VERSION ""

NS_ :

BS_:

BU_: ETH

BO_ 989 CP_loggingSlow: 8 Vector__XXX
 SG_ CP_loggingSlowSelect M : 0|4@1+ (1,0) [0|0] "" Vector__XXX
 SG_ CP_UHF_chipState m3 : 4|3@1+ (1,0) [0|0] "" Vector__XXX
 SG_ CP_backCoverCounts m1 : 4|12@1+ (0.025,0) [0|0] "" Vector__XXX
 SG_ CP_nvm_dataValid m5 : 4|1@1+ (1,0) [0|0] "" Vector__XXX
 SG_ CP_pilotLowValue_intervalMax10s m2 : 4|12@1- (0.01,0) [0|0] "" Vector__XXX
 SG_ CP_proximityV_intervalMax10s m0 : 4|16@1+ (0.0001,0) [0|0] "" Vector__XXX
 SG_ CP_5vSwV m4 : 8|8@1+ (0.01968504,0) [0|0] "" Vector__XXX
 SG_ CP_UHF_rssi m3 : 8|8@1+ (1,0) [0|0] "" Vector__XXX
 SG_ CP_cpuUtilization_intervalMax10s m7 : 8|7@1+ (0.7874015748031497,0) [0|0] "" Vector__XXX
 SG_ CP_nvm_doorOpenCycles m5 : 8|16@1+ (1,0) [0|0] "" Vector__XXX
 SG_ CP_tlsMemoryUsage_intervalMax10s m6 : 8|7@1+ (0.7874015748031497,0) [0|0] "" Vector__XXX
 SG_ CP_UHF_rxOverflow m3 : 16|1@1+ (1,0) [0|0] "" Vector__XXX
 SG_ CP_backCover2Counts m1 : 16|12@1+ (0.025,0) [0|0] "" Vector__XXX
 SG_ CP_boardTemperature m4 : 16|8@1+ (1.29411764706,-50) [0|0] "" Vector__XXX
 SG_ CP_cpuUtilization_intervalMin10s m7 : 16|7@1+ (0.7874015748031497,0) [0|0] "" Vector__XXX
 SG_ CP_pilotLowValue_intervalMin10s m2 : 16|12@1- (0.01,0) [0|0] "" Vector__XXX
 SG_ CP_tlsMemoryUsage_intervalMin10s m6 : 16|7@1+ (0.7874015748031497,0) [0|0] "" Vector__XXX
 SG_ CP_UHF_rxNumBytes m3 : 17|8@1+ (1,0) [0|0] "" Vector__XXX
 SG_ CP_proximityV_intervalMin10s m0 : 20|16@1+ (0.0001,0) [0|0] "" Vector__XXX
 SG_ CP_acRetryTimeoutS m6 : 24|15@1+ (1,0) [0|0] "" Vector__XXX
 SG_ CP_doorButtonPressDurationMs m7 : 24|10@1+ (1,0) [0|0] "" Vector__XXX
 SG_ CP_nvm_doorCloseCycles m5 : 24|16@1+ (1,0) [0|0] "" Vector__XXX
 SG_ CP_refVoltage m4 : 24|8@1+ (0.0070588235,0) [0|0] "" Vector__XXX
 SG_ CP_UHF_selfTestRssi m3 : 25|8@1+ (1,0) [0|0] "" Vector__XXX
 SG_ CP_ivledState m1 : 28|2@1+ (1,0) [0|0] "" Vector__XXX
 SG_ CP_pilotHighValue_intervalMax10s m2 : 28|12@1- (0.01,0) [0|0] "" Vector__XXX
 SG_ CP_doorId_intervalMin10s m4 : 32|8@1+ (0.0196078431372549,0) [0|0] "" Vector__XXX
 SG_ CP_ivledV m1 : 32|8@1+ (0.01968504,0) [0|0] "" Vector__XXX
 SG_ CP_latchI m3 : 33|12@1+ (0.0025,0) [0|0] "" Vector__XXX
 SG_ CP_inductiveSensorBaseline m7 : 34|28@1+ (0.08083879947662354,0) [0|0] "" Vector__XXX
 SG_ CP_inlet1HarnessV m0 : 36|14@1+ (0.001,0) [0|0] "" Vector__XXX
 SG_ CP_acNextRetryTimeoutS m6 : 40|15@1+ (1,0) [0|0] "" Vector__XXX
 SG_ CP_doorId_intervalMax10s m4 : 40|8@1+ (0.0196078431372549,0) [0|0] "" Vector__XXX
 SG_ CP_nvm_doorOpen m5 : 40|1@1+ (1,0) [0|0] "" Vector__XXX
 SG_ CP_pilotHighValue_intervalMin10s m2 : 40|12@1- (0.01,0) [0|0] "" Vector__XXX
 SG_ CP_plcV m1 : 40|8@1+ (0.01294118,0) [0|0] "" Vector__XXX
 SG_ CP_nvm_doorPresent m5 : 41|1@1+ (1,0) [0|0] "" Vector__XXX
 SG_ CP_nvm_doorPresentValid m5 : 42|1@1+ (1,0) [0|0] "" Vector__XXX
 SG_ CP_nvm_badPilotDiodeDetected m5 : 43|1@1+ (1,0) [0|0] "" Vector__XXX
 SG_ CP_nvm_pilotDiodeFaultCount m5 : 44|3@1+ (1,0) [0|0] "" Vector__XXX
 SG_ CP_inlet1HarnessIdState m3 : 45|2@1+ (1,0) [0|0] "" Vector__XXX
 SG_ CP_doorOpenLimiterMaxCount m5 : 47|4@1+ (1,0) [0|0] "" Vector__XXX
 SG_ CP_inlet1HarnessIdValue m3 : 47|3@1+ (1,0) [0|0] "" Vector__XXX
 SG_ CP_sensorExtV m1 : 48|8@1+ (0.01968504,0) [0|0] "" Vector__XXX
 SG_ CP_inlet2HarnessIdState m3 : 50|2@1+ (1,0) [0|0] "" Vector__XXX
 SG_ CP_inlet2HarnessV m0 : 50|14@1+ (0.001,0) [0|0] "" Vector__XXX
 SG_ CP_doorOpenLimiterMaxRequestType m5 : 51|4@1+ (1,0) [0|0] "" Vector__XXX
 SG_ CP_faultLineV m2 : 52|10@1+ (0.004550576735092864,0) [0|0] "" Vector__XXX
 SG_ CP_inlet2HarnessIdValue m3 : 52|3@1+ (1,0) [0|0] "" Vector__XXX
 SG_ CP_doorCloseLimiterMaxCount m5 : 55|4@1+ (1,0) [0|0] "" Vector__XXX
 SG_ CP_inletHeaterState m3 : 55|2@1+ (1,0) [0|0] "" Vector__XXX
 SG_ CP_acNumRetries m6 : 56|8@1+ (1,0) [0|0] "" Vector__XXX
 SG_ CP_backCoverState m1 : 56|3@1+ (1,0) [0|0] "" Vector__XXX
 SG_ CP_inletHeaterDuty m3 : 57|7@1+ (1,0) [0|0] "" Vector__XXX
 SG_ CP_backCover2State m1 : 59|3@1+ (1,0) [0|0] "" Vector__XXX
 SG_ CP_doorCloseLimiterMaxRequestType m5 : 59|5@1+ (1,0) [0|0] "" Vector__XXX
 SG_ CP_faultLineSetByCP m2 : 62|1@1+ (1,0) [0|0] "" Vector__XXX

BO_ 990 FC_alertMatrix6: 8 Vector__XXX
 SG_ FC_a321_FCAlertPlaceholder : 0|1@1+ (1,0) [0|0] "" Vector__XXX

BO_ 991 UI_status2: 8 Vector__XXX
 SG_ UI_mobileAppStepCount : 0|16@1+ (1,0) [0|0] "" Vector__XXX
 SG_ UI_userRequestSnapshot : 16|1@1+ (1,0) [0|0] "" Vector__XXX
 SG_ UI_touchDetected : 17|1@1+ (1,0) [0|0] "" Vector__XXX
 SG_ UI_validDeviceForEUSummon : 18|1@1+ (1,0) [0|0] "" Vector__XXX
 SG_ UI_locatedAtHome : 19|1@1+ (1,0) [0|0] "" Vector__XXX
 SG_ UI_locatedAtWork : 20|1@1+ (1,0) [0|0] "" Vector__XXX
 SG_ UI_locatedAtFavorite : 21|1@1+ (1,0) [0|0] "" Vector__XXX
 SG_ UI_displayInDarkMode : 22|1@1+ (1,0) [0|0] "" Vector__XXX
 SG_ UI_userActivity : 23|1@1+ (1,0) [0|0] "" Vector__XXX
 SG_ UI_activeTouchPoints : 24|8@1+ (1,0) [0|0] "" Vector__XXX
 SG_ UI_linkState : 32|2@1+ (1,0) [0|0] "" Vector__XXX
 SG_ UI_sentryModeState : 34|3@1+ (1,0) [0|0] "" Vector__XXX
 SG_ UI_autopilotSentryRequest : 37|1@1+ (1,0) [0|0] "" Vector__XXX
 SG_ UI_mobileAppConnected : 38|1@1+ (1,0) [0|0] "" Vector__XXX
 SG_ UI_autoshiftDRState : 40|3@1+ (1,0) [0|0] "" Vector__XXX
 SG_ UI_wifiBtModuleType : 43|3@1+ (1,0) [0|0] "" Vector__XXX
 SG_ UI_sohHealthStatus : 46|2@1+ (1,0) [0|0] "" Vector__XXX
 SG_ UI_selfParkState : 48|8@1+ (1,0) [0|0] "" Vector__XXX
 SG_ UI_summonDeviceIndex : 56|2@1+ (1,0) [0|0] "" Vector__XXX
 SG_ UI_sentryModeCameraDetection : 58|1@1+ (1,0) [0|0] "" Vector__XXX
 SG_ UI_wakeOnIPActive : 59|1@1+ (1,0) [0|0] "" Vector__XXX
 SG_ UI_sapActive : 60|1@1+ (1,0) [0|0] "" Vector__XXX
 SG_ UI_sapClients : 61|1@1+ (1,0) [0|0] "" Vector__XXX
 SG_ UI_connectivityStandbyActive : 62|1@1+ (1,0) [0|0] "" Vector__XXX

BO_ 994 VCLEFT_lightStatus: 8 Vector__XXX
 SG_ VCLEFT_brakeLightStatus : 0|2@1+ (1,0) [0|0] "" Vector__XXX
 SG_ VCLEFT_tailLightStatus : 2|2@1+ (1,0) [0|0] "" Vector__XXX
 SG_ VCLEFT_turnSignalStatus : 4|2@1+ (1,0) [0|0] "" Vector__XXX
 SG_ VCLEFT_FLMapLightStatus : 6|2@1+ (1,0) [0|0] "" Vector__XXX
 SG_ VCLEFT_FRMapLightStatus : 8|2@1+ (1,0) [0|0] "" Vector__XXX
 SG_ VCLEFT_RLMapLightStatus : 10|2@1+ (1,0) [0|0] "" Vector__XXX
 SG_ VCLEFT_RRMapLightStatus : 12|2@1+ (1,0) [0|0] "" Vector__XXX
 SG_ VCLEFT_FLMapLightSwitchPressed : 14|1@1+ (1,0) [0|0] "" Vector__XXX
 SG_ VCLEFT_FRMapLightSwitchPressed : 15|1@1+ (1,0) [0|0] "" Vector__XXX
 SG_ VCLEFT_RLMapLightSwitchPressed : 16|1@1+ (1,0) [0|0] "" Vector__XXX
 SG_ VCLEFT_RRMapLightSwitchPressed : 17|1@1+ (1,0) [0|0] "" Vector__XXX
 SG_ VCLEFT_leftTurnTrailerLightStatus : 18|2@1+ (1,0) [0|0] "" Vector__XXX
 SG_ VCLEFT_rightTrnTrailerLightStatus : 20|2@1+ (1,0) [0|0] "" Vector__XXX
 SG_ VCLEFT_brakeTrailerLightStatus : 22|2@1+ (1,0) [0|0] "" Vector__XXX
 SG_ VCLEFT_tailTrailerLightStatus : 24|2@1+ (1,0) [0|0] "" Vector__XXX
 SG_ VCLEFT_fogTrailerLightStatus : 26|2@1+ (1,0) [0|0] "" Vector__XXX
 SG_ VCLEFT_frontRideHeight : 28|8@1- (1,0) [0|0] "" Vector__XXX
 SG_ VCLEFT_rearRideHeight : 36|8@1- (1,0) [0|0] "" Vector__XXX
 SG_ VCLEFT_leftDashRGBPowerRequest : 44|1@1+ (1,0) [0|0] "" Vector__XXX
 SG_ VCLEFT_rightDashRGBPowerRequest : 45|1@1+ (1,0) [0|0] "" Vector__XXX
 SG_ VCLEFT_trailerDetected : 46|2@1+ (1,0) [0|0] "" Vector__XXX
 SG_ VCLEFT_rideHeightSensorFault : 48|1@1+ (1,0) [0|0] "" Vector__XXX
 SG_ VCLEFT_reverseTrailerLightStatus : 49|2@1+ (1,0) [0|0] "" Vector__XXX
 SG_ VCLEFT_tailLightOutageStatus : 51|1@1+ (1,0) [0|0] "" Vector__XXX

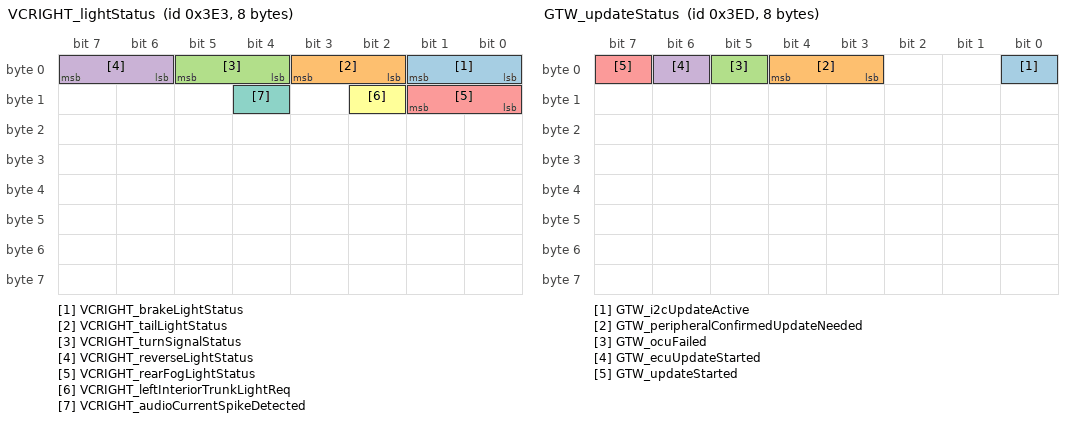
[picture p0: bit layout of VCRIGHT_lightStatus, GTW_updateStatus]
BO_ 995 VCRIGHT_lightStatus: 8 Vector__XXX
 SG_ VCRIGHT_brakeLightStatus : 0|2@1+ (1,0) [0|0] "" Vector__XXX
 SG_ VCRIGHT_tailLightStatus : 2|2@1+ (1,0) [0|0] "" Vector__XXX
 SG_ VCRIGHT_turnSignalStatus : 4|2@1+ (1,0) [0|0] "" Vector__XXX
 SG_ VCRIGHT_reverseLightStatus : 6|2@1+ (1,0) [0|0] "" Vector__XXX
 SG_ VCRIGHT_rearFogLightStatus : 8|2@1+ (1,0) [0|0] "" Vector__XXX
 SG_ VCRIGHT_leftInteriorTrunkLightReq : 10|1@1+ (1,0) [0|0] "" Vector__XXX
 SG_ VCRIGHT_audioCurrentSpikeDetected : 12|1@1+ (1,0) [0|0] "" Vector__XXX

BO_ 996 PCS2_alertMatrix: 8 Vector__XXX
 SG_ PCS2_matrixIndex M : 0|4@1+ (1,0) [0|0] "" Vector__XXX
 SG_ PCS2_a001_watchdogAlarmed m0 : 4|1@1+ (1,0) [0|0] "" Vector__XXX
 SG_ PCS2_a061_cycloBFaulted m1 : 4|1@1+ (1,0) [0|0] "" Vector__XXX
 SG_ PCS2_a121_insufficientCoolingDetected m2 : 4|1@1+ (1,0) [0|0] "" Vector__XXX
 SG_ PCS2_a002_canRationality m0 : 5|1@1+ (1,0) [0|0] "" Vector__XXX
 SG_ PCS2_a062_acVoltageNotPresent m1 : 5|1@1+ (1,0) [0|0] "" Vector__XXX
 SG_ PCS2_a122_dcacLifetimekVAhRecordError m2 : 5|1@1+ (1,0) [0|0] "" Vector__XXX
 SG_ PCS2_a003_softwareAssertion m0 : 6|1@1+ (1,0) [0|0] "" Vector__XXX
 SG_ PCS2_a063_chgUnknownGridConfig m1 : 6|1@1+ (1,0) [0|0] "" Vector__XXX
 SG_ PCS2_a123_DcdcBHvOverTemp m2 : 6|1@1+ (1,0) [0|0] "" Vector__XXX
 SG_ PCS2_a004_acL1NOverVoltage m0 : 7|1@1+ (1,0) [0|0] "" Vector__XXX
 SG_ PCS2_a064_dcdcATankParametersOutOfSpec m1 : 7|1@1+ (1,0) [0|0] "" Vector__XXX
 SG_ PCS2_a124_dcacItankSoftwareOC m2 : 7|1@1+ (1,0) [0|0] "" Vector__XXX
 SG_ PCS2_a005_acL1OverCurrent m0 : 8|1@1+ (1,0) [0|0] "" Vector__XXX
 SG_ PCS2_a065_dcdcBTankParametersOutOfSpec m1 : 8|1@1+ (1,0) [0|0] "" Vector__XXX
 SG_ PCS2_a125_cycloIdleShortingNeutral m2 : 8|1@1+ (1,0) [0|0] "" Vector__XXX
 SG_ PCS2_a006_acL2NOverVoltage m0 : 9|1@1+ (1,0) [0|0] "" Vector__XXX
 SG_ PCS2_a066_cycloATankParametersOutOfSpec m1 : 9|1@1+ (1,0) [0|0] "" Vector__XXX
 SG_ PCS2_a126_ipcSuccessiveLockGrabFailure m2 : 9|1@1+ (1,0) [0|0] "" Vector__XXX
 SG_ PCS2_a007_acL2OverCurrent m0 : 10|1@1+ (1,0) [0|0] "" Vector__XXX
 SG_ PCS2_a067_cycloBTankParametersOutOfSpec m1 : 10|1@1+ (1,0) [0|0] "" Vector__XXX
 SG_ PCS2_a127_cycloAgdpsHealthCheckFailed m2 : 10|1@1+ (1,0) [0|0] "" Vector__XXX
 SG_ PCS2_a008_acL3NOverVoltage m0 : 11|1@1+ (1,0) [0|0] "" Vector__XXX
 SG_ PCS2_a068_nvmSubsystemStalled m1 : 11|1@1+ (1,0) [0|0] "" Vector__XXX
 SG_ PCS2_a128_cycloBgdpsHealthCheckFailed m2 : 11|1@1+ (1,0) [0|0] "" Vector__XXX
 SG_ PCS2_a009_acL3OverCurrent m0 : 12|1@1+ (1,0) [0|0] "" Vector__XXX
 SG_ PCS2_a069_dcdcAlifetimeEnergyRecordFaulty m1 : 12|1@1+ (1,0) [0|0] "" Vector__XXX
 SG_ PCS2_a129_lossOfZcdEventControl m2 : 12|1@1+ (1,0) [0|0] "" Vector__XXX
 SG_ PCS2_a010_acLNOverCurrent m0 : 13|1@1+ (1,0) [0|0] "" Vector__XXX
 SG_ PCS2_a070_dcdcBlifetimeEnergyRecordFaulty m1 : 13|1@1+ (1,0) [0|0] "" Vector__XXX
 SG_ PCS2_a130_IONVMMServerRetryEvent m2 : 13|1@1+ (1,0) [0|0] "" Vector__XXX
 SG_ PCS2_a011_hvdcOverCurrent m0 : 14|1@1+ (1,0) [0|0] "" Vector__XXX
 SG_ PCS2_a071_hvBattBotSensorIrrational m1 : 14|1@1+ (1,0) [0|0] "" Vector__XXX
 SG_ PCS2_a131_microgridHeartbeatDetected m2 : 14|1@1+ (1,0) [0|0] "" Vector__XXX
 SG_ PCS2_a012_cycloATankOverCurrent m0 : 15|1@1+ (1,0) [0|0] "" Vector__XXX
 SG_ PCS2_a072_hvBattTopSensorIrrational m1 : 15|1@1+ (1,0) [0|0] "" Vector__XXX
 SG_ PCS2_a132_microgridDroopDetected m2 : 15|1@1+ (1,0) [0|0] "" Vector__XXX
 SG_ PCS2_a013_DcdcALv2OverTemp m0 : 16|1@1+ (1,0) [0|0] "" Vector__XXX
 SG_ PCS2_a073_hvBusBotSensorIrrational m1 : 16|1@1+ (1,0) [0|0] "" Vector__XXX
 SG_ PCS2_a133_unused m2 : 16|1@1+ (1,0) [0|0] "" Vector__XXX
 SG_ PCS2_a014_cycloBTankOverCurrent m0 : 17|1@1+ (1,0) [0|0] "" Vector__XXX
 SG_ PCS2_a074_hvBusTopSensorIrrational m1 : 17|1@1+ (1,0) [0|0] "" Vector__XXX
 SG_ PCS2_a134_unused m2 : 17|1@1+ (1,0) [0|0] "" Vector__XXX
 SG_ PCS2_a015_DcdcAHvOverTemp m0 : 18|1@1+ (1,0) [0|0] "" Vector__XXX
 SG_ PCS2_a075_hvBattFullSensorIrrational m1 : 18|1@1+ (1,0) [0|0] "" Vector__XXX
 SG_ PCS2_a135_backgroundTaskOverRun m2 : 18|1@1+ (1,0) [0|0] "" Vector__XXX
 SG_ PCS2_a016_dcdcATankOverCurrent m0 : 19|1@1+ (1,0) [0|0] "" Vector__XXX
 SG_ PCS2_a076_hvBusFullSensorIrrational m1 : 19|1@1+ (1,0) [0|0] "" Vector__XXX
 SG_ PCS2_a136_cycloAMosfetHealthCheckFailed m2 : 19|1@1+ (1,0) [0|0] "" Vector__XXX
 SG_ PCS2_a017_DcdcBLv2OverTemp m0 : 20|1@1+ (1,0) [0|0] "" Vector__XXX
 SG_ PCS2_a077_lvBusVoltSensorIrrational m1 : 20|1@1+ (1,0) [0|0] "" Vector__XXX
 SG_ PCS2_a137_cycloBMosfetHealthCheckFailed m2 : 20|1@1+ (1,0) [0|0] "" Vector__XXX
 SG_ PCS2_a018_dcdcBTankOverCurrent m0 : 21|1@1+ (1,0) [0|0] "" Vector__XXX
 SG_ PCS2_a078_acL1NVoltageOffsetIrrational m1 : 21|1@1+ (1,0) [0|0] "" Vector__XXX
 SG_ PCS2_a138_unused m2 : 21|1@1+ (1,0) [0|0] "" Vector__XXX
 SG_ PCS2_a019_DcacADcTempTooHigh m0 : 22|1@1+ (1,0) [0|0] "" Vector__XXX
 SG_ PCS2_a079_acL2NVoltageOffsetIrrational m1 : 22|1@1+ (1,0) [0|0] "" Vector__XXX
 SG_ PCS2_a139_unused m2 : 22|1@1+ (1,0) [0|0] "" Vector__XXX
 SG_ PCS2_a020_DcacBDcTempTooHigh m0 : 23|1@1+ (1,0) [0|0] "" Vector__XXX
 SG_ PCS2_a080_acL3NVoltageOffsetIrrational m1 : 23|1@1+ (1,0) [0|0] "" Vector__XXX
 SG_ PCS2_a140_dcdcHalfBusBalancerSaturated m2 : 23|1@1+ (1,0) [0|0] "" Vector__XXX
 SG_ PCS2_a021_powerRailUnderVoltage m0 : 24|1@1+ (1,0) [0|0] "" Vector__XXX
 SG_ PCS2_a081_acL1CurrentOffsetIrrational m1 : 24|1@1+ (1,0) [0|0] "" Vector__XXX
 SG_ PCS2_a141_boostOverCurrent m2 : 24|1@1+ (1,0) [0|0] "" Vector__XXX
 SG_ PCS2_a022_dcacEnableFunctionalityDisabled m0 : 25|1@1+ (1,0) [0|0] "" Vector__XXX
 SG_ PCS2_a082_acL2CurrentOffsetIrrational m1 : 25|1@1+ (1,0) [0|0] "" Vector__XXX
 SG_ PCS2_a142_AcLineGdpsUncalibrated m2 : 25|1@1+ (1,0) [0|0] "" Vector__XXX
 SG_ PCS2_a023_dcdcEnableFunctionalityDisabled m0 : 26|1@1+ (1,0) [0|0] "" Vector__XXX
 SG_ PCS2_a083_acL3CurrentOffsetIrrational m1 : 26|1@1+ (1,0) [0|0] "" Vector__XXX
 SG_ PCS2_a143_AcTankGdpsUncalibrated m2 : 26|1@1+ (1,0) [0|0] "" Vector__XXX
 SG_ PCS2_a024_DcacATxTempTooHigh m0 : 27|1@1+ (1,0) [0|0] "" Vector__XXX
 SG_ PCS2_a084_acNCurrentOffsetIrrational m1 : 27|1@1+ (1,0) [0|0] "" Vector__XXX
 SG_ PCS2_a144_DcTankGdpsUncalibrated m2 : 27|1@1+ (1,0) [0|0] "" Vector__XXX
 SG_ PCS2_a025_DcacBTxTempTooHigh m0 : 28|1@1+ (1,0) [0|0] "" Vector__XXX
 SG_ PCS2_a085_dcacEnableLineDeasserted m1 : 28|1@1+ (1,0) [0|0] "" Vector__XXX
 SG_ PCS2_a145_DcdcHvdcGdpsUncalibrated m2 : 28|1@1+ (1,0) [0|0] "" Vector__XXX
 SG_ PCS2_a026_AcConnectorTempTooHigh m0 : 29|1@1+ (1,0) [0|0] "" Vector__XXX
 SG_ PCS2_a086_dcacLVUnderVoltage m1 : 29|1@1+ (1,0) [0|0] "" Vector__XXX
 SG_ PCS2_a146_acLineSharedCurrentConnectionIssue m2 : 29|1@1+ (1,0) [0|0] "" Vector__XXX
 SG_ PCS2_a027_AmbientTempTooHigh m0 : 30|1@1+ (1,0) [0|0] "" Vector__XXX
 SG_ PCS2_a087_dcacLVOverVoltage m1 : 30|1@1+ (1,0) [0|0] "" Vector__XXX
 SG_ PCS2_a147_powerRailOverVoltage m2 : 30|1@1+ (1,0) [0|0] "" Vector__XXX
 SG_ PCS2_a028_CoolantTempTooHigh m0 : 31|1@1+ (1,0) [0|0] "" Vector__XXX
 SG_ PCS2_a088_chgInputVDropHigh m1 : 31|1@1+ (1,0) [0|0] "" Vector__XXX
 SG_ PCS2_a148_acRelayVoltageIrrational m2 : 31|1@1+ (1,0) [0|0] "" Vector__XXX
 SG_ PCS2_a029_DcacAAc1TempTooHigh m0 : 32|1@1+ (1,0) [0|0] "" Vector__XXX
 SG_ PCS2_a089_EndOfLineModeActivated m1 : 32|1@1+ (1,0) [0|0] "" Vector__XXX
 SG_ PCS2_a149_buckBoostFault m2 : 32|1@1+ (1,0) [0|0] "" Vector__XXX
 SG_ PCS2_a030_DcacAAc2TempTooHigh m0 : 33|1@1+ (1,0) [0|0] "" Vector__XXX
 SG_ PCS2_a090_DcdcLvMosfetTempTooHigh m1 : 33|1@1+ (1,0) [0|0] "" Vector__XXX
 SG_ PCS2_a150_dcdcBurstTimingNotMet m2 : 33|1@1+ (1,0) [0|0] "" Vector__XXX
 SG_ PCS2_a031_DcacBAc1TempTooHigh m0 : 34|1@1+ (1,0) [0|0] "" Vector__XXX
 SG_ PCS2_a091_DcdcTxWindingTempTooHigh m1 : 34|1@1+ (1,0) [0|0] "" Vector__XXX
 SG_ PCS2_a151_DcdcBLv1OverTemp m2 : 34|1@1+ (1,0) [0|0] "" Vector__XXX
 SG_ PCS2_a032_DcacBAc2TempTooHigh m0 : 35|1@1+ (1,0) [0|0] "" Vector__XXX
 SG_ PCS2_a092_dcdc_itankZcdIrrational m1 : 35|1@1+ (1,0) [0|0] "" Vector__XXX
 SG_ PCS2_a152_DcdcBLv3OverTemp m2 : 35|1@1+ (1,0) [0|0] "" Vector__XXX
 SG_ PCS2_a033_swCoreExcessiveUsage m0 : 36|1@1+ (1,0) [0|0] "" Vector__XXX
 SG_ PCS2_a093_cycloPwmsNotInterleaved m1 : 36|1@1+ (1,0) [0|0] "" Vector__XXX
 SG_ PCS2_a153_cyclo_itankZcdIrrational m2 : 36|1@1+ (1,0) [0|0] "" Vector__XXX
 SG_ PCS2_a034_lvBusOverVoltage m0 : 37|1@1+ (1,0) [0|0] "" Vector__XXX
 SG_ PCS2_a094_acChargingUnavailable m1 : 37|1@1+ (1,0) [0|0] "" Vector__XXX
 SG_ PCS2_a154_adcReferenceUncalibrated m2 : 37|1@1+ (1,0) [0|0] "" Vector__XXX
 SG_ PCS2_a035_lvBusUnderVoltage m0 : 38|1@1+ (1,0) [0|0] "" Vector__XXX
 SG_ PCS2_a095_powershareUnavailable m1 : 38|1@1+ (1,0) [0|0] "" Vector__XXX
 SG_ PCS2_a155_vcbatteryMia m2 : 38|1@1+ (1,0) [0|0] "" Vector__XXX
 SG_ PCS2_a036_hvBusOverVoltage m0 : 39|1@1+ (1,0) [0|0] "" Vector__XXX
 SG_ PCS2_a096_vcsuperMia m1 : 39|1@1+ (1,0) [0|0] "" Vector__XXX
 SG_ PCS2_a156_vcfrontMia m2 : 39|1@1+ (1,0) [0|0] "" Vector__XXX
 SG_ PCS2_a037_hvBusUnderVoltage m0 : 40|1@1+ (1,0) [0|0] "" Vector__XXX
 SG_ PCS2_a097_gtwMia m1 : 40|1@1+ (1,0) [0|0] "" Vector__XXX
 SG_ PCS2_a157_VC_pcsManagementMia m2 : 40|1@1+ (1,0) [0|0] "" Vector__XXX
 SG_ PCS2_a038_hvBusTopOverVoltage m0 : 41|1@1+ (1,0) [0|0] "" Vector__XXX
 SG_ PCS2_a098_eggright3Mia m1 : 41|1@1+ (1,0) [0|0] "" Vector__XXX
 SG_ PCS2_a158_DcdcHvMosfetTempTooHigh m2 : 41|1@1+ (1,0) [0|0] "" Vector__XXX
 SG_ PCS2_a039_hvBusTopUnderVoltage m0 : 42|1@1+ (1,0) [0|0] "" Vector__XXX
 SG_ PCS2_a099_LineChassisRmsOV m1 : 42|1@1+ (1,0) [0|0] "" Vector__XXX
 SG_ PCS2_a159_dcdcGdpsHealthCheckFailed m2 : 42|1@1+ (1,0) [0|0] "" Vector__XXX
 SG_ PCS2_a040_hvBusBotOverVoltage m0 : 43|1@1+ (1,0) [0|0] "" Vector__XXX
 SG_ PCS2_a100_LineToLineRmsOV m1 : 43|1@1+ (1,0) [0|0] "" Vector__XXX
 SG_ PCS2_a160_vcleftMia m2 : 43|1@1+ (1,0) [0|0] "" Vector__XXX
 SG_ PCS2_a041_hvBusBotUnderVoltage m0 : 44|1@1+ (1,0) [0|0] "" Vector__XXX
 SG_ PCS2_a101_LineChassisInstantaneousOV m1 : 44|1@1+ (1,0) [0|0] "" Vector__XXX
 SG_ PCS2_a161_vcrearMia m2 : 44|1@1+ (1,0) [0|0] "" Vector__XXX
 SG_ PCS2_a042_hvBattOverVoltage m0 : 45|1@1+ (1,0) [0|0] "" Vector__XXX
 SG_ PCS2_a102_LineToLineInstantaneousOV m1 : 45|1@1+ (1,0) [0|0] "" Vector__XXX
 SG_ PCS2_a162_cycloARoutineTankInductanceMeasurement m2 : 45|1@1+ (1,0) [0|0] "" Vector__XXX
 SG_ PCS2_a043_hvBattUnderVoltage m0 : 46|1@1+ (1,0) [0|0] "" Vector__XXX
 SG_ PCS2_a103_IsoTempSensorIrrational m1 : 46|1@1+ (1,0) [0|0] "" Vector__XXX
 SG_ PCS2_a163_cycloBRoutineTankInductanceMeasurement m2 : 46|1@1+ (1,0) [0|0] "" Vector__XXX
 SG_ PCS2_a044_hvBattTopOverVoltage m0 : 47|1@1+ (1,0) [0|0] "" Vector__XXX
 SG_ PCS2_a104_LineChassisRmsUV m1 : 47|1@1+ (1,0) [0|0] "" Vector__XXX
 SG_ PCS2_a164_dcdc_hwZcdFault1 m2 : 47|1@1+ (1,0) [0|0] "" Vector__XXX
 SG_ PCS2_a045_hvBattTopUnderVoltage m0 : 48|1@1+ (1,0) [0|0] "" Vector__XXX
 SG_ PCS2_a105_LineToLineRmsUV m1 : 48|1@1+ (1,0) [0|0] "" Vector__XXX
 SG_ PCS2_a165_dcdc_hwZcdFault2 m2 : 48|1@1+ (1,0) [0|0] "" Vector__XXX
 SG_ PCS2_a046_hvBattBotOverVoltage m0 : 49|1@1+ (1,0) [0|0] "" Vector__XXX
 SG_ PCS2_a106_systemNeutralChassisRmsOV m1 : 49|1@1+ (1,0) [0|0] "" Vector__XXX
 SG_ PCS2_a166_dcdcEnableLinePWMTripMisconfigured m2 : 49|1@1+ (1,0) [0|0] "" Vector__XXX
 SG_ PCS2_a047_hvBattBotUnderVoltage m0 : 50|1@1+ (1,0) [0|0] "" Vector__XXX
 SG_ PCS2_a107_cycloLostCurrentControl m1 : 50|1@1+ (1,0) [0|0] "" Vector__XXX
 SG_ PCS2_a167_unused m2 : 50|1@1+ (1,0) [0|0] "" Vector__XXX
 SG_ PCS2_a048_dcacOverVoltage m0 : 51|1@1+ (1,0) [0|0] "" Vector__XXX
 SG_ PCS2_a108_FunctionalTestModeActivated m1 : 51|1@1+ (1,0) [0|0] "" Vector__XXX
 SG_ PCS2_a168_gridFormVoltageDropped m2 : 51|1@1+ (1,0) [0|0] "" Vector__XXX
 SG_ PCS2_a049_dcacUnderVoltage m0 : 52|1@1+ (1,0) [0|0] "" Vector__XXX
 SG_ PCS2_a109_ACSurgeProtectionTriggered m1 : 52|1@1+ (1,0) [0|0] "" Vector__XXX
 SG_ PCS2_a169_cycloMosfetHealthCheckMeasuredHalfPrdAsymmetric m2 : 52|1@1+ (1,0) [0|0] "" Vector__XXX
 SG_ PCS2_a050_vcPcsDCDCInterfaceMia m0 : 53|1@1+ (1,0) [0|0] "" Vector__XXX
 SG_ PCS2_a110_acCurrentIsLimited m1 : 53|1@1+ (1,0) [0|0] "" Vector__XXX
 SG_ PCS2_a170_unused m2 : 53|1@1+ (1,0) [0|0] "" Vector__XXX
 SG_ PCS2_a051_bmsMia m0 : 54|1@1+ (1,0) [0|0] "" Vector__XXX
 SG_ PCS2_a111_unused m1 : 54|1@1+ (1,0) [0|0] "" Vector__XXX
 SG_ PCS2_a171_unused m2 : 54|1@1+ (1,0) [0|0] "" Vector__XXX
 SG_ PCS2_a052_cpMia m0 : 55|1@1+ (1,0) [0|0] "" Vector__XXX
 SG_ PCS2_a112_chgInputVDropTooHigh m1 : 55|1@1+ (1,0) [0|0] "" Vector__XXX
 SG_ PCS2_a172_llcDcdcLvBusContention m2 : 55|1@1+ (1,0) [0|0] "" Vector__XXX
 SG_ PCS2_a053_hvDcdcControlMIA m0 : 56|1@1+ (1,0) [0|0] "" Vector__XXX
 SG_ PCS2_a113_dcdcTransientCapabilityImpacted m1 : 56|1@1+ (1,0) [0|0] "" Vector__XXX
 SG_ PCS2_a173_unused m2 : 56|1@1+ (1,0) [0|0] "" Vector__XXX
 SG_ PCS2_a054_uiMia m0 : 57|1@1+ (1,0) [0|0] "" Vector__XXX
 SG_ PCS2_a114_hvBusEstimatedImpedanceLow m1 : 57|1@1+ (1,0) [0|0] "" Vector__XXX
 SG_ PCS2_a174_unused m2 : 57|1@1+ (1,0) [0|0] "" Vector__XXX
 SG_ PCS2_a055_dcdcATankUncalibrated m0 : 58|1@1+ (1,0) [0|0] "" Vector__XXX
 SG_ PCS2_a115_chgWallPowerRemoval m1 : 58|1@1+ (1,0) [0|0] "" Vector__XXX
 SG_ PCS2_a175_LVUVSurgePowerEvent m2 : 58|1@1+ (1,0) [0|0] "" Vector__XXX
 SG_ PCS2_a056_dcdcBTankUncalibrated m0 : 59|1@1+ (1,0) [0|0] "" Vector__XXX
 SG_ PCS2_a116_chgPersistentFault m1 : 59|1@1+ (1,0) [0|0] "" Vector__XXX
 SG_ PCS2_a057_cycloATankUncalibrated m0 : 60|1@1+ (1,0) [0|0] "" Vector__XXX
 SG_ PCS2_a117_vcrightMia m1 : 60|1@1+ (1,0) [0|0] "" Vector__XXX
 SG_ PCS2_a058_cycloBTankUncalibrated m0 : 61|1@1+ (1,0) [0|0] "" Vector__XXX
 SG_ PCS2_a118_dcdcFailedToPrechargeToTarget m1 : 61|1@1+ (1,0) [0|0] "" Vector__XXX
 SG_ PCS2_a059_dcdcEnableLineDeasserted m0 : 62|1@1+ (1,0) [0|0] "" Vector__XXX
 SG_ PCS2_a119_useMaxCapForHvImpedanceEstimation m1 : 62|1@1+ (1,0) [0|0] "" Vector__XXX
 SG_ PCS2_a060_cycloAFaulted m0 : 63|1@1+ (1,0) [0|0] "" Vector__XXX
 SG_ PCS2_a120_triggerOdin m1 : 63|1@1+ (1,0) [0|0] "" Vector__XXX

BO_ 997 DIR_alertMatrix4: 8 Vector__XXX
 SG_ DIR_a202_excessHeatUnavailable : 9|1@1+ (1,0) [0|0] "" Vector__XXX
 SG_ DIR_a225_tmpEstPlausibility : 32|1@1+ (1,0) [0|0] "" Vector__XXX
 SG_ DIR_a229_busVsensorOverCAN : 36|1@1+ (1,0) [0|0] "" Vector__XXX
 SG_ DIR_a233_diMsgMissed : 40|1@1+ (1,0) [0|0] "" Vector__XXX
 SG_ DIR_a234_pcsMIA : 41|1@1+ (1,0) [0|0] "" Vector__XXX
 SG_ DIR_a236_tasMIA : 43|1@1+ (1,0) [0|0] "" Vector__XXX
 SG_ DIR_a240_clearFusesRoutine : 47|1@1+ (1,0) [0|0] "" Vector__XXX
 SG_ DIR_a241_systemThermallyLimited : 48|1@1+ (1,0) [0|0] "" Vector__XXX
 SG_ DIR_a242_spinDownLearning : 49|1@1+ (1,0) [0|0] "" Vector__XXX
 SG_ DIR_a243_ecuLogAvailable : 50|1@1+ (1,0) [0|0] "" Vector__XXX
 SG_ DIR_a244_mechSafeStateApplied : 51|1@1+ (1,0) [0|0] "" Vector__XXX
 SG_ DIR_a245_mechSafeStatePreWarn : 52|1@1+ (1,0) [0|0] "" Vector__XXX
 SG_ DIR_a246_recoveryAtSpeedError : 53|1@1+ (1,0) [0|0] "" Vector__XXX
 SG_ DIR_a247_rotorOffsetError : 54|1@1+ (1,0) [0|0] "" Vector__XXX
 SG_ DIR_a248_vehicleSpeedLimited : 55|1@1+ (1,0) [0|0] "" Vector__XXX
 SG_ DIR_a249_highStatorTempFromResist : 56|1@1+ (1,0) [0|0] "" Vector__XXX
 SG_ DIR_a250_preregulatorRail : 57|1@1+ (1,0) [0|0] "" Vector__XXX
 SG_ DIR_a251_oilPumpService : 58|1@1+ (1,0) [0|0] "" Vector__XXX
 SG_ DIR_a252_currentCoreFallback : 59|1@1+ (1,0) [0|0] "" Vector__XXX
 SG_ DIR_a253_lvBoostedRail : 60|1@1+ (1,0) [0|0] "" Vector__XXX
 SG_ DIR_a254_activeDischargeRail : 61|1@1+ (1,0) [0|0] "" Vector__XXX
 SG_ DIR_a255_currentGainFallback : 62|1@1+ (1,0) [0|0] "" Vector__XXX

BO_ 1000 EPBR_alertMatrix: 8 Vector__XXX
 SG_ EPBR_matrixIndex M : 0|4@1+ (1,0) [0|0] "" Vector__XXX
 SG_ EPBR_a001_WatchdogReset m0 : 4|1@1+ (1,0) [0|0] "" Vector__XXX
 SG_ EPBR_a061_XCPConnected m1 : 4|1@1+ (1,0) [0|0] "" Vector__XXX
 SG_ EPBR_a121_nDriveFault m2 : 4|1@1+ (1,0) [0|0] "" Vector__XXX
 SG_ EPBR_a181_TooSteepGradeToPark m3 : 4|1@1+ (1,0) [0|0] "" Vector__XXX
 SG_ EPBR_a241_diOutputLocked m4 : 4|1@1+ (1,0) [0|0] "" Vector__XXX
 SG_ EPBR_a301_oocSpeedViolation m5 : 4|1@1+ (1,0) [0|0] "" Vector__XXX
 SG_ EPBR_a361_espBrakeSwitchInvalid m6 : 4|1@1+ (1,0) [0|0] "" Vector__XXX
 SG_ EPBR_a002_PowerLossReset m0 : 5|1@1+ (1,0) [0|0] "" Vector__XXX
 SG_ EPBR_a062_XCPWasConnected m1 : 5|1@1+ (1,0) [0|0] "" Vector__XXX
 SG_ EPBR_a122_Oc m2 : 5|1@1+ (1,0) [0|0] "" Vector__XXX
 SG_ EPBR_a182_OneEPBAppliedUnsecEnv m3 : 5|1@1+ (1,0) [0|0] "" Vector__XXX
 SG_ EPBR_a242_hvOutputLocked m4 : 5|1@1+ (1,0) [0|0] "" Vector__XXX
 SG_ EPBR_a302_csmLongRelease m5 : 5|1@1+ (1,0) [0|0] "" Vector__XXX
 SG_ EPBR_a362_ibstPressedEspNotPressedMismatch m6 : 5|1@1+ (1,0) [0|0] "" Vector__XXX
 SG_ EPBR_a003_SWAssertion m0 : 6|1@1+ (1,0) [0|0] "" Vector__XXX
 SG_ EPBR_a063_SwitchFault m1 : 6|1@1+ (1,0) [0|0] "" Vector__XXX
 SG_ EPBR_a123_Uc m2 : 6|1@1+ (1,0) [0|0] "" Vector__XXX
 SG_ EPBR_a183_cdpNotAvailable m3 : 6|1@1+ (1,0) [0|0] "" Vector__XXX
 SG_ EPBR_a243_bdwUnavailable m4 : 6|1@1+ (1,0) [0|0] "" Vector__XXX
 SG_ EPBR_a303_clampingOccuredEarly m5 : 6|1@1+ (1,0) [0|0] "" Vector__XXX
 SG_ EPBR_a363_ibstNotPressedEspPressedMismatch m6 : 6|1@1+ (1,0) [0|0] "" Vector__XXX
 SG_ EPBR_a064_busSleepReqTimeout m1 : 7|1@1+ (1,0) [0|0] "" Vector__XXX
 SG_ EPBR_a124_calOutOfBounds m2 : 7|1@1+ (1,0) [0|0] "" Vector__XXX
 SG_ EPBR_a184_dynamicParkAbort m3 : 7|1@1+ (1,0) [0|0] "" Vector__XXX
 SG_ EPBR_a244_WinchModeActive m4 : 7|1@1+ (1,0) [0|0] "" Vector__XXX
 SG_ EPBR_a304_rearSeatControllerEFuseTrip m5 : 7|1@1+ (1,0) [0|0] "" Vector__XXX
 SG_ EPBR_a364_espMasterCylCompOverThreshold m6 : 7|1@1+ (1,0) [0|0] "" Vector__XXX
 SG_ EPBR_a005_CANTXError m0 : 8|1@1+ (1,0) [0|0] "" Vector__XXX
 SG_ EPBR_a125_IdleVMismatch m2 : 8|1@1+ (1,0) [0|0] "" Vector__XXX
 SG_ EPBR_a185_summonAborted m3 : 8|1@1+ (1,0) [0|0] "" Vector__XXX
 SG_ EPBR_a245_serviceModeActive m4 : 8|1@1+ (1,0) [0|0] "" Vector__XXX
 SG_ EPBR_a305_premiumAmpEFuseTrip m5 : 8|1@1+ (1,0) [0|0] "" Vector__XXX
 SG_ EPBR_a365_TooSteepToParkWithTrailerWarning m6 : 8|1@1+ (1,0) [0|0] "" Vector__XXX
 SG_ EPBR_a006_CANTX_cyclicError m0 : 9|1@1+ (1,0) [0|0] "" Vector__XXX
 SG_ EPBR_a126_MotorNVoltLow m2 : 9|1@1+ (1,0) [0|0] "" Vector__XXX
 SG_ EPBR_a186_externalParkAbort m3 : 9|1@1+ (1,0) [0|0] "" Vector__XXX
 SG_ EPBR_a246_idleFaultApply m4 : 9|1@1+ (1,0) [0|0] "" Vector__XXX
 SG_ EPBR_a366_TooSteepToParkWithTrailerUnSecEnv m6 : 9|1@1+ (1,0) [0|0] "" Vector__XXX
 SG_ EPBR_a127_MotorNVoltHigh m2 : 10|1@1+ (1,0) [0|0] "" Vector__XXX
 SG_ EPBR_a187_cdpDynamic m3 : 10|1@1+ (1,0) [0|0] "" Vector__XXX
 SG_ EPBR_a247_csmDynamicApplyRetry m4 : 10|1@1+ (1,0) [0|0] "" Vector__XXX
 SG_ EPBR_a128_MotorPVoltHigh m2 : 11|1@1+ (1,0) [0|0] "" Vector__XXX
 SG_ EPBR_a188_epbDynamic m3 : 11|1@1+ (1,0) [0|0] "" Vector__XXX
 SG_ EPBR_a248_csmDynamicApplyFailed m4 : 11|1@1+ (1,0) [0|0] "" Vector__XXX
 SG_ EPBR_a129_ICR_MIA m2 : 12|1@1+ (1,0) [0|0] "" Vector__XXX
 SG_ EPBR_a189_epbDynamicParkCanceled m3 : 12|1@1+ (1,0) [0|0] "" Vector__XXX
 SG_ EPBR_a249_idleFaultRelease m4 : 12|1@1+ (1,0) [0|0] "" Vector__XXX
 SG_ EPBR_a190_csmApplyDegraded m3 : 13|1@1+ (1,0) [0|0] "" Vector__XXX
 SG_ EPBR_a250_WinchModeCanceled m4 : 13|1@1+ (1,0) [0|0] "" Vector__XXX
 SG_ EPBR_a191_csmReleaseDegraded m3 : 14|1@1+ (1,0) [0|0] "" Vector__XXX
 SG_ EPBR_a251_currentVarianceHigh m4 : 14|1@1+ (1,0) [0|0] "" Vector__XXX
 SG_ EPBR_a012_CPUReset m0 : 15|1@1+ (1,0) [0|0] "" Vector__XXX
 SG_ EPBR_a252_winchModePending m4 : 15|1@1+ (1,0) [0|0] "" Vector__XXX
 SG_ EPBR_a013_AlertManagerFault m0 : 16|1@1+ (1,0) [0|0] "" Vector__XXX
 SG_ EPBR_a253_esmReleaseBlocked m4 : 16|1@1+ (1,0) [0|0] "" Vector__XXX
 SG_ EPBR_a134_NvOv m2 : 17|1@1+ (1,0) [0|0] "" Vector__XXX
 SG_ EPBR_a254_showStalkParkButtonFaultOnUi m4 : 17|1@1+ (1,0) [0|0] "" Vector__XXX
 SG_ EPBR_a015_NVMMError m0 : 18|1@1+ (1,0) [0|0] "" Vector__XXX
 SG_ EPBR_a135_NvUv m2 : 18|1@1+ (1,0) [0|0] "" Vector__XXX
 SG_ EPBR_a195_parkForDriverIsLeaving m3 : 18|1@1+ (1,0) [0|0] "" Vector__XXX
 SG_ EPBR_a016_NVMMRecordError m0 : 19|1@1+ (1,0) [0|0] "" Vector__XXX
 SG_ EPBR_a136_PvOv m2 : 19|1@1+ (1,0) [0|0] "" Vector__XXX
 SG_ EPBR_a196_freeRollModeActive m3 : 19|1@1+ (1,0) [0|0] "" Vector__XXX
 SG_ EPBR_a256_epbSystemApply m4 : 19|1@1+ (1,0) [0|0] "" Vector__XXX
 SG_ EPBR_a137_PvUv m2 : 20|1@1+ (1,0) [0|0] "" Vector__XXX
 SG_ EPBR_a197_freeRollModeAtSpeed m3 : 20|1@1+ (1,0) [0|0] "" Vector__XXX
 SG_ EPBR_a138_NvmDualFailure m2 : 21|1@1+ (1,0) [0|0] "" Vector__XXX
 SG_ EPBR_a198_holdClampComplete m3 : 21|1@1+ (1,0) [0|0] "" Vector__XXX
 SG_ EPBR_a139_NvmRedundancyLoss m2 : 22|1@1+ (1,0) [0|0] "" Vector__XXX
 SG_ EPBR_a140_NvmSlowWrite m2 : 23|1@1+ (1,0) [0|0] "" Vector__XXX
 SG_ EPBR_a200_PmUnparkNotAllowed m3 : 23|1@1+ (1,0) [0|0] "" Vector__XXX
 SG_ EPBR_a021_TaskSchedulerError m0 : 24|1@1+ (1,0) [0|0] "" Vector__XXX
 SG_ EPBR_a081_APP_MIA m1 : 24|1@1+ (1,0) [0|0] "" Vector__XXX
 SG_ EPBR_a141_invalidState m2 : 24|1@1+ (1,0) [0|0] "" Vector__XXX
 SG_ EPBR_a261_winchModeWithoutSteering m4 : 24|1@1+ (1,0) [0|0] "" Vector__XXX
 SG_ EPBR_a022_TaskInitError m0 : 25|1@1+ (1,0) [0|0] "" Vector__XXX
 SG_ EPBR_a082_VCRIGHT_IPC_MIA m1 : 25|1@1+ (1,0) [0|0] "" Vector__XXX
 SG_ EPBR_a202_remoteEpbConfigIncompatible m3 : 25|1@1+ (1,0) [0|0] "" Vector__XXX
 SG_ EPBR_a262_cannotPrepareWinchMode m4 : 25|1@1+ (1,0) [0|0] "" Vector__XXX
 SG_ EPBR_a083_VCLEFT_IPC_MIA m1 : 26|1@1+ (1,0) [0|0] "" Vector__XXX
 SG_ EPBR_a203_hwBrakeTypeMismatch m3 : 26|1@1+ (1,0) [0|0] "" Vector__XXX
 SG_ EPBR_a263_epbRecoveryPark m4 : 26|1@1+ (1,0) [0|0] "" Vector__XXX
 SG_ EPBR_a084_TPMS_MIA m1 : 27|1@1+ (1,0) [0|0] "" Vector__XXX
 SG_ EPBR_a264_winchModeDeactivated m4 : 27|1@1+ (1,0) [0|0] "" Vector__XXX
 SG_ EPBR_a085_CCCM_MIA m1 : 28|1@1+ (1,0) [0|0] "" Vector__XXX
 SG_ EPBR_a086_VCBATT_MIA m1 : 29|1@1+ (1,0) [0|0] "" Vector__XXX
 SG_ EPBR_a087_DIREL_MIA m1 : 30|1@1+ (1,0) [0|0] "" Vector__XXX
 SG_ EPBR_a088_DIRER_MIA m1 : 31|1@1+ (1,0) [0|0] "" Vector__XXX
 SG_ EPBR_a029_CoreDump m0 : 32|1@1+ (1,0) [0|0] "" Vector__XXX
 SG_ EPBR_a089_IBST_MIA m1 : 32|1@1+ (1,0) [0|0] "" Vector__XXX
 SG_ EPBR_a030_ECULogUploadRequest m0 : 33|1@1+ (1,0) [0|0] "" Vector__XXX
 SG_ EPBR_a090_APS_MIA m1 : 33|1@1+ (1,0) [0|0] "" Vector__XXX
 SG_ EPBR_a210_parkForDriverIsLeavingDebug m3 : 33|1@1+ (1,0) [0|0] "" Vector__XXX
 SG_ EPBR_a031_UDSActive m0 : 34|1@1+ (1,0) [0|0] "" Vector__XXX
 SG_ EPBR_a091_CMPD_MIA m1 : 34|1@1+ (1,0) [0|0] "" Vector__XXX
 SG_ EPBR_a092_VCSEATD_MIA m1 : 35|1@1+ (1,0) [0|0] "" Vector__XXX
 SG_ EPBR_a272_vhclPwrStateMsmtch m4 : 35|1@1+ (1,0) [0|0] "" Vector__XXX
 SG_ EPBR_a093_VCSEATP_MIA m1 : 36|1@1+ (1,0) [0|0] "" Vector__XXX
 SG_ EPBR_a094_EPAS3P_MIA m1 : 37|1@1+ (1,0) [0|0] "" Vector__XXX
 SG_ EPBR_a095_CHG_MIA m1 : 38|1@1+ (1,0) [0|0] "" Vector__XXX
 SG_ EPBR_a096_OCS1P_MIA m1 : 39|1@1+ (1,0) [0|0] "" Vector__XXX
 SG_ EPBR_a216_SPI_MIA_debugData1 m3 : 39|1@1+ (1,0) [0|0] "" Vector__XXX
 SG_ EPBR_a097_CMP_MIA m1 : 40|1@1+ (1,0) [0|0] "" Vector__XXX
 SG_ EPBR_a217_SPI_MIA_debugData2 m3 : 40|1@1+ (1,0) [0|0] "" Vector__XXX
 SG_ EPBR_a098_DIR_MIA m1 : 41|1@1+ (1,0) [0|0] "" Vector__XXX
 SG_ EPBR_a099_PARK_MIA m1 : 42|1@1+ (1,0) [0|0] "" Vector__XXX
 SG_ EPBR_a100_CANbus_MIA m1 : 43|1@1+ (1,0) [0|0] "" Vector__XXX
 SG_ EPBR_a041_HighCPULoad m0 : 44|1@1+ (1,0) [0|0] "" Vector__XXX
 SG_ EPBR_a101_PM_MIA m1 : 44|1@1+ (1,0) [0|0] "" Vector__XXX
 SG_ EPBR_a042_HighStackUsage m0 : 45|1@1+ (1,0) [0|0] "" Vector__XXX
 SG_ EPBR_a102_PTC_MIA m1 : 45|1@1+ (1,0) [0|0] "" Vector__XXX
 SG_ EPBR_a043_Task1msError m0 : 46|1@1+ (1,0) [0|0] "" Vector__XXX
 SG_ EPBR_a103_CP_MIA m1 : 46|1@1+ (1,0) [0|0] "" Vector__XXX
 SG_ EPBR_a044_Task10msError m0 : 47|1@1+ (1,0) [0|0] "" Vector__XXX
 SG_ EPBR_a104_DAS_MIA m1 : 47|1@1+ (1,0) [0|0] "" Vector__XXX
 SG_ EPBR_a045_Task100msError m0 : 48|1@1+ (1,0) [0|0] "" Vector__XXX
 SG_ EPBR_a105_TAS_MIA m1 : 48|1@1+ (1,0) [0|0] "" Vector__XXX
 SG_ EPBR_a225_epbActiveDecel m3 : 48|1@1+ (1,0) [0|0] "" Vector__XXX
 SG_ EPBR_a046_Task1000msError m0 : 49|1@1+ (1,0) [0|0] "" Vector__XXX
 SG_ EPBR_a106_PCS_MIA m1 : 49|1@1+ (1,0) [0|0] "" Vector__XXX
 SG_ EPBR_a107_BMS_MIA m1 : 50|1@1+ (1,0) [0|0] "" Vector__XXX
 SG_ EPBR_a108_DIF_MIA m1 : 51|1@1+ (1,0) [0|0] "" Vector__XXX
 SG_ EPBR_a109_RCM_MIA m1 : 52|1@1+ (1,0) [0|0] "" Vector__XXX
 SG_ EPBR_a110_GTW_MIA m1 : 53|1@1+ (1,0) [0|0] "" Vector__XXX
 SG_ EPBR_a170_12vOv m2 : 53|1@1+ (1,0) [0|0] "" Vector__XXX
 SG_ EPBR_a350_ensOutOfRange m5 : 53|1@1+ (1,0) [0|0] "" Vector__XXX
 SG_ EPBR_a111_EPBR_MIA m1 : 54|1@1+ (1,0) [0|0] "" Vector__XXX
 SG_ EPBR_a171_12vUv m2 : 54|1@1+ (1,0) [0|0] "" Vector__XXX
 SG_ EPBR_a112_EPBL_MIA m1 : 55|1@1+ (1,0) [0|0] "" Vector__XXX
 SG_ EPBR_a172_SPI_MIA m2 : 55|1@1+ (1,0) [0|0] "" Vector__XXX
 SG_ EPBR_a352_audioCurrentSpikeData m5 : 55|1@1+ (1,0) [0|0] "" Vector__XXX
 SG_ EPBR_a113_UI_MIA m1 : 56|1@1+ (1,0) [0|0] "" Vector__XXX
 SG_ EPBR_a173_hiCurrentMissing m2 : 56|1@1+ (1,0) [0|0] "" Vector__XXX
 SG_ EPBR_a353_missingSpeedUnableToPark m5 : 56|1@1+ (1,0) [0|0] "" Vector__XXX
 SG_ EPBR_a114_ESP_MIA m1 : 57|1@1+ (1,0) [0|0] "" Vector__XXX
 SG_ EPBR_a174_csmReleaseFailed m2 : 57|1@1+ (1,0) [0|0] "" Vector__XXX
 SG_ EPBR_a354_parkedForLowBrakeFluidMode m5 : 57|1@1+ (1,0) [0|0] "" Vector__XXX
 SG_ EPBR_a115_VCSEC_MIA m1 : 58|1@1+ (1,0) [0|0] "" Vector__XXX
 SG_ EPBR_a175_csmReleaseRetry m2 : 58|1@1+ (1,0) [0|0] "" Vector__XXX
 SG_ EPBR_a355_brakeHwAndEpbHwMismatch m5 : 58|1@1+ (1,0) [0|0] "" Vector__XXX
 SG_ EPBR_a116_VCRIGHT_MIA m1 : 59|1@1+ (1,0) [0|0] "" Vector__XXX
 SG_ EPBR_a176_csmApplyFailed m2 : 59|1@1+ (1,0) [0|0] "" Vector__XXX
 SG_ EPBR_a356_parkingForStationaryDetect m5 : 59|1@1+ (1,0) [0|0] "" Vector__XXX
 SG_ EPBR_a057_HVP_MIA m0 : 60|1@1+ (1,0) [0|0] "" Vector__XXX
 SG_ EPBR_a117_VCLEFT_MIA m1 : 60|1@1+ (1,0) [0|0] "" Vector__XXX
 SG_ EPBR_a177_csmApplyRetry m2 : 60|1@1+ (1,0) [0|0] "" Vector__XXX
 SG_ EPBR_a357_brakesTooHotForSlope m5 : 60|1@1+ (1,0) [0|0] "" Vector__XXX
 SG_ EPBR_a058_inputRHighSyncDebug m0 : 61|1@1+ (1,0) [0|0] "" Vector__XXX
 SG_ EPBR_a118_VCFRONT_MIA m1 : 61|1@1+ (1,0) [0|0] "" Vector__XXX
 SG_ EPBR_a178_caliperStateUnknown m2 : 61|1@1+ (1,0) [0|0] "" Vector__XXX
 SG_ EPBR_a358_brakesTooHotForSlopeWithOnlyOneEpb m5 : 61|1@1+ (1,0) [0|0] "" Vector__XXX
 SG_ EPBR_a059_inputResistanceHigh m0 : 62|1@1+ (1,0) [0|0] "" Vector__XXX
 SG_ EPBR_a119_SCCM_MIA m1 : 62|1@1+ (1,0) [0|0] "" Vector__XXX
 SG_ EPBR_a179_epbProblem m2 : 62|1@1+ (1,0) [0|0] "" Vector__XXX
 SG_ EPBR_a060_engineeringBuild m0 : 63|1@1+ (1,0) [0|0] "" Vector__XXX
 SG_ EPBR_a120_DI_DRIVE_MIA m1 : 63|1@1+ (1,0) [0|0] "" Vector__XXX
 SG_ EPBR_a180_dynamicActive m2 : 63|1@1+ (1,0) [0|0] "" Vector__XXX
 SG_ EPBR_a300_leftRightConfusion m4 : 63|1@1+ (1,0) [0|0] "" Vector__XXX
 SG_ EPBR_a360_ibstBrakeSwitchInvalid m5 : 63|1@1+ (1,0) [0|0] "" Vector__XXX

BO_ 1001 DAS_bodyControls: 8 Vector__XXX
 SG_ DAS_headlightRequest : 0|2@1+ (1,0) [0|0] "" Vector__XXX
 SG_ DAS_hazardLightRequest : 2|2@1+ (1,0) [0|0] "" Vector__XXX
 SG_ DAS_wiperSpeed : 4|4@1+ (1,0) [0|0] "" Vector__XXX
 SG_ DAS_turnIndicatorRequest : 8|3@1+ (1,0) [0|0] "" Vector__XXX
 SG_ DAS_highLowBeamDecision : 11|2@1+ (1,0) [0|0] "" Vector__XXX
 SG_ DAS_heaterRequest : 13|2@1+ (1,0) [0|0] "" Vector__XXX
 SG_ DAS_highLowBeamOffReason : 15|3@1+ (1,0) [0|0] "" Vector__XXX
 SG_ DAS_forwardCamHeaterDutyCycle : 18|4@1+ (0.06666666666666667,0) [0|0] "" Vector__XXX
 SG_ DAS_dynamicBrakeLightRequest : 22|1@1+ (1,0) [0|0] "" Vector__XXX
 SG_ DAS_radarHeaterRequest : 23|1@1+ (1,0) [0|0] "" Vector__XXX
 SG_ DAS_ahlbOverride : 24|1@1+ (1,0) [0|0] "" Vector__XXX
 SG_ DAS_mirrorFoldRequest : 25|2@1+ (1,0) [0|0] "" Vector__XXX
 SG_ DAS_wiperWashRequest : 27|1@1+ (1,0) [0|0] "" Vector__XXX
 SG_ DAS_ulcConfirmationRequestActive : 28|1@1+ (1,0) [0|0] "" Vector__XXX
 SG_ DAS_overrideWiperSetting : 29|1@1+ (1,0) [0|0] "" Vector__XXX
 SG_ DAS_autoWiperState : 30|3@1+ (1,0) [0|0] "" Vector__XXX
 SG_ DAS_turnIndicatorRequestReason : 33|5@1+ (1,0) [0|0] "" Vector__XXX
 SG_ DAS_forwardRadarPowerRequest : 38|1@1+ (1,0) [0|0] "" Vector__XXX
 SG_ DAS_driverDomeLightRequest : 39|1@1+ (1,0) [0|0] "" Vector__XXX
 SG_ DAS_drivePowerStateRequest : 43|1@1+ (1,0) [0|0] "" Vector__XXX
 SG_ DAS_enableIcrDataCollection : 44|1@1+ (1,0) [0|0] "" Vector__XXX
 SG_ DAS_rPillarCamHeaterDutyCycle : 45|4@1+ (0.06666666666666667,0) [0|0] "" Vector__XXX
 SG_ DAS_adaptiveHighBeamIsFaulted : 49|1@1+ (1,0) [0|0] "" Vector__XXX
 SG_ DAS_restrictDoorReleaseLeft : 50|1@1+ (1,0) [0|0] "" Vector__XXX
 SG_ DAS_restrictDoorReleaseRight : 51|1@1+ (1,0) [0|0] "" Vector__XXX
 SG_ DAS_bodyControlsCounter : 52|4@1+ (1,0) [0|0] "" Vector__XXX
 SG_ DAS_bodyControlsChecksum : 56|8@1+ (1,0) [0|0] "" Vector__XXX

BO_ 1005 GTW_updateStatus: 8 Vector__XXX
 SG_ GTW_i2cUpdateActive : 0|1@0+ (1,0) [0|0] "" Vector__XXX
 SG_ GTW_peripheralConfirmedUpdateNeeded : 4|2@0+ (1,0) [0|0] "" Vector__XXX
 SG_ GTW_ocuFailed : 5|1@1+ (1,0) [0|0] "" Vector__XXX
 SG_ GTW_ecuUpdateStarted : 6|1@1+ (1,0) [0|0] "" Vector__XXX
 SG_ GTW_updateStarted : 7|1@0+ (1,0) [0|0] "" Vector__XXX

BO_ 1009 RCM2_alertMatrix: 8 Vector__XXX
 SG_ RCM2_matrixIndex M : 0|4@1+ (1,0) [0|0] "" Vector__XXX
 SG_ RCM2_a000_crashDetected m0 : 4|1@1+ (1,0) [0|0] "" Vector__XXX
 SG_ RCM2_a089_pretenShldRightShort m1 : 4|1@1+ (1,0) [0|0] "" Vector__XXX
 SG_ RCM2_a149_curABLeftShort m2 : 4|1@1+ (1,0) [0|0] "" Vector__XXX
 SG_ RCM2_a209_sideAB2ndRowLShort m3 : 4|1@1+ (1,0) [0|0] "" Vector__XXX
 SG_ RCM2_a303_imuAccYHgMonChlTemp m4 : 4|1@1+ (1,0) [0|0] "" Vector__XXX
 SG_ RCM2_a393_sideAccelBPilLCLosCoup m5 : 4|1@1+ (1,0) [0|0] "" Vector__XXX
 SG_ RCM2_a457_presPedProLDefect m6 : 4|1@1+ (1,0) [0|0] "" Vector__XXX
 SG_ RCM2_a521_sideAccelDPilRCrssCoup m7 : 4|1@1+ (1,0) [0|0] "" Vector__XXX
 SG_ RCM2_a609_comDItorque1ChkSm m8 : 4|1@1+ (1,0) [0|0] "" Vector__XXX
 SG_ RCM2_a669_comEPBLstatusMIA m9 : 4|1@1+ (1,0) [0|0] "" Vector__XXX
 SG_ RCM2_a825_upFrntPedProMRSht2Bat m10 : 4|1@1+ (1,0) [0|0] "" Vector__XXX
 SG_ RCM2_a001_nearDeploy m0 : 5|1@1+ (1,0) [0|0] "" Vector__XXX
 SG_ RCM2_a090_pretenShldRightCrssCou m1 : 5|1@1+ (1,0) [0|0] "" Vector__XXX
 SG_ RCM2_a150_curABLeftCrssCoup m2 : 5|1@1+ (1,0) [0|0] "" Vector__XXX
 SG_ RCM2_a210_sideAB2ndRowLCrssCoup m3 : 5|1@1+ (1,0) [0|0] "" Vector__XXX
 SG_ RCM2_a304_imuYawR8SnsrPermBG m4 : 5|1@1+ (1,0) [0|0] "" Vector__XXX
 SG_ RCM2_a394_sideAccelBPilLCommErr m5 : 5|1@1+ (1,0) [0|0] "" Vector__XXX
 SG_ RCM2_a458_presPedProLSigMon m6 : 5|1@1+ (1,0) [0|0] "" Vector__XXX
 SG_ RCM2_a522_sideAccelDPilRCommErr m7 : 5|1@1+ (1,0) [0|0] "" Vector__XXX
 SG_ RCM2_a610_comDItorque1Cntr m8 : 5|1@1+ (1,0) [0|0] "" Vector__XXX
 SG_ RCM2_a670_comEPBLstatusChkSm m9 : 5|1@1+ (1,0) [0|0] "" Vector__XXX
 SG_ RCM2_a826_upFrntPedProMROpen m10 : 5|1@1+ (1,0) [0|0] "" Vector__XXX
 SG_ RCM2_a002_airbagsUnArmed m0 : 6|1@1+ (1,0) [0|0] "" Vector__XXX
 SG_ RCM2_a091_pretenShldRightConfig m1 : 6|1@1+ (1,0) [0|0] "" Vector__XXX
 SG_ RCM2_a151_curABLeftConfig m2 : 6|1@1+ (1,0) [0|0] "" Vector__XXX
 SG_ RCM2_a211_sideAB2ndRowLConfig m3 : 6|1@1+ (1,0) [0|0] "" Vector__XXX
 SG_ RCM2_a305_imuYawR8SnsrPermInit m4 : 6|1@1+ (1,0) [0|0] "" Vector__XXX
 SG_ RCM2_a395_sideAccelBPilLInitTyp m5 : 6|1@1+ (1,0) [0|0] "" Vector__XXX
 SG_ RCM2_a460_presPedProRSht2Gnd m6 : 6|1@1+ (1,0) [0|0] "" Vector__XXX
 SG_ RCM2_a523_sideAccelDPilRInitTyp m7 : 6|1@1+ (1,0) [0|0] "" Vector__XXX
 SG_ RCM2_a611_comDItorque2MIA m8 : 6|1@1+ (1,0) [0|0] "" Vector__XXX
 SG_ RCM2_a671_comEPBLstatusCntr m9 : 6|1@1+ (1,0) [0|0] "" Vector__XXX
 SG_ RCM2_a827_upFrntPedProMRCrssCoup m10 : 6|1@1+ (1,0) [0|0] "" Vector__XXX
 SG_ RCM2_a003_warningIndicator m0 : 7|1@1+ (1,0) [0|0] "" Vector__XXX
 SG_ RCM2_a092_pretenLapLeftSht2Gnd m1 : 7|1@1+ (1,0) [0|0] "" Vector__XXX
 SG_ RCM2_a152_curABRightSht2Gnd m2 : 7|1@1+ (1,0) [0|0] "" Vector__XXX
 SG_ RCM2_a212_sideAB2ndRowRSht2Gnd m3 : 7|1@1+ (1,0) [0|0] "" Vector__XXX
 SG_ RCM2_a306_imuYawR8SnsrPermLF m4 : 7|1@1+ (1,0) [0|0] "" Vector__XXX
 SG_ RCM2_a396_sideAccelBPilLConfig m5 : 7|1@1+ (1,0) [0|0] "" Vector__XXX
 SG_ RCM2_a461_presPedProRSht2Bat m6 : 7|1@1+ (1,0) [0|0] "" Vector__XXX
 SG_ RCM2_a524_sideAccelDPilRConfig m7 : 7|1@1+ (1,0) [0|0] "" Vector__XXX
 SG_ RCM2_a612_comDItorque2ChkSm m8 : 7|1@1+ (1,0) [0|0] "" Vector__XXX
 SG_ RCM2_a672_comEPBRstatusMIA m9 : 7|1@1+ (1,0) [0|0] "" Vector__XXX
 SG_ RCM2_a828_upFrntPedProMRCommErr m10 : 7|1@1+ (1,0) [0|0] "" Vector__XXX
 SG_ RCM2_a004_crashAlgoWakeup m0 : 8|1@1+ (1,0) [0|0] "" Vector__XXX
 SG_ RCM2_a093_pretenLapLeftSht2Bat m1 : 8|1@1+ (1,0) [0|0] "" Vector__XXX
 SG_ RCM2_a153_curABRightSht2Bat m2 : 8|1@1+ (1,0) [0|0] "" Vector__XXX
 SG_ RCM2_a213_sideAB2ndRowRSht2Bat m3 : 8|1@1+ (1,0) [0|0] "" Vector__XXX
 SG_ RCM2_a307_imuYawR8ChnlMonTmpLF m4 : 8|1@1+ (1,0) [0|0] "" Vector__XXX
 SG_ RCM2_a397_sideAccelBPilLDefect m5 : 8|1@1+ (1,0) [0|0] "" Vector__XXX
 SG_ RCM2_a462_presPedProROpen m6 : 8|1@1+ (1,0) [0|0] "" Vector__XXX
 SG_ RCM2_a525_sideAccelDPilRDefect m7 : 8|1@1+ (1,0) [0|0] "" Vector__XXX
 SG_ RCM2_a613_comDItorque2Cntr m8 : 8|1@1+ (1,0) [0|0] "" Vector__XXX
 SG_ RCM2_a673_comEPBRstatusChkSm m9 : 8|1@1+ (1,0) [0|0] "" Vector__XXX
 SG_ RCM2_a829_upFrntPedProMRIntTyp m10 : 8|1@1+ (1,0) [0|0] "" Vector__XXX
 SG_ RCM2_a005_abuseImmunityThrshold m0 : 9|1@1+ (1,0) [0|0] "" Vector__XXX
 SG_ RCM2_a094_pretenLapLeftOpen m1 : 9|1@1+ (1,0) [0|0] "" Vector__XXX
 SG_ RCM2_a154_curABRightOpen m2 : 9|1@1+ (1,0) [0|0] "" Vector__XXX
 SG_ RCM2_a214_sideAB2ndRowROpen m3 : 9|1@1+ (1,0) [0|0] "" Vector__XXX
 SG_ RCM2_a308_imuPitchR8SnsrPermBG m4 : 9|1@1+ (1,0) [0|0] "" Vector__XXX
 SG_ RCM2_a398_sideAccelBPilLSigMon m5 : 9|1@1+ (1,0) [0|0] "" Vector__XXX
 SG_ RCM2_a463_presPedProRCrssCoup m6 : 9|1@1+ (1,0) [0|0] "" Vector__XXX
 SG_ RCM2_a526_sideAccelDPilRSigMon m7 : 9|1@1+ (1,0) [0|0] "" Vector__XXX
 SG_ RCM2_a614_comESP135MIA m8 : 9|1@1+ (1,0) [0|0] "" Vector__XXX
 SG_ RCM2_a674_comEPBRstatusCntr m9 : 9|1@1+ (1,0) [0|0] "" Vector__XXX
 SG_ RCM2_a830_upFrntPedProMRConfig m10 : 9|1@1+ (1,0) [0|0] "" Vector__XXX
 SG_ RCM2_a006_supplierDiagEnabled m0 : 10|1@1+ (1,0) [0|0] "" Vector__XXX
 SG_ RCM2_a095_pretenLapLeftShort m1 : 10|1@1+ (1,0) [0|0] "" Vector__XXX
 SG_ RCM2_a155_curABRightShort m2 : 10|1@1+ (1,0) [0|0] "" Vector__XXX
 SG_ RCM2_a215_sideAB2ndRowRShort m3 : 10|1@1+ (1,0) [0|0] "" Vector__XXX
 SG_ RCM2_a309_imuPitchR8SnsrPermInit m4 : 10|1@1+ (1,0) [0|0] "" Vector__XXX
 SG_ RCM2_a400_sideAccelBPilRSht2Gnd m5 : 10|1@1+ (1,0) [0|0] "" Vector__XXX
 SG_ RCM2_a464_presPedProRCommErr m6 : 10|1@1+ (1,0) [0|0] "" Vector__XXX
 SG_ RCM2_a527_upFrntSnsrCSht2Gnd m7 : 10|1@1+ (1,0) [0|0] "" Vector__XXX
 SG_ RCM2_a615_comESP135ChkSm m8 : 10|1@1+ (1,0) [0|0] "" Vector__XXX
 SG_ RCM2_a675_comUIodoMIA m9 : 10|1@1+ (1,0) [0|0] "" Vector__XXX
 SG_ RCM2_a831_upFrntPedProMRDefect m10 : 10|1@1+ (1,0) [0|0] "" Vector__XXX
 SG_ RCM2_a007_pedProCrashDetected m0 : 11|1@1+ (1,0) [0|0] "" Vector__XXX
 SG_ RCM2_a096_pretenLapLeftCrssCoup m1 : 11|1@1+ (1,0) [0|0] "" Vector__XXX
 SG_ RCM2_a156_curABRightCrssCoup m2 : 11|1@1+ (1,0) [0|0] "" Vector__XXX
 SG_ RCM2_a216_sideAB2ndRowRCrssCoup m3 : 11|1@1+ (1,0) [0|0] "" Vector__XXX
 SG_ RCM2_a310_imuPitchR8SnsrPermLF m4 : 11|1@1+ (1,0) [0|0] "" Vector__XXX
 SG_ RCM2_a401_sideAccelBPilRSht2Bat m5 : 11|1@1+ (1,0) [0|0] "" Vector__XXX
 SG_ RCM2_a465_presPedProRInitTyp m6 : 11|1@1+ (1,0) [0|0] "" Vector__XXX
 SG_ RCM2_a528_upFrntSnsrCSht2Bat m7 : 11|1@1+ (1,0) [0|0] "" Vector__XXX
 SG_ RCM2_a616_comESP135Cntr m8 : 11|1@1+ (1,0) [0|0] "" Vector__XXX
 SG_ RCM2_a676_comEPAS3PsysMIA m9 : 11|1@1+ (1,0) [0|0] "" Vector__XXX
 SG_ RCM2_a832_upFrntPedProMRSigMon m10 : 11|1@1+ (1,0) [0|0] "" Vector__XXX
 SG_ RCM2_a008_factoryMode m0 : 12|1@1+ (1,0) [0|0] "" Vector__XXX
 SG_ RCM2_a097_pretenLapLeftConfig m1 : 12|1@1+ (1,0) [0|0] "" Vector__XXX
 SG_ RCM2_a157_curABRightConfig m2 : 12|1@1+ (1,0) [0|0] "" Vector__XXX
 SG_ RCM2_a217_sideAB2ndRowRConfig m3 : 12|1@1+ (1,0) [0|0] "" Vector__XXX
 SG_ RCM2_a311_imuPitchR8ChnlMonTmpLF m4 : 12|1@1+ (1,0) [0|0] "" Vector__XXX
 SG_ RCM2_a402_sideAccelBPilROpen m5 : 12|1@1+ (1,0) [0|0] "" Vector__XXX
 SG_ RCM2_a466_presPedProRConfig m6 : 12|1@1+ (1,0) [0|0] "" Vector__XXX
 SG_ RCM2_a529_upFrntSnsrCOpen m7 : 12|1@1+ (1,0) [0|0] "" Vector__XXX
 SG_ RCM2_a617_comESP145MIA m8 : 12|1@1+ (1,0) [0|0] "" Vector__XXX
 SG_ RCM2_a677_comEPAS3PsysChkSm m9 : 12|1@1+ (1,0) [0|0] "" Vector__XXX
 SG_ RCM2_a833_pretenShldCSht2Gnd m10 : 12|1@1+ (1,0) [0|0] "" Vector__XXX
 SG_ RCM2_a009_edrDataAreaLocked m0 : 13|1@1+ (1,0) [0|0] "" Vector__XXX
 SG_ RCM2_a098_pretenLapRightSht2Gnd m1 : 13|1@1+ (1,0) [0|0] "" Vector__XXX
 SG_ RCM2_a158_preten2ndRowLSht2Gnd m2 : 13|1@1+ (1,0) [0|0] "" Vector__XXX
 SG_ RCM2_a250_ens1Sht2Bat m3 : 13|1@1+ (1,0) [0|0] "" Vector__XXX
 SG_ RCM2_a312_imuRollR8SnsrPermBG m4 : 13|1@1+ (1,0) [0|0] "" Vector__XXX
 SG_ RCM2_a403_sideAccelBPilRCrssCoup m5 : 13|1@1+ (1,0) [0|0] "" Vector__XXX
 SG_ RCM2_a467_presPedProRDefect m6 : 13|1@1+ (1,0) [0|0] "" Vector__XXX
 SG_ RCM2_a530_upFrntSnsrCCrssCoup m7 : 13|1@1+ (1,0) [0|0] "" Vector__XXX
 SG_ RCM2_a618_comESP145ChkSm m8 : 13|1@1+ (1,0) [0|0] "" Vector__XXX
 SG_ RCM2_a678_comEPAS3PsysCntr m9 : 13|1@1+ (1,0) [0|0] "" Vector__XXX
 SG_ RCM2_a834_pretenShldCSht2Bat m10 : 13|1@1+ (1,0) [0|0] "" Vector__XXX
 SG_ RCM2_a010_pedProEDRDataLocked m0 : 14|1@1+ (1,0) [0|0] "" Vector__XXX
 SG_ RCM2_a099_pretenLapRightSht2Bat m1 : 14|1@1+ (1,0) [0|0] "" Vector__XXX
 SG_ RCM2_a159_preten2ndRowLSht2Bat m2 : 14|1@1+ (1,0) [0|0] "" Vector__XXX
 SG_ RCM2_a251_ens1Sht2Gnd m3 : 14|1@1+ (1,0) [0|0] "" Vector__XXX
 SG_ RCM2_a313_imuRollR8SnsrPermInit m4 : 14|1@1+ (1,0) [0|0] "" Vector__XXX
 SG_ RCM2_a404_sideAccelBPilRCommErr m5 : 14|1@1+ (1,0) [0|0] "" Vector__XXX
 SG_ RCM2_a468_presPedProRSigMon m6 : 14|1@1+ (1,0) [0|0] "" Vector__XXX
 SG_ RCM2_a531_upFrntSnsrCCommErr m7 : 14|1@1+ (1,0) [0|0] "" Vector__XXX
 SG_ RCM2_a619_comESP145Cntr m8 : 14|1@1+ (1,0) [0|0] "" Vector__XXX
 SG_ RCM2_a679_comESPwheelSpeedsMIA m9 : 14|1@1+ (1,0) [0|0] "" Vector__XXX
 SG_ RCM2_a835_pretenShldCOpen m10 : 14|1@1+ (1,0) [0|0] "" Vector__XXX
 SG_ RCM2_a011_placeholder0 m0 : 15|1@1+ (1,0) [0|0] "" Vector__XXX
 SG_ RCM2_a100_pretenLapRightOpen m1 : 15|1@1+ (1,0) [0|0] "" Vector__XXX
 SG_ RCM2_a160_preten2ndRowLOpen m2 : 15|1@1+ (1,0) [0|0] "" Vector__XXX
 SG_ RCM2_a252_ens1Config m3 : 15|1@1+ (1,0) [0|0] "" Vector__XXX
 SG_ RCM2_a314_imuRollR8SnsrPermLF m4 : 15|1@1+ (1,0) [0|0] "" Vector__XXX
 SG_ RCM2_a405_sideAccelBPilRInitTyp m5 : 15|1@1+ (1,0) [0|0] "" Vector__XXX
 SG_ RCM2_a469_presPedProAbsolute m6 : 15|1@1+ (1,0) [0|0] "" Vector__XXX
 SG_ RCM2_a532_upFrntSnsrCInitTyp m7 : 15|1@1+ (1,0) [0|0] "" Vector__XXX
 SG_ RCM2_a620_comInvalidVehicleSpeed m8 : 15|1@1+ (1,0) [0|0] "" Vector__XXX
 SG_ RCM2_a680_comESPwheelSpeedsChkSm m9 : 15|1@1+ (1,0) [0|0] "" Vector__XXX
 SG_ RCM2_a836_pretenShldCShort m10 : 15|1@1+ (1,0) [0|0] "" Vector__XXX
 SG_ RCM2_a012_placeholder1 m0 : 16|1@1+ (1,0) [0|0] "" Vector__XXX
 SG_ RCM2_a101_pretenLapRightShort m1 : 16|1@1+ (1,0) [0|0] "" Vector__XXX
 SG_ RCM2_a161_preten2ndRowLShort m2 : 16|1@1+ (1,0) [0|0] "" Vector__XXX
 SG_ RCM2_a253_ens2Sht2Bat m3 : 16|1@1+ (1,0) [0|0] "" Vector__XXX
 SG_ RCM2_a315_imuRollR8ChnlMonTmpLF m4 : 16|1@1+ (1,0) [0|0] "" Vector__XXX
 SG_ RCM2_a406_sideAccelBPilRConfig m5 : 16|1@1+ (1,0) [0|0] "" Vector__XXX
 SG_ RCM2_a470_upFrntPedProLSht2Gnd m6 : 16|1@1+ (1,0) [0|0] "" Vector__XXX
 SG_ RCM2_a533_upFrntSnsrCConfig m7 : 16|1@1+ (1,0) [0|0] "" Vector__XXX
 SG_ RCM2_a621_comESPBMIA m8 : 16|1@1+ (1,0) [0|0] "" Vector__XXX
 SG_ RCM2_a681_comESPwheelSpeedsCntr m9 : 16|1@1+ (1,0) [0|0] "" Vector__XXX
 SG_ RCM2_a837_pretenShldCCrossC m10 : 16|1@1+ (1,0) [0|0] "" Vector__XXX
 SG_ RCM2_a013_placeholder2 m0 : 17|1@1+ (1,0) [0|0] "" Vector__XXX
 SG_ RCM2_a102_pretenLapRightCrssCoup m1 : 17|1@1+ (1,0) [0|0] "" Vector__XXX
 SG_ RCM2_a162_preten2ndRowLCrssCoup m2 : 17|1@1+ (1,0) [0|0] "" Vector__XXX
 SG_ RCM2_a254_ens2Sht2Gnd m3 : 17|1@1+ (1,0) [0|0] "" Vector__XXX
 SG_ RCM2_a316_imuAccXLgMonChlPerm m4 : 17|1@1+ (1,0) [0|0] "" Vector__XXX
 SG_ RCM2_a407_sideAccelBPilRDefect m5 : 17|1@1+ (1,0) [0|0] "" Vector__XXX
 SG_ RCM2_a471_upFrntPedProLSht2Bat m6 : 17|1@1+ (1,0) [0|0] "" Vector__XXX
 SG_ RCM2_a534_upFrntSnsrCDefect m7 : 17|1@1+ (1,0) [0|0] "" Vector__XXX
 SG_ RCM2_a622_comESPBChkSm m8 : 17|1@1+ (1,0) [0|0] "" Vector__XXX
 SG_ RCM2_a682_comDIspeedMIA m9 : 17|1@1+ (1,0) [0|0] "" Vector__XXX
 SG_ RCM2_a838_pretenShldCConfig m10 : 17|1@1+ (1,0) [0|0] "" Vector__XXX
 SG_ RCM2_a014_pedProNearDeploy m0 : 18|1@1+ (1,0) [0|0] "" Vector__XXX
 SG_ RCM2_a103_pretenLapRightConfig m1 : 18|1@1+ (1,0) [0|0] "" Vector__XXX
 SG_ RCM2_a163_preten2ndRowLCgf m2 : 18|1@1+ (1,0) [0|0] "" Vector__XXX
 SG_ RCM2_a255_ens2Config m3 : 18|1@1+ (1,0) [0|0] "" Vector__XXX
 SG_ RCM2_a317_imuAccXLgMonChlTemp m4 : 18|1@1+ (1,0) [0|0] "" Vector__XXX
 SG_ RCM2_a408_sideAccelBPilRSigMon m5 : 18|1@1+ (1,0) [0|0] "" Vector__XXX
 SG_ RCM2_a472_upFrntPedProLOpen m6 : 18|1@1+ (1,0) [0|0] "" Vector__XXX
 SG_ RCM2_a535_upFrntSnsrCSigMon m7 : 18|1@1+ (1,0) [0|0] "" Vector__XXX
 SG_ RCM2_a623_comESPBCntr m8 : 18|1@1+ (1,0) [0|0] "" Vector__XXX
 SG_ RCM2_a683_comDIspeedChkSm m9 : 18|1@1+ (1,0) [0|0] "" Vector__XXX
 SG_ RCM2_a839_preten2ndRowCSht2Gnd m10 : 18|1@1+ (1,0) [0|0] "" Vector__XXX
 SG_ RCM2_a015_noDeployCrashCal m0 : 19|1@1+ (1,0) [0|0] "" Vector__XXX
 SG_ RCM2_a104_loadLimLeftSht2Gnd m1 : 19|1@1+ (1,0) [0|0] "" Vector__XXX
 SG_ RCM2_a164_preten2ndRowRSht2Gnd m2 : 19|1@1+ (1,0) [0|0] "" Vector__XXX
 SG_ RCM2_a256_ens3Sht2Bat m3 : 19|1@1+ (1,0) [0|0] "" Vector__XXX
 SG_ RCM2_a318_imuAccYLgMonChlPerm m4 : 19|1@1+ (1,0) [0|0] "" Vector__XXX
 SG_ RCM2_a410_sideAccelCPilLSht2Gnd m5 : 19|1@1+ (1,0) [0|0] "" Vector__XXX
 SG_ RCM2_a473_upFrntPedProLCrssCoup m6 : 19|1@1+ (1,0) [0|0] "" Vector__XXX
 SG_ RCM2_a550_bucklHallLeftSht2Gnd m7 : 19|1@1+ (1,0) [0|0] "" Vector__XXX
 SG_ RCM2_a624_comESPCMIA m8 : 19|1@1+ (1,0) [0|0] "" Vector__XXX
 SG_ RCM2_a684_comDIspeedCntr m9 : 19|1@1+ (1,0) [0|0] "" Vector__XXX
 SG_ RCM2_a840_preten2ndRowCSht2Bat m10 : 19|1@1+ (1,0) [0|0] "" Vector__XXX
 SG_ RCM2_a016_noDeployPedProCal m0 : 20|1@1+ (1,0) [0|0] "" Vector__XXX
 SG_ RCM2_a105_loadLimLeftSht2Bat m1 : 20|1@1+ (1,0) [0|0] "" Vector__XXX
 SG_ RCM2_a165_preten2ndRowRSht2Bat m2 : 20|1@1+ (1,0) [0|0] "" Vector__XXX
 SG_ RCM2_a257_ens3Sht2Gnd m3 : 20|1@1+ (1,0) [0|0] "" Vector__XXX
 SG_ RCM2_a319_imuAccYLgMonChlTemp m4 : 20|1@1+ (1,0) [0|0] "" Vector__XXX
 SG_ RCM2_a411_sideAccelCPilLSht2Bat m5 : 20|1@1+ (1,0) [0|0] "" Vector__XXX
 SG_ RCM2_a474_upFrntPedProLCommErr m6 : 20|1@1+ (1,0) [0|0] "" Vector__XXX
 SG_ RCM2_a551_bucklHallLeftSht2Bat m7 : 20|1@1+ (1,0) [0|0] "" Vector__XXX
 SG_ RCM2_a625_comESPCChkSm m8 : 20|1@1+ (1,0) [0|0] "" Vector__XXX
 SG_ RCM2_a685_comDIchassControlMIA m9 : 20|1@1+ (1,0) [0|0] "" Vector__XXX
 SG_ RCM2_a841_preten2ndRowCOpen m10 : 20|1@1+ (1,0) [0|0] "" Vector__XXX
 SG_ RCM2_a017_ecuLogAvailable m0 : 21|1@1+ (1,0) [0|0] "" Vector__XXX
 SG_ RCM2_a106_loadLimLeftOpen m1 : 21|1@1+ (1,0) [0|0] "" Vector__XXX
 SG_ RCM2_a166_preten2ndRowROpen m2 : 21|1@1+ (1,0) [0|0] "" Vector__XXX
 SG_ RCM2_a258_ens3Config m3 : 21|1@1+ (1,0) [0|0] "" Vector__XXX
 SG_ RCM2_a320_imuAccZLgMonChlPerm m4 : 21|1@1+ (1,0) [0|0] "" Vector__XXX
 SG_ RCM2_a412_sideAccelCPilLOpen m5 : 21|1@1+ (1,0) [0|0] "" Vector__XXX
 SG_ RCM2_a475_upFrntPedProLIntTyp m6 : 21|1@1+ (1,0) [0|0] "" Vector__XXX
 SG_ RCM2_a552_bucklHallLeftOpen m7 : 21|1@1+ (1,0) [0|0] "" Vector__XXX
 SG_ RCM2_a626_comESPCCntr m8 : 21|1@1+ (1,0) [0|0] "" Vector__XXX
 SG_ RCM2_a686_comDIchassControlChkSm m9 : 21|1@1+ (1,0) [0|0] "" Vector__XXX
 SG_ RCM2_a842_preten2ndRowCShort m10 : 21|1@1+ (1,0) [0|0] "" Vector__XXX
 SG_ RCM2_a047_batteryESRhigh m0 : 22|1@1+ (1,0) [0|0] "" Vector__XXX
 SG_ RCM2_a107_loadLimLeftShort m1 : 22|1@1+ (1,0) [0|0] "" Vector__XXX
 SG_ RCM2_a167_preten2ndRowRShort m2 : 22|1@1+ (1,0) [0|0] "" Vector__XXX
 SG_ RCM2_a259_ens4Sht2Bat m3 : 22|1@1+ (1,0) [0|0] "" Vector__XXX
 SG_ RCM2_a321_imuAccZLgMonChlTemp m4 : 22|1@1+ (1,0) [0|0] "" Vector__XXX
 SG_ RCM2_a413_sideAccelCPilLCrssCoup m5 : 22|1@1+ (1,0) [0|0] "" Vector__XXX
 SG_ RCM2_a476_upFrntPedProLConfig m6 : 22|1@1+ (1,0) [0|0] "" Vector__XXX
 SG_ RCM2_a553_bucklHallLeftUndef m7 : 22|1@1+ (1,0) [0|0] "" Vector__XXX
 SG_ RCM2_a627_comEPBStatusMIA m8 : 22|1@1+ (1,0) [0|0] "" Vector__XXX
 SG_ RCM2_a687_comDIchassControlCntr m9 : 22|1@1+ (1,0) [0|0] "" Vector__XXX
 SG_ RCM2_a843_preten2ndRowCCrssCoup m10 : 22|1@1+ (1,0) [0|0] "" Vector__XXX
 SG_ RCM2_a048_batteryVoltageTooHigh m0 : 23|1@1+ (1,0) [0|0] "" Vector__XXX
 SG_ RCM2_a108_loadLimLeftCrssCoup m1 : 23|1@1+ (1,0) [0|0] "" Vector__XXX
 SG_ RCM2_a168_preten2ndRowRCrssCoup m2 : 23|1@1+ (1,0) [0|0] "" Vector__XXX
 SG_ RCM2_a260_ens4Sht2Gnd m3 : 23|1@1+ (1,0) [0|0] "" Vector__XXX
 SG_ RCM2_a322_imuCalibrationFailed m4 : 23|1@1+ (1,0) [0|0] "" Vector__XXX
 SG_ RCM2_a414_sideAccelCPilLCommErr m5 : 23|1@1+ (1,0) [0|0] "" Vector__XXX
 SG_ RCM2_a477_upFrntPedProLDefect m6 : 23|1@1+ (1,0) [0|0] "" Vector__XXX
 SG_ RCM2_a554_bucklHallLeftCrssCoup m7 : 23|1@1+ (1,0) [0|0] "" Vector__XXX
 SG_ RCM2_a628_comEPBStatusChkSm m8 : 23|1@1+ (1,0) [0|0] "" Vector__XXX
 SG_ RCM2_a688_comVCLEFTrestMIA m9 : 23|1@1+ (1,0) [0|0] "" Vector__XXX
 SG_ RCM2_a844_preten2ndRowCConfig m10 : 23|1@1+ (1,0) [0|0] "" Vector__XXX
 SG_ RCM2_a049_batteryVoltageTooLow m0 : 24|1@1+ (1,0) [0|0] "" Vector__XXX
 SG_ RCM2_a109_loadLimLeftConfig m1 : 24|1@1+ (1,0) [0|0] "" Vector__XXX
 SG_ RCM2_a169_preten2ndRowRCgf m2 : 24|1@1+ (1,0) [0|0] "" Vector__XXX
 SG_ RCM2_a261_ens4Config m3 : 24|1@1+ (1,0) [0|0] "" Vector__XXX
 SG_ RCM2_a323_imuCalibrationNotDone m4 : 24|1@1+ (1,0) [0|0] "" Vector__XXX
 SG_ RCM2_a415_sideAccelCPilLInitTyp m5 : 24|1@1+ (1,0) [0|0] "" Vector__XXX
 SG_ RCM2_a478_upFrntPedProLSigMon m6 : 24|1@1+ (1,0) [0|0] "" Vector__XXX
 SG_ RCM2_a555_bucklHallLeftConfig m7 : 24|1@1+ (1,0) [0|0] "" Vector__XXX
 SG_ RCM2_a629_comEPBStatusCntr m8 : 24|1@1+ (1,0) [0|0] "" Vector__XXX
 SG_ RCM2_a689_comVCLEFTrestChkSm m9 : 24|1@1+ (1,0) [0|0] "" Vector__XXX
 SG_ RCM2_a845_comUIchassisControlMIA m10 : 24|1@1+ (1,0) [0|0] "" Vector__XXX
 SG_ RCM2_a050_driverABStg1Sht2Gnd m0 : 25|1@1+ (1,0) [0|0] "" Vector__XXX
 SG_ RCM2_a110_loadLimRightSht2Gnd m1 : 25|1@1+ (1,0) [0|0] "" Vector__XXX
 SG_ RCM2_a170_curAB2ndRowLSht2Gnd m2 : 25|1@1+ (1,0) [0|0] "" Vector__XXX
 SG_ RCM2_a264_imuYawR8OffCompPosLife m3 : 25|1@1+ (1,0) [0|0] "" Vector__XXX
 SG_ RCM2_a350_upFrntSnsrLSht2Gnd m4 : 25|1@1+ (1,0) [0|0] "" Vector__XXX
 SG_ RCM2_a416_sideAccelCPilLConfig m5 : 25|1@1+ (1,0) [0|0] "" Vector__XXX
 SG_ RCM2_a480_upFrntPedProRSht2Gnd m6 : 25|1@1+ (1,0) [0|0] "" Vector__XXX
 SG_ RCM2_a556_bucklHallRightSht2Gnd m7 : 25|1@1+ (1,0) [0|0] "" Vector__XXX
 SG_ RCM2_a630_comGTWACSMIA m8 : 25|1@1+ (1,0) [0|0] "" Vector__XXX
 SG_ RCM2_a690_comVCLEFTrestCntr m9 : 25|1@1+ (1,0) [0|0] "" Vector__XXX
 SG_ RCM2_a846_comSCCMstrAnglSnsMIA m10 : 25|1@1+ (1,0) [0|0] "" Vector__XXX
 SG_ RCM2_a051_driverABStg1Sht2Bat m0 : 26|1@1+ (1,0) [0|0] "" Vector__XXX
 SG_ RCM2_a111_loadLimRightSht2Bat m1 : 26|1@1+ (1,0) [0|0] "" Vector__XXX
 SG_ RCM2_a171_curAB2ndRowLSht2Bat m2 : 26|1@1+ (1,0) [0|0] "" Vector__XXX
 SG_ RCM2_a265_imuYawR8OffCompNegLife m3 : 26|1@1+ (1,0) [0|0] "" Vector__XXX
 SG_ RCM2_a351_upFrntSnsrLSht2Bat m4 : 26|1@1+ (1,0) [0|0] "" Vector__XXX
 SG_ RCM2_a417_sideAccelCPilLDefect m5 : 26|1@1+ (1,0) [0|0] "" Vector__XXX
 SG_ RCM2_a481_upFrntPedProRSht2Bat m6 : 26|1@1+ (1,0) [0|0] "" Vector__XXX
 SG_ RCM2_a557_bucklHallRightSht2Bat m7 : 26|1@1+ (1,0) [0|0] "" Vector__XXX
 SG_ RCM2_a631_comGTWACSChkSm m8 : 26|1@1+ (1,0) [0|0] "" Vector__XXX
 SG_ RCM2_a691_comVCLEFT1rLBuckle m9 : 26|1@1+ (1,0) [0|0] "" Vector__XXX
 SG_ RCM2_a847_comDASctrlMIA m10 : 26|1@1+ (1,0) [0|0] "" Vector__XXX
 SG_ RCM2_a052_driverABStg1Open m0 : 27|1@1+ (1,0) [0|0] "" Vector__XXX
 SG_ RCM2_a112_loadLimRightOpen m1 : 27|1@1+ (1,0) [0|0] "" Vector__XXX
 SG_ RCM2_a172_curAB2ndRowLOpen m2 : 27|1@1+ (1,0) [0|0] "" Vector__XXX
 SG_ RCM2_a266_imuYawR8OffCompPosFLDC m3 : 27|1@1+ (1,0) [0|0] "" Vector__XXX
 SG_ RCM2_a352_upFrntSnsrLOpen m4 : 27|1@1+ (1,0) [0|0] "" Vector__XXX
 SG_ RCM2_a418_sideAccelCPilLSigMon m5 : 27|1@1+ (1,0) [0|0] "" Vector__XXX
 SG_ RCM2_a482_upFrntPedProROpen m6 : 27|1@1+ (1,0) [0|0] "" Vector__XXX
 SG_ RCM2_a558_bucklHallRightOpen m7 : 27|1@1+ (1,0) [0|0] "" Vector__XXX
 SG_ RCM2_a632_comGTWACSCntr m8 : 27|1@1+ (1,0) [0|0] "" Vector__XXX
 SG_ RCM2_a692_comVCLEFT2rLBuckle m9 : 27|1@1+ (1,0) [0|0] "" Vector__XXX
 SG_ RCM2_a848_comDIlocStatMIA m10 : 27|1@1+ (1,0) [0|0] "" Vector__XXX
 SG_ RCM2_a053_driverABStg1Short m0 : 28|1@1+ (1,0) [0|0] "" Vector__XXX
 SG_ RCM2_a113_loadLimRightShort m1 : 28|1@1+ (1,0) [0|0] "" Vector__XXX
 SG_ RCM2_a173_curAB2ndRowLShort m2 : 28|1@1+ (1,0) [0|0] "" Vector__XXX
 SG_ RCM2_a267_imuYawR8OffCompNegFLDC m3 : 28|1@1+ (1,0) [0|0] "" Vector__XXX
 SG_ RCM2_a353_upFrntSnsrLCrssCoup m4 : 28|1@1+ (1,0) [0|0] "" Vector__XXX
 SG_ RCM2_a420_sideAccelCPilRSht2Gnd m5 : 28|1@1+ (1,0) [0|0] "" Vector__XXX
 SG_ RCM2_a483_upFrntPedProRCrssCoup m6 : 28|1@1+ (1,0) [0|0] "" Vector__XXX
 SG_ RCM2_a559_bucklHallRightUndef m7 : 28|1@1+ (1,0) [0|0] "" Vector__XXX
 SG_ RCM2_a633_comOCS1PMIA m8 : 28|1@1+ (1,0) [0|0] "" Vector__XXX
 SG_ RCM2_a693_comVCLEFT1rLSTPS m9 : 28|1@1+ (1,0) [0|0] "" Vector__XXX
 SG_ RCM2_a849_comIBSTparty1MIA m10 : 28|1@1+ (1,0) [0|0] "" Vector__XXX
 SG_ RCM2_a054_driverABStg1CrssCoup m0 : 29|1@1+ (1,0) [0|0] "" Vector__XXX
 SG_ RCM2_a114_loadLimRightCrssCoup m1 : 29|1@1+ (1,0) [0|0] "" Vector__XXX
 SG_ RCM2_a174_curAB2ndRowLCrssCoup m2 : 29|1@1+ (1,0) [0|0] "" Vector__XXX
 SG_ RCM2_a268_imuYawR8OffCompPosSLDC m3 : 29|1@1+ (1,0) [0|0] "" Vector__XXX
 SG_ RCM2_a354_upFrntSnsrLCommErr m4 : 29|1@1+ (1,0) [0|0] "" Vector__XXX
 SG_ RCM2_a421_sideAccelCPilRSht2Bat m5 : 29|1@1+ (1,0) [0|0] "" Vector__XXX
 SG_ RCM2_a484_upFrntPedProRCommErr m6 : 29|1@1+ (1,0) [0|0] "" Vector__XXX
 SG_ RCM2_a560_bucklHallRightCrssCoup m7 : 29|1@1+ (1,0) [0|0] "" Vector__XXX
 SG_ RCM2_a634_comOCS1PChkSm m8 : 29|1@1+ (1,0) [0|0] "" Vector__XXX
 SG_ RCM2_a694_comVCRIGHTrestMIA m9 : 29|1@1+ (1,0) [0|0] "" Vector__XXX
 SG_ RCM2_a850_comVCFRONTlightingMIA m10 : 29|1@1+ (1,0) [0|0] "" Vector__XXX
 SG_ RCM2_a055_driverABStg1Config m0 : 30|1@1+ (1,0) [0|0] "" Vector__XXX
 SG_ RCM2_a115_loadLimRightConfig m1 : 30|1@1+ (1,0) [0|0] "" Vector__XXX
 SG_ RCM2_a175_curAB2ndRowLConfig m2 : 30|1@1+ (1,0) [0|0] "" Vector__XXX
 SG_ RCM2_a269_imuYawR8OffCompNegSLDC m3 : 30|1@1+ (1,0) [0|0] "" Vector__XXX
 SG_ RCM2_a355_upFrntSnsrLInitTyp m4 : 30|1@1+ (1,0) [0|0] "" Vector__XXX
 SG_ RCM2_a422_sideAccelCPilROpen m5 : 30|1@1+ (1,0) [0|0] "" Vector__XXX
 SG_ RCM2_a485_upFrntPedProRIntTyp m6 : 30|1@1+ (1,0) [0|0] "" Vector__XXX
 SG_ RCM2_a561_bucklHallRightConfig m7 : 30|1@1+ (1,0) [0|0] "" Vector__XXX
 SG_ RCM2_a635_comOCS1PCntr m8 : 30|1@1+ (1,0) [0|0] "" Vector__XXX
 SG_ RCM2_a695_comVCRIGHTrestChkSm m9 : 30|1@1+ (1,0) [0|0] "" Vector__XXX
 SG_ RCM2_a851_internalFaultTemp m10 : 30|1@1+ (1,0) [0|0] "" Vector__XXX
 SG_ RCM2_a056_driverABStg2Sht2Gnd m0 : 31|1@1+ (1,0) [0|0] "" Vector__XXX
 SG_ RCM2_a116_kneeABDrvrSht2Gnd m1 : 31|1@1+ (1,0) [0|0] "" Vector__XXX
 SG_ RCM2_a176_curAB2ndRowRSht2Gnd m2 : 31|1@1+ (1,0) [0|0] "" Vector__XXX
 SG_ RCM2_a270_imuPtchR8OffCompPosLife m3 : 31|1@1+ (1,0) [0|0] "" Vector__XXX
 SG_ RCM2_a356_upFrntSnsrLConfig m4 : 31|1@1+ (1,0) [0|0] "" Vector__XXX
 SG_ RCM2_a423_sideAccelCPilRCrssCoup m5 : 31|1@1+ (1,0) [0|0] "" Vector__XXX
 SG_ RCM2_a486_upFrntPedProRConfig m6 : 31|1@1+ (1,0) [0|0] "" Vector__XXX
 SG_ RCM2_a562_seaTrkPosLeftSht2Gnd m7 : 31|1@1+ (1,0) [0|0] "" Vector__XXX
 SG_ RCM2_a636_ocsFaulted m8 : 31|1@1+ (1,0) [0|0] "" Vector__XXX
 SG_ RCM2_a696_comVCRIGHTrestCntr m9 : 31|1@1+ (1,0) [0|0] "" Vector__XXX
 SG_ RCM2_a852_autarkyEvent m10 : 31|1@1+ (1,0) [0|0] "" Vector__XXX
 SG_ RCM2_a057_driverABStg2Sht2Bat m0 : 32|1@1+ (1,0) [0|0] "" Vector__XXX
 SG_ RCM2_a117_kneeABDrvrSht2Bat m1 : 32|1@1+ (1,0) [0|0] "" Vector__XXX
 SG_ RCM2_a177_curAB2ndRowRSht2Bat m2 : 32|1@1+ (1,0) [0|0] "" Vector__XXX
 SG_ RCM2_a271_imuPtchR8OffCompNegLife m3 : 32|1@1+ (1,0) [0|0] "" Vector__XXX
 SG_ RCM2_a357_upFrntSnsrLDefect m4 : 32|1@1+ (1,0) [0|0] "" Vector__XXX
 SG_ RCM2_a424_sideAccelCPilRCommErr m5 : 32|1@1+ (1,0) [0|0] "" Vector__XXX
 SG_ RCM2_a487_upFrntPedProRDefect m6 : 32|1@1+ (1,0) [0|0] "" Vector__XXX
 SG_ RCM2_a563_seaTrkPosLeftShtBat m7 : 32|1@1+ (1,0) [0|0] "" Vector__XXX
 SG_ RCM2_a637_ocsUnknown m8 : 32|1@1+ (1,0) [0|0] "" Vector__XXX
 SG_ RCM2_a697_comVCRIGHT1rRBuckle m9 : 32|1@1+ (1,0) [0|0] "" Vector__XXX
 SG_ RCM2_a853_ConfigParametersInconsistent m10 : 32|1@1+ (1,0) [0|0] "" Vector__XXX
 SG_ RCM2_a058_driverABStg2Open m0 : 33|1@1+ (1,0) [0|0] "" Vector__XXX
 SG_ RCM2_a118_kneeABDrvrOpen m1 : 33|1@1+ (1,0) [0|0] "" Vector__XXX
 SG_ RCM2_a178_curAB2ndRowROpen m2 : 33|1@1+ (1,0) [0|0] "" Vector__XXX
 SG_ RCM2_a272_imuPtchR8OffCompPosFLDC m3 : 33|1@1+ (1,0) [0|0] "" Vector__XXX
 SG_ RCM2_a358_upFrntSnsrLSigMon m4 : 33|1@1+ (1,0) [0|0] "" Vector__XXX
 SG_ RCM2_a425_sideAccelCPilRInitTyp m5 : 33|1@1+ (1,0) [0|0] "" Vector__XXX
 SG_ RCM2_a488_upFrntPedProRSigMon m6 : 33|1@1+ (1,0) [0|0] "" Vector__XXX
 SG_ RCM2_a564_seaTrkPosLeftOpen m7 : 33|1@1+ (1,0) [0|0] "" Vector__XXX
 SG_ RCM2_a638_comGTWodoMIA m8 : 33|1@1+ (1,0) [0|0] "" Vector__XXX
 SG_ RCM2_a698_comVCRIGHT2rRBuckle m9 : 33|1@1+ (1,0) [0|0] "" Vector__XXX
 SG_ RCM2_a854_ConfigParametersNotLearned m10 : 33|1@1+ (1,0) [0|0] "" Vector__XXX
 SG_ RCM2_a059_driverABStg2Short m0 : 34|1@1+ (1,0) [0|0] "" Vector__XXX
 SG_ RCM2_a119_kneeABDrvrShort m1 : 34|1@1+ (1,0) [0|0] "" Vector__XXX
 SG_ RCM2_a179_curAB2ndRowRShort m2 : 34|1@1+ (1,0) [0|0] "" Vector__XXX
 SG_ RCM2_a273_imuPtchR8OffCompNegFLDC m3 : 34|1@1+ (1,0) [0|0] "" Vector__XXX
 SG_ RCM2_a360_upFrntSnsrRSht2Gnd m4 : 34|1@1+ (1,0) [0|0] "" Vector__XXX
 SG_ RCM2_a426_sideAccelCPilRConfig m5 : 34|1@1+ (1,0) [0|0] "" Vector__XXX
 SG_ RCM2_a490_presRearLDoorSht2Gnd m6 : 34|1@1+ (1,0) [0|0] "" Vector__XXX
 SG_ RCM2_a565_seaTrkPosLeftUndefined m7 : 34|1@1+ (1,0) [0|0] "" Vector__XXX
 SG_ RCM2_a639_comGTWCarStateMIA m8 : 34|1@1+ (1,0) [0|0] "" Vector__XXX
 SG_ RCM2_a699_comVCRIGHTocs m9 : 34|1@1+ (1,0) [0|0] "" Vector__XXX
 SG_ RCM2_a857_comVCLEFT2rCBuckle m10 : 34|1@1+ (1,0) [0|0] "" Vector__XXX
 SG_ RCM2_a060_driverABStg2CrssCoup m0 : 35|1@1+ (1,0) [0|0] "" Vector__XXX
 SG_ RCM2_a120_kneeABDrvrCrssCoup m1 : 35|1@1+ (1,0) [0|0] "" Vector__XXX
 SG_ RCM2_a180_curAB2ndRowRCrssCoup m2 : 35|1@1+ (1,0) [0|0] "" Vector__XXX
 SG_ RCM2_a274_imuPtchR8OffCompPosSLDC m3 : 35|1@1+ (1,0) [0|0] "" Vector__XXX
 SG_ RCM2_a361_upFrntSnsrRSht2Bat m4 : 35|1@1+ (1,0) [0|0] "" Vector__XXX
 SG_ RCM2_a427_sideAccelCPilRDefect m5 : 35|1@1+ (1,0) [0|0] "" Vector__XXX
 SG_ RCM2_a491_presRearLDoorSht2Bat m6 : 35|1@1+ (1,0) [0|0] "" Vector__XXX
 SG_ RCM2_a566_seaTrkPosLeftCrssCoup m7 : 35|1@1+ (1,0) [0|0] "" Vector__XXX
 SG_ RCM2_a640_comTPMSStatusCMIA m8 : 35|1@1+ (1,0) [0|0] "" Vector__XXX
 SG_ RCM2_a700_comVCRIGHT1rRSTPS m9 : 35|1@1+ (1,0) [0|0] "" Vector__XXX
 SG_ RCM2_a858_comVCxLVPowerStateMIA m10 : 35|1@1+ (1,0) [0|0] "" Vector__XXX
 SG_ RCM2_a061_driverABStg2Config m0 : 36|1@1+ (1,0) [0|0] "" Vector__XXX
 SG_ RCM2_a121_kneeABDrvrConfig m1 : 36|1@1+ (1,0) [0|0] "" Vector__XXX
 SG_ RCM2_a181_curAB2ndRowRConfig m2 : 36|1@1+ (1,0) [0|0] "" Vector__XXX
 SG_ RCM2_a275_imuPtchR8OffCompNegSLDC m3 : 36|1@1+ (1,0) [0|0] "" Vector__XXX
 SG_ RCM2_a362_upFrntSnsrROpen m4 : 36|1@1+ (1,0) [0|0] "" Vector__XXX
 SG_ RCM2_a428_sideAccelCPilRSigMon m5 : 36|1@1+ (1,0) [0|0] "" Vector__XXX
 SG_ RCM2_a492_presRearLDoorOpen m6 : 36|1@1+ (1,0) [0|0] "" Vector__XXX
 SG_ RCM2_a567_seaTrkPosLeftConfig m7 : 36|1@1+ (1,0) [0|0] "" Vector__XXX
 SG_ RCM2_a641_comGTWCarConfigMIA m8 : 36|1@1+ (1,0) [0|0] "" Vector__XXX
 SG_ RCM2_a701_comVCSECtpmsStatusMIA m9 : 36|1@1+ (1,0) [0|0] "" Vector__XXX
 SG_ RCM2_a859_comVCxLVPowerStateChkSm m10 : 36|1@1+ (1,0) [0|0] "" Vector__XXX
 SG_ RCM2_a062_passABStg1Sht2Gnd m0 : 37|1@1+ (1,0) [0|0] "" Vector__XXX
 SG_ RCM2_a122_kneeABPassSht2Gnd m1 : 37|1@1+ (1,0) [0|0] "" Vector__XXX
 SG_ RCM2_a182_hoodActuatorRSht2Gnd m2 : 37|1@1+ (1,0) [0|0] "" Vector__XXX
 SG_ RCM2_a276_imuRollR8OffCompPosLife m3 : 37|1@1+ (1,0) [0|0] "" Vector__XXX
 SG_ RCM2_a363_upFrntSnsrRCrssCoup m4 : 37|1@1+ (1,0) [0|0] "" Vector__XXX
 SG_ RCM2_a430_presFrntLDoorSht2Gnd m5 : 37|1@1+ (1,0) [0|0] "" Vector__XXX
 SG_ RCM2_a493_presRearLDoorCrssCoup m6 : 37|1@1+ (1,0) [0|0] "" Vector__XXX
 SG_ RCM2_a568_occPROSSht2Gnd m7 : 37|1@1+ (1,0) [0|0] "" Vector__XXX
 SG_ RCM2_a642_comVINmessageMIA m8 : 37|1@1+ (1,0) [0|0] "" Vector__XXX
 SG_ RCM2_a750_linInternalTimeout m9 : 37|1@1+ (1,0) [0|0] "" Vector__XXX
 SG_ RCM2_a860_comVCxLVPowerStateCntr m10 : 37|1@1+ (1,0) [0|0] "" Vector__XXX
 SG_ RCM2_a063_passABStg1Sht2Bat m0 : 38|1@1+ (1,0) [0|0] "" Vector__XXX
 SG_ RCM2_a123_kneeABPassSht2Bat m1 : 38|1@1+ (1,0) [0|0] "" Vector__XXX
 SG_ RCM2_a183_hoodActuatorRSht2Bat m2 : 38|1@1+ (1,0) [0|0] "" Vector__XXX
 SG_ RCM2_a277_imuRollR8OffCompNegLife m3 : 38|1@1+ (1,0) [0|0] "" Vector__XXX
 SG_ RCM2_a364_upFrntSnsrRCommErr m4 : 38|1@1+ (1,0) [0|0] "" Vector__XXX
 SG_ RCM2_a431_presFrntLDoorSht2Bat m5 : 38|1@1+ (1,0) [0|0] "" Vector__XXX
 SG_ RCM2_a494_presRearLDoorCommErr m6 : 38|1@1+ (1,0) [0|0] "" Vector__XXX
 SG_ RCM2_a569_occPROSSht2Bat m7 : 38|1@1+ (1,0) [0|0] "" Vector__XXX
 SG_ RCM2_a643_comDASSafetyFrntMIA m8 : 38|1@1+ (1,0) [0|0] "" Vector__XXX
 SG_ RCM2_a799_internalFault m9 : 38|1@1+ (1,0) [0|0] "" Vector__XXX
 SG_ RCM2_a861_typeApprovalStringNotLearned m10 : 38|1@1+ (1,0) [0|0] "" Vector__XXX
 SG_ RCM2_a064_passABStg1Open m0 : 39|1@1+ (1,0) [0|0] "" Vector__XXX
 SG_ RCM2_a124_kneeABPassOpen m1 : 39|1@1+ (1,0) [0|0] "" Vector__XXX
 SG_ RCM2_a184_hoodActuatorROpen m2 : 39|1@1+ (1,0) [0|0] "" Vector__XXX
 SG_ RCM2_a278_imuRollR8OffCompPosFLDC m3 : 39|1@1+ (1,0) [0|0] "" Vector__XXX
 SG_ RCM2_a365_upFrntSnsrRInitTyp m4 : 39|1@1+ (1,0) [0|0] "" Vector__XXX
 SG_ RCM2_a432_presFrntLDoorOpen m5 : 39|1@1+ (1,0) [0|0] "" Vector__XXX
 SG_ RCM2_a495_presRearLDoorInitTyp m6 : 39|1@1+ (1,0) [0|0] "" Vector__XXX
 SG_ RCM2_a570_occPROSOpen m7 : 39|1@1+ (1,0) [0|0] "" Vector__XXX
 SG_ RCM2_a644_comDASSafetyFrntChkSm m8 : 39|1@1+ (1,0) [0|0] "" Vector__XXX
 SG_ RCM2_a800_crcFault m9 : 39|1@1+ (1,0) [0|0] "" Vector__XXX
 SG_ RCM2_a862_comPCSalertMatrixMIA m10 : 39|1@1+ (1,0) [0|0] "" Vector__XXX
 SG_ RCM2_a065_passABStg1Short m0 : 40|1@1+ (1,0) [0|0] "" Vector__XXX
 SG_ RCM2_a125_kneeABPassShort m1 : 40|1@1+ (1,0) [0|0] "" Vector__XXX
 SG_ RCM2_a185_hoodActuatorRShort m2 : 40|1@1+ (1,0) [0|0] "" Vector__XXX
 SG_ RCM2_a279_imuRollR8OffCompNegFLDC m3 : 40|1@1+ (1,0) [0|0] "" Vector__XXX
 SG_ RCM2_a366_upFrntSnsrRConfig m4 : 40|1@1+ (1,0) [0|0] "" Vector__XXX
 SG_ RCM2_a433_presFrntLDoorCrssCoup m5 : 40|1@1+ (1,0) [0|0] "" Vector__XXX
 SG_ RCM2_a496_presRearLDoorConfig m6 : 40|1@1+ (1,0) [0|0] "" Vector__XXX
 SG_ RCM2_a571_occPROSUndef m7 : 40|1@1+ (1,0) [0|0] "" Vector__XXX
 SG_ RCM2_a645_comDASSafetyFrntCntr m8 : 40|1@1+ (1,0) [0|0] "" Vector__XXX
 SG_ RCM2_a801_parameterLayoutID m9 : 40|1@1+ (1,0) [0|0] "" Vector__XXX
 SG_ RCM2_a863_comVCFRONTalertMatrixMIA m10 : 40|1@1+ (1,0) [0|0] "" Vector__XXX
 SG_ RCM2_a066_passABStg1CrssCoup m0 : 41|1@1+ (1,0) [0|0] "" Vector__XXX
 SG_ RCM2_a126_kneeABPassCrssCoup m1 : 41|1@1+ (1,0) [0|0] "" Vector__XXX
 SG_ RCM2_a186_hoodActuatorRCrssCoup m2 : 41|1@1+ (1,0) [0|0] "" Vector__XXX
 SG_ RCM2_a280_imuRollR8OffCompPosSLDC m3 : 41|1@1+ (1,0) [0|0] "" Vector__XXX
 SG_ RCM2_a367_upFrntSnsrRDefect m4 : 41|1@1+ (1,0) [0|0] "" Vector__XXX
 SG_ RCM2_a434_presFrntLDoorCommErr m5 : 41|1@1+ (1,0) [0|0] "" Vector__XXX
 SG_ RCM2_a497_presRearLDoorDefect m6 : 41|1@1+ (1,0) [0|0] "" Vector__XXX
 SG_ RCM2_a572_occPROSCrssCoup m7 : 41|1@1+ (1,0) [0|0] "" Vector__XXX
 SG_ RCM2_a646_comDIstateMIA m8 : 41|1@1+ (1,0) [0|0] "" Vector__XXX
 SG_ RCM2_a802_parameterTransferID m9 : 41|1@1+ (1,0) [0|0] "" Vector__XXX
 SG_ RCM2_a864_comGTWepochTimeMIA m10 : 41|1@1+ (1,0) [0|0] "" Vector__XXX
 SG_ RCM2_a067_passABStg1Config m0 : 42|1@1+ (1,0) [0|0] "" Vector__XXX
 SG_ RCM2_a127_kneeABPassConfig m1 : 42|1@1+ (1,0) [0|0] "" Vector__XXX
 SG_ RCM2_a187_hoodActuatorRConfig m2 : 42|1@1+ (1,0) [0|0] "" Vector__XXX
 SG_ RCM2_a281_imuRollR8OffCompNegSLDC m3 : 42|1@1+ (1,0) [0|0] "" Vector__XXX
 SG_ RCM2_a368_upFrntSnsrRSigMon m4 : 42|1@1+ (1,0) [0|0] "" Vector__XXX
 SG_ RCM2_a435_presFrntLDoorInitTyp m5 : 42|1@1+ (1,0) [0|0] "" Vector__XXX
 SG_ RCM2_a498_presRearLDoorSigMon m6 : 42|1@1+ (1,0) [0|0] "" Vector__XXX
 SG_ RCM2_a573_occPROSConfig m7 : 42|1@1+ (1,0) [0|0] "" Vector__XXX
 SG_ RCM2_a647_comDIstateChkSm m8 : 42|1@1+ (1,0) [0|0] "" Vector__XXX
 SG_ RCM2_a803_algoVerifySensorID m9 : 42|1@1+ (1,0) [0|0] "" Vector__XXX
 SG_ RCM2_a865_comVCLVBMSstatusHighMIA m10 : 42|1@1+ (1,0) [0|0] "" Vector__XXX
 SG_ RCM2_a068_passABStg2Sht2Gnd m0 : 43|1@1+ (1,0) [0|0] "" Vector__XXX
 SG_ RCM2_a128_sideAB1stRowLSht2Gnd m1 : 43|1@1+ (1,0) [0|0] "" Vector__XXX
 SG_ RCM2_a188_hoodActuatorLSht2Gnd m2 : 43|1@1+ (1,0) [0|0] "" Vector__XXX
 SG_ RCM2_a282_imuLongAOffCompPosLife m3 : 43|1@1+ (1,0) [0|0] "" Vector__XXX
 SG_ RCM2_a370_upFrntSnsrMidLSht2Gnd m4 : 43|1@1+ (1,0) [0|0] "" Vector__XXX
 SG_ RCM2_a436_presFrntLDoorConfig m5 : 43|1@1+ (1,0) [0|0] "" Vector__XXX
 SG_ RCM2_a500_presRearRDoorSht2Gnd m6 : 43|1@1+ (1,0) [0|0] "" Vector__XXX
 SG_ RCM2_a587_sbrRearNetworkSht2Gnd m7 : 43|1@1+ (1,0) [0|0] "" Vector__XXX
 SG_ RCM2_a648_comDIstateCntr m8 : 43|1@1+ (1,0) [0|0] "" Vector__XXX
 SG_ RCM2_a804_configDataInconsistent m9 : 43|1@1+ (1,0) [0|0] "" Vector__XXX
 SG_ RCM2_a866_comDASstatusMIA m10 : 43|1@1+ (1,0) [0|0] "" Vector__XXX
 SG_ RCM2_a069_passABStg2Sht2Bat m0 : 44|1@1+ (1,0) [0|0] "" Vector__XXX
 SG_ RCM2_a129_sideAB1stRowLSht2Bat m1 : 44|1@1+ (1,0) [0|0] "" Vector__XXX
 SG_ RCM2_a189_hoodActuatorLSht2Bat m2 : 44|1@1+ (1,0) [0|0] "" Vector__XXX
 SG_ RCM2_a283_imuLongAOffCompNegLife m3 : 44|1@1+ (1,0) [0|0] "" Vector__XXX
 SG_ RCM2_a371_upFrntSnsrMidLSht2Bat m4 : 44|1@1+ (1,0) [0|0] "" Vector__XXX
 SG_ RCM2_a437_presFrntLDoorDefect m5 : 44|1@1+ (1,0) [0|0] "" Vector__XXX
 SG_ RCM2_a501_presRearRDoorSht2Bat m6 : 44|1@1+ (1,0) [0|0] "" Vector__XXX
 SG_ RCM2_a588_sbrRearNetworkSht2Bat m7 : 44|1@1+ (1,0) [0|0] "" Vector__XXX
 SG_ RCM2_a649_comDIstate2MIA m8 : 44|1@1+ (1,0) [0|0] "" Vector__XXX
 SG_ RCM2_a805_swVersionWrong m9 : 44|1@1+ (1,0) [0|0] "" Vector__XXX
 SG_ RCM2_a868_headAB3rdRowRSht2Gnd m10 : 44|1@1+ (1,0) [0|0] "" Vector__XXX
 SG_ RCM2_a070_passABStg2Open m0 : 45|1@1+ (1,0) [0|0] "" Vector__XXX
 SG_ RCM2_a130_sideAB1stRowLOpen m1 : 45|1@1+ (1,0) [0|0] "" Vector__XXX
 SG_ RCM2_a190_hoodActuatorLOpen m2 : 45|1@1+ (1,0) [0|0] "" Vector__XXX
 SG_ RCM2_a284_imuLongAOffCompPosFLDC m3 : 45|1@1+ (1,0) [0|0] "" Vector__XXX
 SG_ RCM2_a372_upFrntSnsrMidLOpen m4 : 45|1@1+ (1,0) [0|0] "" Vector__XXX
 SG_ RCM2_a438_presFrntLDoorSigMon m5 : 45|1@1+ (1,0) [0|0] "" Vector__XXX
 SG_ RCM2_a502_presRearRDoorOpen m6 : 45|1@1+ (1,0) [0|0] "" Vector__XXX
 SG_ RCM2_a589_sbrRearNetworkOpen m7 : 45|1@1+ (1,0) [0|0] "" Vector__XXX
 SG_ RCM2_a650_comDIstate2ChkSm m8 : 45|1@1+ (1,0) [0|0] "" Vector__XXX
 SG_ RCM2_a806_configVINnotLearned m9 : 45|1@1+ (1,0) [0|0] "" Vector__XXX
 SG_ RCM2_a869_headAB3rdRowRSht2Bat m10 : 45|1@1+ (1,0) [0|0] "" Vector__XXX
 SG_ RCM2_a071_passABStg2Short m0 : 46|1@1+ (1,0) [0|0] "" Vector__XXX
 SG_ RCM2_a131_sideAB1stRowLShort m1 : 46|1@1+ (1,0) [0|0] "" Vector__XXX
 SG_ RCM2_a191_hoodActuatorLShort m2 : 46|1@1+ (1,0) [0|0] "" Vector__XXX
 SG_ RCM2_a285_imuLongAOffCompNegFLDC m3 : 46|1@1+ (1,0) [0|0] "" Vector__XXX
 SG_ RCM2_a373_upFrntSnsrMidLCrssCoup m4 : 46|1@1+ (1,0) [0|0] "" Vector__XXX
 SG_ RCM2_a439_presDoorAbsolute1 m5 : 46|1@1+ (1,0) [0|0] "" Vector__XXX
 SG_ RCM2_a503_presRearRDoorCrssCoup m6 : 46|1@1+ (1,0) [0|0] "" Vector__XXX
 SG_ RCM2_a590_sbrRearNetworkUndefined m7 : 46|1@1+ (1,0) [0|0] "" Vector__XXX
 SG_ RCM2_a651_comDIstate2Cntr m8 : 46|1@1+ (1,0) [0|0] "" Vector__XXX
 SG_ RCM2_a807_configVINmismatch m9 : 46|1@1+ (1,0) [0|0] "" Vector__XXX
 SG_ RCM2_a870_headAB3rdRowROpen m10 : 46|1@1+ (1,0) [0|0] "" Vector__XXX
 SG_ RCM2_a072_passABStg2CrssCoup m0 : 47|1@1+ (1,0) [0|0] "" Vector__XXX
 SG_ RCM2_a132_sideAB1stRowLCrssCoup m1 : 47|1@1+ (1,0) [0|0] "" Vector__XXX
 SG_ RCM2_a192_hoodActuatorLCrssCoup m2 : 47|1@1+ (1,0) [0|0] "" Vector__XXX
 SG_ RCM2_a286_imuLongAOffCompPosSLDC m3 : 47|1@1+ (1,0) [0|0] "" Vector__XXX
 SG_ RCM2_a374_upFrntSnsrMidLCommErr m4 : 47|1@1+ (1,0) [0|0] "" Vector__XXX
 SG_ RCM2_a440_presFrntRDoorSht2Gnd m5 : 47|1@1+ (1,0) [0|0] "" Vector__XXX
 SG_ RCM2_a504_presRearRDoorCommErr m6 : 47|1@1+ (1,0) [0|0] "" Vector__XXX
 SG_ RCM2_a591_sbrRearNetworkCrssCoup m7 : 47|1@1+ (1,0) [0|0] "" Vector__XXX
 SG_ RCM2_a652_ambientTempFaulted m8 : 47|1@1+ (1,0) [0|0] "" Vector__XXX
 SG_ RCM2_a808_configDriveNotLearned m9 : 47|1@1+ (1,0) [0|0] "" Vector__XXX
 SG_ RCM2_a871_headAB3rdRowRShort m10 : 47|1@1+ (1,0) [0|0] "" Vector__XXX
 SG_ RCM2_a073_passABStg2Config m0 : 48|1@1+ (1,0) [0|0] "" Vector__XXX
 SG_ RCM2_a133_sideAB1stRowLConfig m1 : 48|1@1+ (1,0) [0|0] "" Vector__XXX
 SG_ RCM2_a193_hoodActuatorLConfig m2 : 48|1@1+ (1,0) [0|0] "" Vector__XXX
 SG_ RCM2_a287_imuLongAOffCompNegSLDC m3 : 48|1@1+ (1,0) [0|0] "" Vector__XXX
 SG_ RCM2_a375_upFrntSnsrMidLInitTyp m4 : 48|1@1+ (1,0) [0|0] "" Vector__XXX
 SG_ RCM2_a441_presFrntRDoorSht2Bat m5 : 48|1@1+ (1,0) [0|0] "" Vector__XXX
 SG_ RCM2_a505_presRearRDoorInitTyp m6 : 48|1@1+ (1,0) [0|0] "" Vector__XXX
 SG_ RCM2_a592_sbrRearNetworkConfig m7 : 48|1@1+ (1,0) [0|0] "" Vector__XXX
 SG_ RCM2_a653_comGTWESP1MIA m8 : 48|1@1+ (1,0) [0|0] "" Vector__XXX
 SG_ RCM2_a809_configDriveMismatch m9 : 48|1@1+ (1,0) [0|0] "" Vector__XXX
 SG_ RCM2_a872_headAB3rdRowRCrossC m10 : 48|1@1+ (1,0) [0|0] "" Vector__XXX
 SG_ RCM2_a074_passActiveVentSht2Gnd m0 : 49|1@1+ (1,0) [0|0] "" Vector__XXX
 SG_ RCM2_a134_sideAB1stRowRSht2Gnd m1 : 49|1@1+ (1,0) [0|0] "" Vector__XXX
 SG_ RCM2_a194_driverABAVSht2Gnd m2 : 49|1@1+ (1,0) [0|0] "" Vector__XXX
 SG_ RCM2_a288_imuLatAcOffCompPosLife m3 : 49|1@1+ (1,0) [0|0] "" Vector__XXX
 SG_ RCM2_a376_upFrntSnsrMidLConfig m4 : 49|1@1+ (1,0) [0|0] "" Vector__XXX
 SG_ RCM2_a442_presFrntRDoorOpen m5 : 49|1@1+ (1,0) [0|0] "" Vector__XXX
 SG_ RCM2_a506_presRearRDoorConfig m6 : 49|1@1+ (1,0) [0|0] "" Vector__XXX
 SG_ RCM2_a593_driveOrientationSht2Gnd m7 : 49|1@1+ (1,0) [0|0] "" Vector__XXX
 SG_ RCM2_a654_comGTWESP1ChkSm m8 : 49|1@1+ (1,0) [0|0] "" Vector__XXX
 SG_ RCM2_a810_bootUpActionFailure m9 : 49|1@1+ (1,0) [0|0] "" Vector__XXX
 SG_ RCM2_a873_headAB3rdRowRConfig m10 : 49|1@1+ (1,0) [0|0] "" Vector__XXX
 SG_ RCM2_a075_passActiveVentSht2Bat m0 : 50|1@1+ (1,0) [0|0] "" Vector__XXX
 SG_ RCM2_a135_sideAB1stRowRSht2Bat m1 : 50|1@1+ (1,0) [0|0] "" Vector__XXX
 SG_ RCM2_a195_driverABAVSht2Bat m2 : 50|1@1+ (1,0) [0|0] "" Vector__XXX
 SG_ RCM2_a289_imuLatAcOffCompNegLife m3 : 50|1@1+ (1,0) [0|0] "" Vector__XXX
 SG_ RCM2_a377_upFrntSnsrMidLDefect m4 : 50|1@1+ (1,0) [0|0] "" Vector__XXX
 SG_ RCM2_a443_presFrntRDoorCrssCoup m5 : 50|1@1+ (1,0) [0|0] "" Vector__XXX
 SG_ RCM2_a507_presRearRDoorDefect m6 : 50|1@1+ (1,0) [0|0] "" Vector__XXX
 SG_ RCM2_a594_driveOrientationSht2Bat m7 : 50|1@1+ (1,0) [0|0] "" Vector__XXX
 SG_ RCM2_a655_comGTWESP1Cntr m8 : 50|1@1+ (1,0) [0|0] "" Vector__XXX
 SG_ RCM2_a811_comAxleSpeed m9 : 50|1@1+ (1,0) [0|0] "" Vector__XXX
 SG_ RCM2_a874_headAB3rdRowLSht2Gnd m10 : 50|1@1+ (1,0) [0|0] "" Vector__XXX
 SG_ RCM2_a076_passActiveVentOpen m0 : 51|1@1+ (1,0) [0|0] "" Vector__XXX
 SG_ RCM2_a136_sideAB1stRowROpen m1 : 51|1@1+ (1,0) [0|0] "" Vector__XXX
 SG_ RCM2_a196_driverABAVOpen m2 : 51|1@1+ (1,0) [0|0] "" Vector__XXX
 SG_ RCM2_a290_imuLatAcOffCompPosFLDC m3 : 51|1@1+ (1,0) [0|0] "" Vector__XXX
 SG_ RCM2_a378_upFrntSnsrMidLSigMon m4 : 51|1@1+ (1,0) [0|0] "" Vector__XXX
 SG_ RCM2_a444_presFrntRDoorCommErr m5 : 51|1@1+ (1,0) [0|0] "" Vector__XXX
 SG_ RCM2_a508_presRearRDoorSigMon m6 : 51|1@1+ (1,0) [0|0] "" Vector__XXX
 SG_ RCM2_a595_driveOrientationOpen m7 : 51|1@1+ (1,0) [0|0] "" Vector__XXX
 SG_ RCM2_a656_comVCSEATPrestMIA m8 : 51|1@1+ (1,0) [0|0] "" Vector__XXX
 SG_ RCM2_a812_idfMisuseMonitoringErr m9 : 51|1@1+ (1,0) [0|0] "" Vector__XXX
 SG_ RCM2_a875_headAB3rdRowLSht2Bat m10 : 51|1@1+ (1,0) [0|0] "" Vector__XXX
 SG_ RCM2_a077_passActiveVentShort m0 : 52|1@1+ (1,0) [0|0] "" Vector__XXX
 SG_ RCM2_a137_sideAB1stRowRShort m1 : 52|1@1+ (1,0) [0|0] "" Vector__XXX
 SG_ RCM2_a197_driverABAVShort m2 : 52|1@1+ (1,0) [0|0] "" Vector__XXX
 SG_ RCM2_a291_imuLatAcOffCompNegFLDC m3 : 52|1@1+ (1,0) [0|0] "" Vector__XXX
 SG_ RCM2_a380_upFrntSnsrMidRSht2Gnd m4 : 52|1@1+ (1,0) [0|0] "" Vector__XXX
 SG_ RCM2_a445_presFrntRDoorInitTyp m5 : 52|1@1+ (1,0) [0|0] "" Vector__XXX
 SG_ RCM2_a509_sideAccelDPilLSht2Gnd m6 : 52|1@1+ (1,0) [0|0] "" Vector__XXX
 SG_ RCM2_a596_driveOrientationUndefined m7 : 52|1@1+ (1,0) [0|0] "" Vector__XXX
 SG_ RCM2_a657_comVCSEATPrestChkSm m8 : 52|1@1+ (1,0) [0|0] "" Vector__XXX
 SG_ RCM2_a813_idfEnviMonitoringError m9 : 52|1@1+ (1,0) [0|0] "" Vector__XXX
 SG_ RCM2_a876_headAB3rdRowLOpen m10 : 52|1@1+ (1,0) [0|0] "" Vector__XXX
 SG_ RCM2_a078_passActiveVentCrssCoup m0 : 53|1@1+ (1,0) [0|0] "" Vector__XXX
 SG_ RCM2_a138_sideAB1stRowRCrssCoup m1 : 53|1@1+ (1,0) [0|0] "" Vector__XXX
 SG_ RCM2_a198_driverABAVCrossCoup m2 : 53|1@1+ (1,0) [0|0] "" Vector__XXX
 SG_ RCM2_a292_imuLatAcOffCompPosSLDC m3 : 53|1@1+ (1,0) [0|0] "" Vector__XXX
 SG_ RCM2_a381_upFrntSnsrMidRSht2Bat m4 : 53|1@1+ (1,0) [0|0] "" Vector__XXX
 SG_ RCM2_a446_presFrntRDoorConfig m5 : 53|1@1+ (1,0) [0|0] "" Vector__XXX
 SG_ RCM2_a510_sideAccelDPilLSht2Bat m6 : 53|1@1+ (1,0) [0|0] "" Vector__XXX
 SG_ RCM2_a597_driveOrientationCrssCoup m7 : 53|1@1+ (1,0) [0|0] "" Vector__XXX
 SG_ RCM2_a658_comVCSEATPrestCntr m8 : 53|1@1+ (1,0) [0|0] "" Vector__XXX
 SG_ RCM2_a814_idfEnviMonitoringEvent m9 : 53|1@1+ (1,0) [0|0] "" Vector__XXX
 SG_ RCM2_a877_headAB3rdRowLShort m10 : 53|1@1+ (1,0) [0|0] "" Vector__XXX
 SG_ RCM2_a079_passActiveVentConfig m0 : 54|1@1+ (1,0) [0|0] "" Vector__XXX
 SG_ RCM2_a139_sideAB1stRowRConfig m1 : 54|1@1+ (1,0) [0|0] "" Vector__XXX
 SG_ RCM2_a199_driverABAVConfig m2 : 54|1@1+ (1,0) [0|0] "" Vector__XXX
 SG_ RCM2_a293_imuLatAcOffCompNegSLDC m3 : 54|1@1+ (1,0) [0|0] "" Vector__XXX
 SG_ RCM2_a382_upFrntSnsrMidROpen m4 : 54|1@1+ (1,0) [0|0] "" Vector__XXX
 SG_ RCM2_a447_presFrntRDoorDefect m5 : 54|1@1+ (1,0) [0|0] "" Vector__XXX
 SG_ RCM2_a511_sideAccelDPilLOpen m6 : 54|1@1+ (1,0) [0|0] "" Vector__XXX
 SG_ RCM2_a598_driveOrientationConfig m7 : 54|1@1+ (1,0) [0|0] "" Vector__XXX
 SG_ RCM2_a659_comVCSEATPbuckle m8 : 54|1@1+ (1,0) [0|0] "" Vector__XXX
 SG_ RCM2_a815_upFrntPedProMLSht2Gnd m9 : 54|1@1+ (1,0) [0|0] "" Vector__XXX
 SG_ RCM2_a878_headAB3rdRowLCrossC m10 : 54|1@1+ (1,0) [0|0] "" Vector__XXX
 SG_ RCM2_a080_pretenShldLeftSht2Gnd m0 : 55|1@1+ (1,0) [0|0] "" Vector__XXX
 SG_ RCM2_a140_hvdPyroSht2Gnd m1 : 55|1@1+ (1,0) [0|0] "" Vector__XXX
 SG_ RCM2_a200_driverFSABSht2Gnd m2 : 55|1@1+ (1,0) [0|0] "" Vector__XXX
 SG_ RCM2_a294_imuVertAOffCompPosLife m3 : 55|1@1+ (1,0) [0|0] "" Vector__XXX
 SG_ RCM2_a383_upFrntSnsrMidRCrssCoup m4 : 55|1@1+ (1,0) [0|0] "" Vector__XXX
 SG_ RCM2_a448_presFrntRDoorSigMon m5 : 55|1@1+ (1,0) [0|0] "" Vector__XXX
 SG_ RCM2_a512_sideAccelDPilLCrssCoup m6 : 55|1@1+ (1,0) [0|0] "" Vector__XXX
 SG_ RCM2_a600_comCANinternalTimeout m7 : 55|1@1+ (1,0) [0|0] "" Vector__XXX
 SG_ RCM2_a660_comVCSEATPOccpy m8 : 55|1@1+ (1,0) [0|0] "" Vector__XXX
 SG_ RCM2_a816_upFrntPedProMLSht2Bat m9 : 55|1@1+ (1,0) [0|0] "" Vector__XXX
 SG_ RCM2_a879_headAB3rdRowLConfig m10 : 55|1@1+ (1,0) [0|0] "" Vector__XXX
 SG_ RCM2_a081_pretenShldLeftSht2Bat m0 : 56|1@1+ (1,0) [0|0] "" Vector__XXX
 SG_ RCM2_a141_hvdPyroSht2Bat m1 : 56|1@1+ (1,0) [0|0] "" Vector__XXX
 SG_ RCM2_a201_driverFSABSht2Bat m2 : 56|1@1+ (1,0) [0|0] "" Vector__XXX
 SG_ RCM2_a295_imuVertAOffCompNegLife m3 : 56|1@1+ (1,0) [0|0] "" Vector__XXX
 SG_ RCM2_a384_upFrntSnsrMidRCommErr m4 : 56|1@1+ (1,0) [0|0] "" Vector__XXX
 SG_ RCM2_a449_presDoorAbsolute2 m5 : 56|1@1+ (1,0) [0|0] "" Vector__XXX
 SG_ RCM2_a513_sideAccelDPilLCommErr m6 : 56|1@1+ (1,0) [0|0] "" Vector__XXX
 SG_ RCM2_a601_comChassisCANSilent m7 : 56|1@1+ (1,0) [0|0] "" Vector__XXX
 SG_ RCM2_a661_comVCSEATPocs m8 : 56|1@1+ (1,0) [0|0] "" Vector__XXX
 SG_ RCM2_a817_upFrntPedProMLOpen m9 : 56|1@1+ (1,0) [0|0] "" Vector__XXX
 SG_ RCM2_a880_comVCLEFT3rLBuckle m10 : 56|1@1+ (1,0) [0|0] "" Vector__XXX
 SG_ RCM2_a082_pretenShldLeftOpen m0 : 57|1@1+ (1,0) [0|0] "" Vector__XXX
 SG_ RCM2_a142_hvdPyroOpen m1 : 57|1@1+ (1,0) [0|0] "" Vector__XXX
 SG_ RCM2_a202_driverFSABOpen m2 : 57|1@1+ (1,0) [0|0] "" Vector__XXX
 SG_ RCM2_a296_imuVertAOffCompPosFLDC m3 : 57|1@1+ (1,0) [0|0] "" Vector__XXX
 SG_ RCM2_a385_upFrntSnsrMidRInitTyp m4 : 57|1@1+ (1,0) [0|0] "" Vector__XXX
 SG_ RCM2_a450_presPedProLSht2Gnd m5 : 57|1@1+ (1,0) [0|0] "" Vector__XXX
 SG_ RCM2_a514_sideAccelDPilLInitTyp m6 : 57|1@1+ (1,0) [0|0] "" Vector__XXX
 SG_ RCM2_a602_comChassisCANBusOff m7 : 57|1@1+ (1,0) [0|0] "" Vector__XXX
 SG_ RCM2_a662_comVCSEATPstps m8 : 57|1@1+ (1,0) [0|0] "" Vector__XXX
 SG_ RCM2_a818_upFrntPedProMLCrssCoup m9 : 57|1@1+ (1,0) [0|0] "" Vector__XXX
 SG_ RCM2_a881_comVCRIGHT3rRBuckle m10 : 57|1@1+ (1,0) [0|0] "" Vector__XXX
 SG_ RCM2_a083_pretenShldLeftShort m0 : 58|1@1+ (1,0) [0|0] "" Vector__XXX
 SG_ RCM2_a143_hvdPyroShort m1 : 58|1@1+ (1,0) [0|0] "" Vector__XXX
 SG_ RCM2_a203_driverFSABShort m2 : 58|1@1+ (1,0) [0|0] "" Vector__XXX
 SG_ RCM2_a297_imuVertAOffCompNegFLDC m3 : 58|1@1+ (1,0) [0|0] "" Vector__XXX
 SG_ RCM2_a386_upFrntSnsrMidRConfig m4 : 58|1@1+ (1,0) [0|0] "" Vector__XXX
 SG_ RCM2_a451_presPedProLSht2Bat m5 : 58|1@1+ (1,0) [0|0] "" Vector__XXX
 SG_ RCM2_a515_sideAccelDPilLConfig m6 : 58|1@1+ (1,0) [0|0] "" Vector__XXX
 SG_ RCM2_a603_comPARTYCANSilent m7 : 58|1@1+ (1,0) [0|0] "" Vector__XXX
 SG_ RCM2_a663_comVCSEATDrestMIA m8 : 58|1@1+ (1,0) [0|0] "" Vector__XXX
 SG_ RCM2_a819_upFrntPedProMLCommErr m9 : 58|1@1+ (1,0) [0|0] "" Vector__XXX
 SG_ RCM2_a084_pretenShldLeftCrossC m0 : 59|1@1+ (1,0) [0|0] "" Vector__XXX
 SG_ RCM2_a144_hvdPyroCrssCoup m1 : 59|1@1+ (1,0) [0|0] "" Vector__XXX
 SG_ RCM2_a204_driverFSABCrossCoup m2 : 59|1@1+ (1,0) [0|0] "" Vector__XXX
 SG_ RCM2_a298_imuVertAOffCompPosSLDC m3 : 59|1@1+ (1,0) [0|0] "" Vector__XXX
 SG_ RCM2_a387_upFrntSnsrMidRDefect m4 : 59|1@1+ (1,0) [0|0] "" Vector__XXX
 SG_ RCM2_a452_presPedProLOpen m5 : 59|1@1+ (1,0) [0|0] "" Vector__XXX
 SG_ RCM2_a516_sideAccelDPilLDefect m6 : 59|1@1+ (1,0) [0|0] "" Vector__XXX
 SG_ RCM2_a604_comPARTYCANBusOff m7 : 59|1@1+ (1,0) [0|0] "" Vector__XXX
 SG_ RCM2_a664_comVCSEATDrestChkSm m8 : 59|1@1+ (1,0) [0|0] "" Vector__XXX
 SG_ RCM2_a820_upFrntPedProMLIntTyp m9 : 59|1@1+ (1,0) [0|0] "" Vector__XXX
 SG_ RCM2_a085_pretenShldLeftConfig m0 : 60|1@1+ (1,0) [0|0] "" Vector__XXX
 SG_ RCM2_a145_hvdPyroConfig m1 : 60|1@1+ (1,0) [0|0] "" Vector__XXX
 SG_ RCM2_a205_driverFSABConfig m2 : 60|1@1+ (1,0) [0|0] "" Vector__XXX
 SG_ RCM2_a299_imuVertAOffCompNegSLDC m3 : 60|1@1+ (1,0) [0|0] "" Vector__XXX
 SG_ RCM2_a388_upFrntSnsrMidRSigMon m4 : 60|1@1+ (1,0) [0|0] "" Vector__XXX
 SG_ RCM2_a453_presPedProLCrssCoup m5 : 60|1@1+ (1,0) [0|0] "" Vector__XXX
 SG_ RCM2_a517_sideAccelDPilLSigMon m6 : 60|1@1+ (1,0) [0|0] "" Vector__XXX
 SG_ RCM2_a605_comStwAngStatMIA m7 : 60|1@1+ (1,0) [0|0] "" Vector__XXX
 SG_ RCM2_a665_comVCSEATDrestCntr m8 : 60|1@1+ (1,0) [0|0] "" Vector__XXX
 SG_ RCM2_a821_upFrntPedProMLConfig m9 : 60|1@1+ (1,0) [0|0] "" Vector__XXX
 SG_ RCM2_a086_pretenShldRightSht2Gnd m0 : 61|1@1+ (1,0) [0|0] "" Vector__XXX
 SG_ RCM2_a146_curABLeftSht2Gnd m1 : 61|1@1+ (1,0) [0|0] "" Vector__XXX
 SG_ RCM2_a206_sideAB2ndRowLSht2Gnd m2 : 61|1@1+ (1,0) [0|0] "" Vector__XXX
 SG_ RCM2_a300_imuAccXHgMonChlPerm m3 : 61|1@1+ (1,0) [0|0] "" Vector__XXX
 SG_ RCM2_a390_sideAccelBPilLSht2Gnd m4 : 61|1@1+ (1,0) [0|0] "" Vector__XXX
 SG_ RCM2_a454_presPedProLCommErr m5 : 61|1@1+ (1,0) [0|0] "" Vector__XXX
 SG_ RCM2_a518_sideAccelDPilRSht2Gnd m6 : 61|1@1+ (1,0) [0|0] "" Vector__XXX
 SG_ RCM2_a606_comStwAngStatChkSm m7 : 61|1@1+ (1,0) [0|0] "" Vector__XXX
 SG_ RCM2_a666_comVCSEATDbuckle m8 : 61|1@1+ (1,0) [0|0] "" Vector__XXX
 SG_ RCM2_a822_upFrntPedProMLDefect m9 : 61|1@1+ (1,0) [0|0] "" Vector__XXX
 SG_ RCM2_a087_pretenShldRightSht2Bat m0 : 62|1@1+ (1,0) [0|0] "" Vector__XXX
 SG_ RCM2_a147_curABLeftSht2Bat m1 : 62|1@1+ (1,0) [0|0] "" Vector__XXX
 SG_ RCM2_a207_sideAB2ndRowLSht2Bat m2 : 62|1@1+ (1,0) [0|0] "" Vector__XXX
 SG_ RCM2_a301_imuAccXHgMonChlTemp m3 : 62|1@1+ (1,0) [0|0] "" Vector__XXX
 SG_ RCM2_a391_sideAccelBPilLSht2Bat m4 : 62|1@1+ (1,0) [0|0] "" Vector__XXX
 SG_ RCM2_a455_presPedProLInitTyp m5 : 62|1@1+ (1,0) [0|0] "" Vector__XXX
 SG_ RCM2_a519_sideAccelDPilRSht2Bat m6 : 62|1@1+ (1,0) [0|0] "" Vector__XXX
 SG_ RCM2_a607_comStwAngStatCntr m7 : 62|1@1+ (1,0) [0|0] "" Vector__XXX
 SG_ RCM2_a667_comVCSEATDOccpy m8 : 62|1@1+ (1,0) [0|0] "" Vector__XXX
 SG_ RCM2_a823_upFrntPedProMLSigMon m9 : 62|1@1+ (1,0) [0|0] "" Vector__XXX
 SG_ RCM2_a088_pretenShldRightOpen m0 : 63|1@1+ (1,0) [0|0] "" Vector__XXX
 SG_ RCM2_a148_curABLeftOpen m1 : 63|1@1+ (1,0) [0|0] "" Vector__XXX
 SG_ RCM2_a208_sideAB2ndRowLOpen m2 : 63|1@1+ (1,0) [0|0] "" Vector__XXX
 SG_ RCM2_a302_imuAccYHgMonChlPerm m3 : 63|1@1+ (1,0) [0|0] "" Vector__XXX
 SG_ RCM2_a392_sideAccelBPilLOpen m4 : 63|1@1+ (1,0) [0|0] "" Vector__XXX
 SG_ RCM2_a456_presPedProLConfig m5 : 63|1@1+ (1,0) [0|0] "" Vector__XXX
 SG_ RCM2_a520_sideAccelDPilROpen m6 : 63|1@1+ (1,0) [0|0] "" Vector__XXX
 SG_ RCM2_a608_comDItorque1MIA m7 : 63|1@1+ (1,0) [0|0] "" Vector__XXX
 SG_ RCM2_a668_comVCSEATDstps m8 : 63|1@1+ (1,0) [0|0] "" Vector__XXX
 SG_ RCM2_a824_upFrntPedProMRSht2Gnd m9 : 63|1@1+ (1,0) [0|0] "" Vector__XXX

BO_ 1010 BMS_kwhCountersMultiplexed: 8 Vector__XXX
 SG_ BMS_kwhCounter_Id M : 0|4@1+ (1,0) [0|0] "" Vector__XXX
 SG_ BMS_acChargerKwhTotal m0 : 8|32@1+ (0.001,0) [0|0] "" Vector__XXX
 SG_ BMS_dcChargerKwhTotal m1 : 8|32@1+ (0.001,0) [0|0] "" Vector__XXX
 SG_ BMS_kwhAcChargeTotalModule1 m5 : 8|28@1+ (0.001,0) [0|0] "" Vector__XXX
 SG_ BMS_kwhAcChargeTotalModule2 m7 : 8|28@1+ (0.001,0) [0|0] "" Vector__XXX
 SG_ BMS_kwhAcChargeTotalModule3 m9 : 8|28@1+ (0.001,0) [0|0] "" Vector__XXX
 SG_ BMS_kwhAcChargeTotalModule4 m11 : 8|28@1+ (0.001,0) [0|0] "" Vector__XXX
 SG_ BMS_kwhDischargeTotalModule1 m4 : 8|28@1+ (0.001,0) [0|0] "" Vector__XXX
 SG_ BMS_kwhDischargeTotalModule2 m6 : 8|28@1+ (0.001,0) [0|0] "" Vector__XXX
 SG_ BMS_kwhDischargeTotalModule3 m8 : 8|28@1+ (0.001,0) [0|0] "" Vector__XXX
 SG_ BMS_kwhDischargeTotalModule4 m10 : 8|28@1+ (0.001,0) [0|0] "" Vector__XXX
 SG_ BMS_kwhDriveDischargeTotal m3 : 8|32@1+ (0.001,0) [0|0] "" Vector__XXX
 SG_ BMS_kwhRegenChargeTotal m2 : 8|32@1+ (0.001,0) [0|0] "" Vector__XXX
 SG_ BMS_kwhChargeTotalModule1 m4 : 36|28@1+ (0.001,0) [0|0] "" Vector__XXX
 SG_ BMS_kwhChargeTotalModule2 m6 : 36|28@1+ (0.001,0) [0|0] "" Vector__XXX
 SG_ BMS_kwhChargeTotalModule3 m8 : 36|28@1+ (0.001,0) [0|0] "" Vector__XXX
 SG_ BMS_kwhChargeTotalModule4 m10 : 36|28@1+ (0.001,0) [0|0] "" Vector__XXX
 SG_ BMS_kwhDcChargeTotalModule1 m5 : 36|28@1+ (0.001,0) [0|0] "" Vector__XXX
 SG_ BMS_kwhDcChargeTotalModule2 m7 : 36|28@1+ (0.001,0) [0|0] "" Vector__XXX
 SG_ BMS_kwhDcChargeTotalModule3 m9 : 36|28@1+ (0.001,0) [0|0] "" Vector__XXX
 SG_ BMS_kwhDcChargeTotalModule4 m11 : 36|28@1+ (0.001,0) [0|0] "" Vector__XXX

BO_ 1012 LS_lightShow: 8 Vector__XXX
 SG_ LS_lightShowIndex M : 0|5@1+ (1,0) [0|0] "" Vector__XXX
 SG_ LS_lightLeftRampedChannel1Request m0 : 5|1@1+ (1,0) [0|0] "" Vector__XXX
 SG_ LS_mirrorRequestLeft m1 : 5|3@1+ (1,0) [0|0] "" Vector__XXX
 SG_ LS_lightLeftRampedChannel1Duration m0 : 6|2@1+ (1,0) [0|0] "" Vector__XXX
 SG_ LS_frontMatrix0 m7 : 8|8@1+ (1,0) [0|0] "" Vector__XXX
 SG_ LS_frontMatrix14 m9 : 8|8@1+ (1,0) [0|0] "" Vector__XXX
 SG_ LS_frontMatrix21 m10 : 8|8@1+ (1,0) [0|0] "" Vector__XXX
 SG_ LS_frontMatrix28 m11 : 8|8@1+ (1,0) [0|0] "" Vector__XXX
 SG_ LS_frontMatrix35 m12 : 8|8@1+ (1,0) [0|0] "" Vector__XXX
 SG_ LS_frontMatrix42 m13 : 8|8@1+ (1,0) [0|0] "" Vector__XXX
 SG_ LS_frontMatrix49 m14 : 8|8@1+ (1,0) [0|0] "" Vector__XXX
 SG_ LS_frontMatrix56 m15 : 8|8@1+ (1,0) [0|0] "" Vector__XXX
 SG_ LS_frontMatrix7 m8 : 8|8@1+ (1,0) [0|0] "" Vector__XXX
 SG_ LS_lightLeftRampedChannel2Request m0 : 8|1@1+ (1,0) [0|0] "" Vector__XXX
 SG_ LS_mirrorRequestRight m1 : 8|3@1+ (1,0) [0|0] "" Vector__XXX
 SG_ LS_rearMatrix10 m17 : 8|8@1+ (1,0) [0|0] "" Vector__XXX
 SG_ LS_rearMatrix17 m18 : 8|8@1+ (1,0) [0|0] "" Vector__XXX
 SG_ LS_rearMatrix24 m19 : 8|8@1+ (1,0) [0|0] "" Vector__XXX
 SG_ LS_rearMatrix3 m16 : 8|8@1+ (1,0) [0|0] "" Vector__XXX
 SG_ LS_rearMatrix31 m20 : 8|8@1+ (1,0) [0|0] "" Vector__XXX
 SG_ LS_rearMatrix38 m21 : 8|8@1+ (1,0) [0|0] "" Vector__XXX
 SG_ LS_rearMatrix45 m22 : 8|8@1+ (1,0) [0|0] "" Vector__XXX
 SG_ LS_rearMatrix52 m23 : 8|8@1+ (1,0) [0|0] "" Vector__XXX
 SG_ LS_rearMatrix59 m24 : 8|8@1+ (1,0) [0|0] "" Vector__XXX
 SG_ LS_rgbDoorFLForeRed m3 : 8|8@1+ (1,0) [0|0] "" Vector__XXX
 SG_ LS_rgbDoorFRForeRed m4 : 8|8@1+ (1,0) [0|0] "" Vector__XXX
 SG_ LS_rgbDoorRLForeRed m5 : 8|8@1+ (1,0) [0|0] "" Vector__XXX
 SG_ LS_rgbDoorRRForeRed m6 : 8|8@1+ (1,0) [0|0] "" Vector__XXX
 SG_ LS_rgbIPFLRed m2 : 8|8@1+ (1,0) [0|0] "" Vector__XXX
 SG_ LS_lightLeftRampedChannel2Duration m0 : 9|2@1+ (1,0) [0|0] "" Vector__XXX
 SG_ LS_liftgateRequest m1 : 11|3@1+ (1,0) [0|0] "" Vector__XXX
 SG_ LS_lightLeftRampedChannel3Request m0 : 11|1@1+ (1,0) [0|0] "" Vector__XXX
 SG_ LS_lightLeftRampedChannel3Duration m0 : 12|2@1+ (1,0) [0|0] "" Vector__XXX
 SG_ LS_lightLeftRampedChannel4Request m0 : 14|1@1+ (1,0) [0|0] "" Vector__XXX
 SG_ LS_frontMatrix1 m7 : 16|8@1+ (1,0) [0|0] "" Vector__XXX
 SG_ LS_frontMatrix15 m9 : 16|8@1+ (1,0) [0|0] "" Vector__XXX
 SG_ LS_frontMatrix22 m10 : 16|8@1+ (1,0) [0|0] "" Vector__XXX
 SG_ LS_frontMatrix29 m11 : 16|8@1+ (1,0) [0|0] "" Vector__XXX
 SG_ LS_frontMatrix36 m12 : 16|8@1+ (1,0) [0|0] "" Vector__XXX
 SG_ LS_frontMatrix43 m13 : 16|8@1+ (1,0) [0|0] "" Vector__XXX
 SG_ LS_frontMatrix50 m14 : 16|8@1+ (1,0) [0|0] "" Vector__XXX
 SG_ LS_frontMatrix57 m15 : 16|8@1+ (1,0) [0|0] "" Vector__XXX
 SG_ LS_frontMatrix8 m8 : 16|8@1+ (1,0) [0|0] "" Vector__XXX
 SG_ LS_lightLeftRampedChannel4Duration m0 : 16|2@1+ (1,0) [0|0] "" Vector__XXX
 SG_ LS_offroadLightBar0 m24 : 16|8@1+ (1,0) [0|0] "" Vector__XXX
 SG_ LS_rearMatrix11 m17 : 16|8@1+ (1,0) [0|0] "" Vector__XXX
 SG_ LS_rearMatrix18 m18 : 16|8@1+ (1,0) [0|0] "" Vector__XXX
 SG_ LS_rearMatrix25 m19 : 16|8@1+ (1,0) [0|0] "" Vector__XXX
 SG_ LS_rearMatrix32 m20 : 16|8@1+ (1,0) [0|0] "" Vector__XXX
 SG_ LS_rearMatrix39 m21 : 16|8@1+ (1,0) [0|0] "" Vector__XXX
 SG_ LS_rearMatrix4 m16 : 16|8@1+ (1,0) [0|0] "" Vector__XXX
 SG_ LS_rearMatrix46 m22 : 16|8@1+ (1,0) [0|0] "" Vector__XXX
 SG_ LS_rearMatrix53 m23 : 16|8@1+ (1,0) [0|0] "" Vector__XXX
 SG_ LS_rgbDoorFLForeGreen m3 : 16|8@1+ (1,0) [0|0] "" Vector__XXX
 SG_ LS_rgbDoorFRForeGreen m4 : 16|8@1+ (1,0) [0|0] "" Vector__XXX
 SG_ LS_rgbDoorRLForeGreen m5 : 16|8@1+ (1,0) [0|0] "" Vector__XXX
 SG_ LS_rgbDoorRRForeGreen m6 : 16|8@1+ (1,0) [0|0] "" Vector__XXX
 SG_ LS_rgbIPFLGreen m2 : 16|8@1+ (1,0) [0|0] "" Vector__XXX
 SG_ LS_windowRequestLF m1 : 16|3@1+ (1,0) [0|0] "" Vector__XXX
 SG_ LS_lightLeftRampedChannel5Request m0 : 18|1@1+ (1,0) [0|0] "" Vector__XXX
 SG_ LS_lightLeftRampedChannel5Duration m0 : 19|2@1+ (1,0) [0|0] "" Vector__XXX
 SG_ LS_windowRequestLR m1 : 19|3@1+ (1,0) [0|0] "" Vector__XXX
 SG_ LS_lightLeftRampedChannel6Request m0 : 21|1@1+ (1,0) [0|0] "" Vector__XXX
 SG_ LS_lightLeftRampedChannel6Duration m0 : 22|2@1+ (1,0) [0|0] "" Vector__XXX
 SG_ LS_frontMatrix16 m9 : 24|8@1+ (1,0) [0|0] "" Vector__XXX
 SG_ LS_frontMatrix2 m7 : 24|8@1+ (1,0) [0|0] "" Vector__XXX
 SG_ LS_frontMatrix23 m10 : 24|8@1+ (1,0) [0|0] "" Vector__XXX
 SG_ LS_frontMatrix30 m11 : 24|8@1+ (1,0) [0|0] "" Vector__XXX
 SG_ LS_frontMatrix37 m12 : 24|8@1+ (1,0) [0|0] "" Vector__XXX
 SG_ LS_frontMatrix44 m13 : 24|8@1+ (1,0) [0|0] "" Vector__XXX
 SG_ LS_frontMatrix51 m14 : 24|8@1+ (1,0) [0|0] "" Vector__XXX
 SG_ LS_frontMatrix58 m15 : 24|8@1+ (1,0) [0|0] "" Vector__XXX
 SG_ LS_frontMatrix9 m8 : 24|8@1+ (1,0) [0|0] "" Vector__XXX
 SG_ LS_lightLeftRampedChannel7Request m0 : 24|1@1+ (1,0) [0|0] "" Vector__XXX
 SG_ LS_offroadLightBar1 m24 : 24|8@1+ (1,0) [0|0] "" Vector__XXX
 SG_ LS_rearMatrix12 m17 : 24|8@1+ (1,0) [0|0] "" Vector__XXX
 SG_ LS_rearMatrix19 m18 : 24|8@1+ (1,0) [0|0] "" Vector__XXX
 SG_ LS_rearMatrix26 m19 : 24|8@1+ (1,0) [0|0] "" Vector__XXX
 SG_ LS_rearMatrix33 m20 : 24|8@1+ (1,0) [0|0] "" Vector__XXX
 SG_ LS_rearMatrix40 m21 : 24|8@1+ (1,0) [0|0] "" Vector__XXX
 SG_ LS_rearMatrix47 m22 : 24|8@1+ (1,0) [0|0] "" Vector__XXX
 SG_ LS_rearMatrix5 m16 : 24|8@1+ (1,0) [0|0] "" Vector__XXX
 SG_ LS_rearMatrix54 m23 : 24|8@1+ (1,0) [0|0] "" Vector__XXX
 SG_ LS_rgbDoorFLForeBlue m3 : 24|8@1+ (1,0) [0|0] "" Vector__XXX
 SG_ LS_rgbDoorFRForeBlue m4 : 24|8@1+ (1,0) [0|0] "" Vector__XXX
 SG_ LS_rgbDoorRLForeBlue m5 : 24|8@1+ (1,0) [0|0] "" Vector__XXX
 SG_ LS_rgbDoorRRForeBlue m6 : 24|8@1+ (1,0) [0|0] "" Vector__XXX
 SG_ LS_rgbIPFLBlue m2 : 24|8@1+ (1,0) [0|0] "" Vector__XXX
 SG_ LS_windowRequestRF m1 : 24|3@1+ (1,0) [0|0] "" Vector__XXX
 SG_ LS_lightLeftRampedChannel7Duration m0 : 25|2@1+ (1,0) [0|0] "" Vector__XXX
 SG_ LS_lightRightRampedChannel1Request m0 : 27|1@1+ (1,0) [0|0] "" Vector__XXX
 SG_ LS_windowRequestRR m1 : 27|3@1+ (1,0) [0|0] "" Vector__XXX
 SG_ LS_lightRightRampedChannel1Duration m0 : 28|2@1+ (1,0) [0|0] "" Vector__XXX
 SG_ LS_lightRightRampedChannel2Request m0 : 30|1@1+ (1,0) [0|0] "" Vector__XXX
 SG_ LS_lightRightRampedChannel2Duration m0 : 31|2@1+ (1,0) [0|0] "" Vector__XXX
 SG_ LS_frontMatrix10 m8 : 32|8@1+ (1,0) [0|0] "" Vector__XXX
 SG_ LS_frontMatrix17 m9 : 32|8@1+ (1,0) [0|0] "" Vector__XXX
 SG_ LS_frontMatrix24 m10 : 32|8@1+ (1,0) [0|0] "" Vector__XXX
 SG_ LS_frontMatrix3 m7 : 32|8@1+ (1,0) [0|0] "" Vector__XXX
 SG_ LS_frontMatrix31 m11 : 32|8@1+ (1,0) [0|0] "" Vector__XXX
 SG_ LS_frontMatrix38 m12 : 32|8@1+ (1,0) [0|0] "" Vector__XXX
 SG_ LS_frontMatrix45 m13 : 32|8@1+ (1,0) [0|0] "" Vector__XXX
 SG_ LS_frontMatrix52 m14 : 32|8@1+ (1,0) [0|0] "" Vector__XXX
 SG_ LS_frontMatrix59 m15 : 32|8@1+ (1,0) [0|0] "" Vector__XXX
 SG_ LS_offroadLightBar2 m24 : 32|8@1+ (1,0) [0|0] "" Vector__XXX
 SG_ LS_presentingHandleRequestLF m1 : 32|3@1+ (1,0) [0|0] "" Vector__XXX
 SG_ LS_rearMatrix13 m17 : 32|8@1+ (1,0) [0|0] "" Vector__XXX
 SG_ LS_rearMatrix20 m18 : 32|8@1+ (1,0) [0|0] "" Vector__XXX
 SG_ LS_rearMatrix27 m19 : 32|8@1+ (1,0) [0|0] "" Vector__XXX
 SG_ LS_rearMatrix34 m20 : 32|8@1+ (1,0) [0|0] "" Vector__XXX
 SG_ LS_rearMatrix41 m21 : 32|8@1+ (1,0) [0|0] "" Vector__XXX
 SG_ LS_rearMatrix48 m22 : 32|8@1+ (1,0) [0|0] "" Vector__XXX
 SG_ LS_rearMatrix55 m23 : 32|8@1+ (1,0) [0|0] "" Vector__XXX
 SG_ LS_rearMatrix6 m16 : 32|8@1+ (1,0) [0|0] "" Vector__XXX
 SG_ LS_rgbDoorFLAftRed m3 : 32|8@1+ (1,0) [0|0] "" Vector__XXX
 SG_ LS_rgbDoorFRAftRed m4 : 32|8@1+ (1,0) [0|0] "" Vector__XXX
 SG_ LS_rgbDoorRLAftRed m5 : 32|8@1+ (1,0) [0|0] "" Vector__XXX
 SG_ LS_rgbDoorRRAftRed m6 : 32|8@1+ (1,0) [0|0] "" Vector__XXX
 SG_ LS_rgbIPFRRed m2 : 32|8@1+ (1,0) [0|0] "" Vector__XXX
 SG_ LS_lightRightRampedChannel3Request m0 : 33|1@1+ (1,0) [0|0] "" Vector__XXX
 SG_ LS_lightRightRampedChannel3Duration m0 : 34|2@1+ (1,0) [0|0] "" Vector__XXX
 SG_ LS_presentingHandleRequestLR m1 : 35|3@1+ (1,0) [0|0] "" Vector__XXX
 SG_ LS_lightRightRampedChannel4Request m0 : 36|1@1+ (1,0) [0|0] "" Vector__XXX
 SG_ LS_lightRightRampedChannel4Duration m0 : 37|2@1+ (1,0) [0|0] "" Vector__XXX
 SG_ LS_lightRightRampedChannel5Request m0 : 39|1@1+ (1,0) [0|0] "" Vector__XXX
 SG_ LS_frontMatrix11 m8 : 40|8@1+ (1,0) [0|0] "" Vector__XXX
 SG_ LS_frontMatrix18 m9 : 40|8@1+ (1,0) [0|0] "" Vector__XXX
 SG_ LS_frontMatrix25 m10 : 40|8@1+ (1,0) [0|0] "" Vector__XXX
 SG_ LS_frontMatrix32 m11 : 40|8@1+ (1,0) [0|0] "" Vector__XXX
 SG_ LS_frontMatrix39 m12 : 40|8@1+ (1,0) [0|0] "" Vector__XXX
 SG_ LS_frontMatrix4 m7 : 40|8@1+ (1,0) [0|0] "" Vector__XXX
 SG_ LS_frontMatrix46 m13 : 40|8@1+ (1,0) [0|0] "" Vector__XXX
 SG_ LS_frontMatrix53 m14 : 40|8@1+ (1,0) [0|0] "" Vector__XXX
 SG_ LS_lightRightRampedChannel5Duration m0 : 40|2@1+ (1,0) [0|0] "" Vector__XXX
 SG_ LS_offroadLightBar3 m24 : 40|8@1+ (1,0) [0|0] "" Vector__XXX
 SG_ LS_presentingHandleRequestRF m1 : 40|3@1+ (1,0) [0|0] "" Vector__XXX
 SG_ LS_rearMatrix0 m15 : 40|8@1+ (1,0) [0|0] "" Vector__XXX
 SG_ LS_rearMatrix14 m17 : 40|8@1+ (1,0) [0|0] "" Vector__XXX
 SG_ LS_rearMatrix21 m18 : 40|8@1+ (1,0) [0|0] "" Vector__XXX
 SG_ LS_rearMatrix28 m19 : 40|8@1+ (1,0) [0|0] "" Vector__XXX
 SG_ LS_rearMatrix35 m20 : 40|8@1+ (1,0) [0|0] "" Vector__XXX
 SG_ LS_rearMatrix42 m21 : 40|8@1+ (1,0) [0|0] "" Vector__XXX
 SG_ LS_rearMatrix49 m22 : 40|8@1+ (1,0) [0|0] "" Vector__XXX
 SG_ LS_rearMatrix56 m23 : 40|8@1+ (1,0) [0|0] "" Vector__XXX
 SG_ LS_rearMatrix7 m16 : 40|8@1+ (1,0) [0|0] "" Vector__XXX
 SG_ LS_rgbDoorFLAftGreen m3 : 40|8@1+ (1,0) [0|0] "" Vector__XXX
 SG_ LS_rgbDoorFRAftGreen m4 : 40|8@1+ (1,0) [0|0] "" Vector__XXX
 SG_ LS_rgbDoorRLAftGreen m5 : 40|8@1+ (1,0) [0|0] "" Vector__XXX
 SG_ LS_rgbDoorRRAftGreen m6 : 40|8@1+ (1,0) [0|0] "" Vector__XXX
 SG_ LS_rgbIPFRGreen m2 : 40|8@1+ (1,0) [0|0] "" Vector__XXX
 SG_ LS_lightRightRampedChannel6Request m0 : 42|1@1+ (1,0) [0|0] "" Vector__XXX
 SG_ LS_lightRightRampedChannel6Duration m0 : 43|2@1+ (1,0) [0|0] "" Vector__XXX
 SG_ LS_presentingHandleRequestRR m1 : 43|3@1+ (1,0) [0|0] "" Vector__XXX
 SG_ LS_lightRightRampedChannel7Request m0 : 45|1@1+ (1,0) [0|0] "" Vector__XXX
 SG_ LS_lightRightRampedChannel7Duration m0 : 46|2@1+ (1,0) [0|0] "" Vector__XXX
 SG_ LS_powerFrontDoorRequestLeft m1 : 46|3@1+ (1,0) [0|0] "" Vector__XXX
 SG_ LS_frontMatrix12 m8 : 48|8@1+ (1,0) [0|0] "" Vector__XXX
 SG_ LS_frontMatrix19 m9 : 48|8@1+ (1,0) [0|0] "" Vector__XXX
 SG_ LS_frontMatrix26 m10 : 48|8@1+ (1,0) [0|0] "" Vector__XXX
 SG_ LS_frontMatrix33 m11 : 48|8@1+ (1,0) [0|0] "" Vector__XXX
 SG_ LS_frontMatrix40 m12 : 48|8@1+ (1,0) [0|0] "" Vector__XXX
 SG_ LS_frontMatrix47 m13 : 48|8@1+ (1,0) [0|0] "" Vector__XXX
 SG_ LS_frontMatrix5 m7 : 48|8@1+ (1,0) [0|0] "" Vector__XXX
 SG_ LS_frontMatrix54 m14 : 48|8@1+ (1,0) [0|0] "" Vector__XXX
 SG_ LS_lightRearTurnLeftRequest m0 : 48|1@1+ (1,0) [0|0] "" Vector__XXX
 SG_ LS_offroadLightBar4 m24 : 48|8@1+ (1,0) [0|0] "" Vector__XXX
 SG_ LS_rearMatrix1 m15 : 48|8@1+ (1,0) [0|0] "" Vector__XXX
 SG_ LS_rearMatrix15 m17 : 48|8@1+ (1,0) [0|0] "" Vector__XXX
 SG_ LS_rearMatrix22 m18 : 48|8@1+ (1,0) [0|0] "" Vector__XXX
 SG_ LS_rearMatrix29 m19 : 48|8@1+ (1,0) [0|0] "" Vector__XXX
 SG_ LS_rearMatrix36 m20 : 48|8@1+ (1,0) [0|0] "" Vector__XXX
 SG_ LS_rearMatrix43 m21 : 48|8@1+ (1,0) [0|0] "" Vector__XXX
 SG_ LS_rearMatrix50 m22 : 48|8@1+ (1,0) [0|0] "" Vector__XXX
 SG_ LS_rearMatrix57 m23 : 48|8@1+ (1,0) [0|0] "" Vector__XXX
 SG_ LS_rearMatrix8 m16 : 48|8@1+ (1,0) [0|0] "" Vector__XXX
 SG_ LS_rgbDoorFLAftBlue m3 : 48|8@1+ (1,0) [0|0] "" Vector__XXX
 SG_ LS_rgbDoorFRAftBlue m4 : 48|8@1+ (1,0) [0|0] "" Vector__XXX
 SG_ LS_rgbDoorRLAftBlue m5 : 48|8@1+ (1,0) [0|0] "" Vector__XXX
 SG_ LS_rgbDoorRRAftBlue m6 : 48|8@1+ (1,0) [0|0] "" Vector__XXX
 SG_ LS_rgbIPFRBlue m2 : 48|8@1+ (1,0) [0|0] "" Vector__XXX
 SG_ LS_lightRearTurnRightRequest m0 : 49|1@1+ (1,0) [0|0] "" Vector__XXX
 SG_ LS_powerFrontDoorRequestRight m1 : 49|3@1+ (1,0) [0|0] "" Vector__XXX
 SG_ LS_lightSideRepeaterLeftRequest m0 : 50|1@1+ (1,0) [0|0] "" Vector__XXX
 SG_ LS_lightSideRepeaterRightRequest m0 : 51|1@1+ (1,0) [0|0] "" Vector__XXX
 SG_ LS_falconDoorRequestLeft m1 : 52|3@1+ (1,0) [0|0] "" Vector__XXX
 SG_ LS_lightSideMarkerLeftRequest m0 : 52|1@1+ (1,0) [0|0] "" Vector__XXX
 SG_ LS_lightSideMarkerRightRequest m0 : 53|1@1+ (1,0) [0|0] "" Vector__XXX
 SG_ LS_lightFrontFogLeftRequest m0 : 54|1@1+ (1,0) [0|0] "" Vector__XXX
 SG_ LS_falconDoorRequestRight m1 : 55|3@1+ (1,0) [0|0] "" Vector__XXX
 SG_ LS_lightFrontFogRightRequest m0 : 55|1@1+ (1,0) [0|0] "" Vector__XXX
 SG_ LS_frontMatrix13 m8 : 56|8@1+ (1,0) [0|0] "" Vector__XXX
 SG_ LS_frontMatrix20 m9 : 56|8@1+ (1,0) [0|0] "" Vector__XXX
 SG_ LS_frontMatrix27 m10 : 56|8@1+ (1,0) [0|0] "" Vector__XXX
 SG_ LS_frontMatrix34 m11 : 56|8@1+ (1,0) [0|0] "" Vector__XXX
 SG_ LS_frontMatrix41 m12 : 56|8@1+ (1,0) [0|0] "" Vector__XXX
 SG_ LS_frontMatrix48 m13 : 56|8@1+ (1,0) [0|0] "" Vector__XXX
 SG_ LS_frontMatrix55 m14 : 56|8@1+ (1,0) [0|0] "" Vector__XXX
 SG_ LS_frontMatrix6 m7 : 56|8@1+ (1,0) [0|0] "" Vector__XXX
 SG_ LS_lightRearFogRequest m0 : 56|1@1+ (1,0) [0|0] "" Vector__XXX
 SG_ LS_offroadLightBar5 m24 : 56|8@1+ (1,0) [0|0] "" Vector__XXX
 SG_ LS_rearMatrix16 m17 : 56|8@1+ (1,0) [0|0] "" Vector__XXX
 SG_ LS_rearMatrix2 m15 : 56|8@1+ (1,0) [0|0] "" Vector__XXX
 SG_ LS_rearMatrix23 m18 : 56|8@1+ (1,0) [0|0] "" Vector__XXX
 SG_ LS_rearMatrix30 m19 : 56|8@1+ (1,0) [0|0] "" Vector__XXX
 SG_ LS_rearMatrix37 m20 : 56|8@1+ (1,0) [0|0] "" Vector__XXX
 SG_ LS_rearMatrix44 m21 : 56|8@1+ (1,0) [0|0] "" Vector__XXX
 SG_ LS_rearMatrix51 m22 : 56|8@1+ (1,0) [0|0] "" Vector__XXX
 SG_ LS_rearMatrix58 m23 : 56|8@1+ (1,0) [0|0] "" Vector__XXX
 SG_ LS_rearMatrix9 m16 : 56|8@1+ (1,0) [0|0] "" Vector__XXX
 SG_ LS_lightBrakeRequest m0 : 57|1@1+ (1,0) [0|0] "" Vector__XXX
 SG_ LS_chargePortRequest m1 : 58|2@1+ (1,0) [0|0] "" Vector__XXX
 SG_ LS_lightTailLeftRequest m0 : 58|1@1+ (1,0) [0|0] "" Vector__XXX
 SG_ LS_lightTailRightRequest m0 : 59|1@1+ (1,0) [0|0] "" Vector__XXX
 SG_ LS_chargePortRaveRequest m1 : 60|1@1+ (1,0) [0|0] "" Vector__XXX
 SG_ LS_lightLicensePlateRequest m0 : 60|1@1+ (1,0) [0|0] "" Vector__XXX
 SG_ LS_lightReverseRequest m0 : 61|1@1+ (1,0) [0|0] "" Vector__XXX
 SG_ LS_suspensionRequest m1 : 61|2@1+ (1,0) [0|0] "" Vector__XXX
 SG_ LS_lightAuxParkLeftRequest m0 : 62|1@1+ (1,0) [0|0] "" Vector__XXX
 SG_ LS_lightAuxParkRightRequest m0 : 63|1@1+ (1,0) [0|0] "" Vector__XXX

BO_ 1013 VCFRONT_lighting: 8 Vector__XXX
 SG_ VCFRONT_indicatorLeftRequest : 0|2@1+ (1,0) [0|0] "" Vector__XXX
 SG_ VCFRONT_indicatorRightRequest : 2|2@1+ (1,0) [0|0] "" Vector__XXX
 SG_ VCFRONT_hazardLightRequest : 4|4@1+ (1,0) [0|0] "" Vector__XXX
 SG_ VCFRONT_ambientLightingBrightnes : 8|8@1+ (0.5,0) [0|0] "" Vector__XXX
 SG_ VCFRONT_switchLightingBrightness : 16|8@1+ (0.5,0) [0|0] "" Vector__XXX
 SG_ VCFRONT_courtesyLightingRequest : 24|1@1+ (1,0) [0|0] "" Vector__XXX
 SG_ VCFRONT_hazardSwitchBacklight : 27|1@1+ (1,0) [0|0] "" Vector__XXX
 SG_ VCFRONT_highBeamControlState : 28|2@1+ (1,0) [0|0] "" Vector__XXX
 SG_ VCFRONT_dynamicBrakeLightState : 30|2@1+ (1,0) [0|0] "" Vector__XXX
 SG_ VCFRONT_lightingCoreState : 32|4@1+ (1,0) [0|0] "" Vector__XXX
 SG_ VCFRONT_intHighBeamsFunctionState : 36|1@1+ (1,0) [0|0] "" Vector__XXX
 SG_ VCFRONT_latchedHighBeamsFunctionState : 37|1@1+ (1,0) [0|0] "" Vector__XXX
 SG_ VCFRONT_frontFogFunctionState : 38|1@1+ (1,0) [0|0] "" Vector__XXX
 SG_ VCFRONT_headlightsReadyOrTimedOut : 39|1@1+ (1,0) [0|0] "" Vector__XXX
 SG_ VCFRONT_turnIndicatorStalk : 40|2@1+ (1,0) [0|0] "" Vector__XXX
 SG_ VCFRONT_highBeamLatchingState : 42|2@1+ (1,0) [0|0] "" Vector__XXX
 SG_ VCFRONT_lightingCustomState : 44|5@1+ (1,0) [0|0] "" Vector__XXX
 SG_ VC_fastFlashHazardsActive : 49|1@1+ (1,0) [0|0] "" Vector__XXX
 SG_ VCFRONT_indicatorLeftInternal : 50|2@1+ (1,0) [0|0] "" Vector__XXX
 SG_ VCFRONT_indicatorRightInternal : 52|2@1+ (1,0) [0|0] "" Vector__XXX

BO_ 1014 VCFRONT_lightStatus: 8 Vector__XXX
 SG_ VCFRONT_lowBeamLeftStatus : 0|2@1+ (1,0) [0|0] "" Vector__XXX
 SG_ VCFRONT_lowBeamRightStatus : 2|2@1+ (1,0) [0|0] "" Vector__XXX
 SG_ VCFRONT_highBeamLeftStatus : 4|2@1+ (1,0) [0|0] "" Vector__XXX
 SG_ VCFRONT_highBeamRightStatus : 6|2@1+ (1,0) [0|0] "" Vector__XXX
 SG_ VCFRONT_DRLLeftStatus : 8|2@1+ (1,0) [0|0] "" Vector__XXX
 SG_ VCFRONT_DRLRightStatus : 10|2@1+ (1,0) [0|0] "" Vector__XXX
 SG_ VCFRONT_fogLeftStatus : 12|2@1+ (1,0) [0|0] "" Vector__XXX
 SG_ VCFRONT_fogRightStatus : 14|2@1+ (1,0) [0|0] "" Vector__XXX
 SG_ VCFRONT_sideMarkersStatus : 16|2@1+ (1,0) [0|0] "" Vector__XXX
 SG_ VCFRONT_sideRepeaterLeftStatus : 18|2@1+ (1,0) [0|0] "" Vector__XXX
 SG_ VCFRONT_sideRepeaterRightStatus : 20|2@1+ (1,0) [0|0] "" Vector__XXX
 SG_ VCFRONT_turnSignalLeftStatus : 22|2@1+ (1,0) [0|0] "" Vector__XXX
 SG_ VCFRONT_turnSignalRightStatus : 24|2@1+ (1,0) [0|0] "" Vector__XXX
 SG_ VCFRONT_parkLeftStatus : 26|2@1+ (1,0) [0|0] "" Vector__XXX
 SG_ VCFRONT_parkRightStatus : 28|2@1+ (1,0) [0|0] "" Vector__XXX
 SG_ VCFRONT_lowBeamLeftReadyForAiming : 30|1@1+ (1,0) [0|0] "" Vector__XXX
 SG_ VCFRONT_lowBeamRightReadyForAiming : 31|1@1+ (1,0) [0|0] "" Vector__XXX
 SG_ VCFRONT_lowBeamsOnForDRL : 32|1@1+ (1,0) [0|0] "" Vector__XXX
 SG_ VC_rightHeadlampHealth : 33|3@1+ (1,0) [0|0] "" Vector__XXX
 SG_ VC_leftHeadlampHealth : 36|3@1+ (1,0) [0|0] "" Vector__XXX
 SG_ VCFRONT_lightStatusMuxIndex M : 39|3@1+ (1,0) [0|0] "" Vector__XXX
 SG_ VCFRONT_isAdaptiveHighBeamAvailable m1 : 42|1@1+ (1,0) [0|0] "" Vector__XXX
 SG_ VCFRONT_isAdaptiveHighBeamFaulted m1 : 43|1@1+ (1,0) [0|0] "" Vector__XXX
 SG_ VCFRONT_isBendLightingAvailable m1 : 44|1@1+ (1,0) [0|0] "" Vector__XXX
 SG_ VCFRONT_advancedDrivingBeamStatus m1 : 45|2@1+ (1,0) [0|0] "" Vector__XXX
 SG_ VCFRONT_headlampBendAngle m1 : 47|8@1- (0.1,0) [0|0] "" Vector__XXX
 SG_ VC_hcmlMigrationValidWeather m0 : 48|1@1+ (1,0) [0|0] "" Vector__XXX
 SG_ VC_hcmlMigrationOTAStateWasActive m0 : 49|1@1+ (1,0) [0|0] "" Vector__XXX
 SG_ VC_hcmlMigrationOTAStateNotActive m0 : 50|1@1+ (1,0) [0|0] "" Vector__XXX
 SG_ VC_hcmlMigrationVehicleUpdateActive m0 : 51|1@1+ (1,0) [0|0] "" Vector__XXX
 SG_ VC_hcmlMigrationOnLVSupport m0 : 52|1@1+ (1,0) [0|0] "" Vector__XXX
 SG_ VC_hcmlMigrationMigrationNotStarted m0 : 53|1@1+ (1,0) [0|0] "" Vector__XXX
 SG_ VC_hcmlMigrationStallDetectionEnabled m0 : 54|1@1+ (1,0) [0|0] "" Vector__XXX
 SG_ VCFRONT_headlampRoadClass m1 : 55|2@1+ (1,0) [0|0] "" Vector__XXX
 SG_ VC_hcmlMigrationWindowOpen m0 : 55|1@1+ (1,0) [0|0] "" Vector__XXX
 SG_ VC_hcmrMigrationValidWeather m0 : 56|1@1+ (1,0) [0|0] "" Vector__XXX
 SG_ VC_hcmrMigrationOTAStateWasActive m0 : 57|1@1+ (1,0) [0|0] "" Vector__XXX
 SG_ VC_hcmrMigrationOTAStateNotActive m0 : 58|1@1+ (1,0) [0|0] "" Vector__XXX
 SG_ VC_hcmrMigrationVehicleUpdateActive m0 : 59|1@1+ (1,0) [0|0] "" Vector__XXX
 SG_ VC_hcmrMigrationOnLVSupport m0 : 60|1@1+ (1,0) [0|0] "" Vector__XXX
 SG_ VC_hcmrMigrationMigrationNotStarted m0 : 61|1@1+ (1,0) [0|0] "" Vector__XXX
 SG_ VC_hcmrMigrationStallDetectionEnabled m0 : 62|1@1+ (1,0) [0|0] "" Vector__XXX
 SG_ VC_hcmrMigrationWindowOpen m0 : 63|1@1+ (1,0) [0|0] "" Vector__XXX

BO_ 1017 VCSEC_alertMatrix: 8 Vector__XXX
 SG_ VCSEC_matrixIndex M : 0|4@1+ (1,0) [0|0] "" Vector__XXX
 SG_ VCSEC_a001_WatchdogReset m0 : 4|1@1+ (1,0) [0|0] "" Vector__XXX
 SG_ VCSEC_a061_XCPConnected m1 : 4|1@1+ (1,0) [0|0] "" Vector__XXX
 SG_ VCSEC_a121_ICR_MIA m2 : 4|1@1+ (1,0) [0|0] "" Vector__XXX
 SG_ VCSEC_a181_signedMessageFault m3 : 4|1@1+ (1,0) [0|0] "" Vector__XXX
 SG_ VCSEC_a241_TPMSUpdateStartedSensor0 m4 : 4|1@1+ (1,0) [0|0] "" Vector__XXX
 SG_ VCSEC_a301_imposterDetected m5 : 4|1@1+ (1,0) [0|0] "" Vector__XXX
 SG_ VCSEC_a481_handlePullWithoutAuthNIStateDev2 m8 : 4|1@1+ (1,0) [0|0] "" Vector__XXX
 SG_ VCSEC_a002_PowerLossReset m0 : 5|1@1+ (1,0) [0|0] "" Vector__XXX
 SG_ VCSEC_a062_XCPWasConnected m1 : 5|1@1+ (1,0) [0|0] "" Vector__XXX
 SG_ VCSEC_a182_cryptoHighStackUsage m3 : 5|1@1+ (1,0) [0|0] "" Vector__XXX
 SG_ VCSEC_a242_TPMSUpdateStartedSensor1 m4 : 5|1@1+ (1,0) [0|0] "" Vector__XXX
 SG_ VCSEC_a302_unfused m5 : 5|1@1+ (1,0) [0|0] "" Vector__XXX
 SG_ VCSEC_a482_VINChanged m8 : 5|1@1+ (1,0) [0|0] "" Vector__XXX
 SG_ VCSEC_a003_SWAssertion m0 : 6|1@1+ (1,0) [0|0] "" Vector__XXX
 SG_ VCSEC_a063_SwitchFault m1 : 6|1@1+ (1,0) [0|0] "" Vector__XXX
 SG_ VCSEC_a183_centerEndpointRFMia m3 : 6|1@1+ (1,0) [0|0] "" Vector__XXX
 SG_ VCSEC_a243_TPMSUpdateStartedSensor2 m4 : 6|1@1+ (1,0) [0|0] "" Vector__XXX
 SG_ VCSEC_a303_KeyfobUpdateInterrupted m5 : 6|1@1+ (1,0) [0|0] "" Vector__XXX
 SG_ VCSEC_a483_highThermalGradiantDetected m8 : 6|1@1+ (1,0) [0|0] "" Vector__XXX
 SG_ VCSEC_a064_busSleepReqTimeout m1 : 7|1@1+ (1,0) [0|0] "" Vector__XXX
 SG_ VCSEC_a184_driverEndpointRFMia m3 : 7|1@1+ (1,0) [0|0] "" Vector__XXX
 SG_ VCSEC_a244_TPMSUpdateStartedSensor3 m4 : 7|1@1+ (1,0) [0|0] "" Vector__XXX
 SG_ VCSEC_a304_KeyfobUpdateComplete m5 : 7|1@1+ (1,0) [0|0] "" Vector__XXX
 SG_ VCSEC_a005_CANTXError m0 : 8|1@1+ (1,0) [0|0] "" Vector__XXX
 SG_ VCSEC_a185_passengerEndpointRFMia m3 : 8|1@1+ (1,0) [0|0] "" Vector__XXX
 SG_ VCSEC_a245_TPMSUpdateInterruptedSensor0 m4 : 8|1@1+ (1,0) [0|0] "" Vector__XXX
 SG_ VCSEC_a305_ATTFlowControlViolatedC m5 : 8|1@1+ (1,0) [0|0] "" Vector__XXX
 SG_ VCSEC_a006_CANTX_cyclicError m0 : 9|1@1+ (1,0) [0|0] "" Vector__XXX
 SG_ VCSEC_a186_rearEndpointRFMia m3 : 9|1@1+ (1,0) [0|0] "" Vector__XXX
 SG_ VCSEC_a246_TPMSUpdateInterruptedSensor1 m4 : 9|1@1+ (1,0) [0|0] "" Vector__XXX
 SG_ VCSEC_a306_KeyfobAdvReceivedWhileConnected m5 : 9|1@1+ (1,0) [0|0] "" Vector__XXX
 SG_ VCSEC_a187_badConnectionDropped m3 : 10|1@1+ (1,0) [0|0] "" Vector__XXX
 SG_ VCSEC_a247_TPMSUpdateInterruptedSensor2 m4 : 10|1@1+ (1,0) [0|0] "" Vector__XXX
 SG_ VCSEC_a307_ATTTimeout m5 : 10|1@1+ (1,0) [0|0] "" Vector__XXX
 SG_ VCSEC_a487_unrecognizedProto m8 : 10|1@1+ (1,0) [0|0] "" Vector__XXX
 SG_ VCSEC_a188_protobufDecodeError m3 : 11|1@1+ (1,0) [0|0] "" Vector__XXX
 SG_ VCSEC_a248_TPMSUpdateInterruptedSensor3 m4 : 11|1@1+ (1,0) [0|0] "" Vector__XXX
 SG_ VCSEC_a308_NonConnectableAdvReceived m5 : 11|1@1+ (1,0) [0|0] "" Vector__XXX
 SG_ VCSEC_a189_protoExpLengthTooLarge m3 : 12|1@1+ (1,0) [0|0] "" Vector__XXX
 SG_ VCSEC_a249_TPMSUpdateCompleteSensor0 m4 : 12|1@1+ (1,0) [0|0] "" Vector__XXX
 SG_ VCSEC_a309_serviceKeyConditionsNotMet m5 : 12|1@1+ (1,0) [0|0] "" Vector__XXX
 SG_ VCSEC_a010_ExtSupplyVoltError m0 : 13|1@1+ (1,0) [0|0] "" Vector__XXX
 SG_ VCSEC_a190_protoTooManyBytes m3 : 13|1@1+ (1,0) [0|0] "" Vector__XXX
 SG_ VCSEC_a250_TPMSUpdateCompleteSensor1 m4 : 13|1@1+ (1,0) [0|0] "" Vector__XXX
 SG_ VCSEC_a310_chargePortFilterFalsePositive m5 : 13|1@1+ (1,0) [0|0] "" Vector__XXX
 SG_ VCSEC_a191_macIDWlistingFailedC m3 : 14|1@1+ (1,0) [0|0] "" Vector__XXX
 SG_ VCSEC_a251_TPMSUpdateCompleteSensor2 m4 : 14|1@1+ (1,0) [0|0] "" Vector__XXX
 SG_ VCSEC_a311_moreThanThreeKeysPresent m5 : 14|1@1+ (1,0) [0|0] "" Vector__XXX
 SG_ VCSEC_a012_CPUReset m0 : 15|1@1+ (1,0) [0|0] "" Vector__XXX
 SG_ VCSEC_a192_macIDWlistingFailedL m3 : 15|1@1+ (1,0) [0|0] "" Vector__XXX
 SG_ VCSEC_a252_TPMSUpdateCompleteSensor3 m4 : 15|1@1+ (1,0) [0|0] "" Vector__XXX
 SG_ VCSEC_a312_unexpectedBLEDisconnect m5 : 15|1@1+ (1,0) [0|0] "" Vector__XXX
 SG_ VCSEC_a013_AlertManagerFault m0 : 16|1@1+ (1,0) [0|0] "" Vector__XXX
 SG_ VCSEC_a133_alarmTriggered m2 : 16|1@1+ (1,0) [0|0] "" Vector__XXX
 SG_ VCSEC_a193_macIDWlistingFailedRi m3 : 16|1@1+ (1,0) [0|0] "" Vector__XXX
 SG_ VCSEC_a253_TPMSLowBattery m4 : 16|1@1+ (1,0) [0|0] "" Vector__XXX
 SG_ VCSEC_a134_noVINLoaded m2 : 17|1@1+ (1,0) [0|0] "" Vector__XXX
 SG_ VCSEC_a194_macIDWlistingFailedRe m3 : 17|1@1+ (1,0) [0|0] "" Vector__XXX
 SG_ VCSEC_a254_whitelistUpdatedKey m4 : 17|1@1+ (1,0) [0|0] "" Vector__XXX
 SG_ VCSEC_a015_NVMMError m0 : 18|1@1+ (1,0) [0|0] "" Vector__XXX
 SG_ VCSEC_a135_centerEndpointBusy m2 : 18|1@1+ (1,0) [0|0] "" Vector__XXX
 SG_ VCSEC_a195_keyMissingInDrive m3 : 18|1@1+ (1,0) [0|0] "" Vector__XXX
 SG_ VCSEC_a255_wlistUpdatedPermission m4 : 18|1@1+ (1,0) [0|0] "" Vector__XXX
 SG_ VCSEC_a315_bleBondingEvent m5 : 18|1@1+ (1,0) [0|0] "" Vector__XXX
 SG_ VCSEC_a435_NFCCardPresentWhileCharging m7 : 18|1@1+ (1,0) [0|0] "" Vector__XXX
 SG_ VCSEC_a495_handlePullWithoutAuth_iOS m8 : 18|1@1+ (1,0) [0|0] "" Vector__XXX
 SG_ VCSEC_a016_NVMMRecordError m0 : 19|1@1+ (1,0) [0|0] "" Vector__XXX
 SG_ VCSEC_a136_leftEndpointBusy m2 : 19|1@1+ (1,0) [0|0] "" Vector__XXX
 SG_ VCSEC_a196_protobufTXTimeout m3 : 19|1@1+ (1,0) [0|0] "" Vector__XXX
 SG_ VCSEC_a256_whitelistOperationFail m4 : 19|1@1+ (1,0) [0|0] "" Vector__XXX
 SG_ VCSEC_a316_ltkRequestRejected m5 : 19|1@1+ (1,0) [0|0] "" Vector__XXX
 SG_ VCSEC_a436_uhfHWDoesNotMatchCountry m7 : 19|1@1+ (1,0) [0|0] "" Vector__XXX
 SG_ VCSEC_a496_handlePullWithoutAuth_Android m8 : 19|1@1+ (1,0) [0|0] "" Vector__XXX
 SG_ VCSEC_a017_NVMMStatusDbg m0 : 20|1@1+ (1,0) [0|0] "" Vector__XXX
 SG_ VCSEC_a137_rightEndpointBusy m2 : 20|1@1+ (1,0) [0|0] "" Vector__XXX
 SG_ VCSEC_a197_indicationFault m3 : 20|1@1+ (1,0) [0|0] "" Vector__XXX
 SG_ VCSEC_a257_connectedKeyIsExpiring m4 : 20|1@1+ (1,0) [0|0] "" Vector__XXX
 SG_ VCSEC_a138_rearEndpointBusy m2 : 21|1@1+ (1,0) [0|0] "" Vector__XXX
 SG_ VCSEC_a198_BPillarNFCReaderMIA m3 : 21|1@1+ (1,0) [0|0] "" Vector__XXX
 SG_ VCSEC_a258_keyIsExpiring m4 : 21|1@1+ (1,0) [0|0] "" Vector__XXX
 SG_ VCSEC_a498_TPMSFeature0Reached m8 : 21|1@1+ (1,0) [0|0] "" Vector__XXX
 SG_ VCSEC_a199_CenterNFCReaderMIA m3 : 22|1@1+ (1,0) [0|0] "" Vector__XXX
 SG_ VCSEC_a499_TPMSAssertFailure0 m8 : 22|1@1+ (1,0) [0|0] "" Vector__XXX
 SG_ VCSEC_a140_nfcAuthentication m2 : 23|1@1+ (1,0) [0|0] "" Vector__XXX
 SG_ VCSEC_a200_centerEndpointLostComm m3 : 23|1@1+ (1,0) [0|0] "" Vector__XXX
 SG_ VCSEC_a260_prsntPhoneKeyDisconnected m4 : 23|1@1+ (1,0) [0|0] "" Vector__XXX
 SG_ VCSEC_a500_TPMSAssertFailure1 m8 : 23|1@1+ (1,0) [0|0] "" Vector__XXX
 SG_ VCSEC_a021_TaskSchedulerError m0 : 24|1@1+ (1,0) [0|0] "" Vector__XXX
 SG_ VCSEC_a141_tooFewKeysOnWhitelist m2 : 24|1@1+ (1,0) [0|0] "" Vector__XXX
 SG_ VCSEC_a201_leftEndpointLostComm m3 : 24|1@1+ (1,0) [0|0] "" Vector__XXX
 SG_ VCSEC_a261_TPMSFactoryLearnActive m4 : 24|1@1+ (1,0) [0|0] "" Vector__XXX
 SG_ VCSEC_a501_TPMSAssertFailure2 m8 : 24|1@1+ (1,0) [0|0] "" Vector__XXX
 SG_ VCSEC_a022_TaskInitError m0 : 25|1@1+ (1,0) [0|0] "" Vector__XXX
 SG_ VCSEC_a082_VCRIGHT_IPC_MIA m1 : 25|1@1+ (1,0) [0|0] "" Vector__XXX
 SG_ VCSEC_a142_bleGattAlertC m2 : 25|1@1+ (1,0) [0|0] "" Vector__XXX
 SG_ VCSEC_a202_rightEndpointLostComm m3 : 25|1@1+ (1,0) [0|0] "" Vector__XXX
 SG_ VCSEC_a262_flowControlBackedUp m4 : 25|1@1+ (1,0) [0|0] "" Vector__XXX
 SG_ VCSEC_a502_TPMSAssertFailure3 m8 : 25|1@1+ (1,0) [0|0] "" Vector__XXX
 SG_ VCSEC_a083_VCLEFT_IPC_MIA m1 : 26|1@1+ (1,0) [0|0] "" Vector__XXX
 SG_ VCSEC_a143_bleGattAlertL m2 : 26|1@1+ (1,0) [0|0] "" Vector__XXX
 SG_ VCSEC_a203_rearEndpointLostComm m3 : 26|1@1+ (1,0) [0|0] "" Vector__XXX
 SG_ VCSEC_a263_dispatchCouldNotBeCompleted m4 : 26|1@1+ (1,0) [0|0] "" Vector__XXX
 SG_ VCSEC_a084_TPMS_MIA m1 : 27|1@1+ (1,0) [0|0] "" Vector__XXX
 SG_ VCSEC_a144_bleGattAlertR m2 : 27|1@1+ (1,0) [0|0] "" Vector__XXX
 SG_ VCSEC_a204_SharedSecretsWritten m3 : 27|1@1+ (1,0) [0|0] "" Vector__XXX
 SG_ VCSEC_a264_noOnePopulatedMessage m4 : 27|1@1+ (1,0) [0|0] "" Vector__XXX
 SG_ VCSEC_a085_CCCM_MIA m1 : 28|1@1+ (1,0) [0|0] "" Vector__XXX
 SG_ VCSEC_a145_bleGattAlertRe m2 : 28|1@1+ (1,0) [0|0] "" Vector__XXX
 SG_ VCSEC_a205_MTUUpdateNotConfirmed m3 : 28|1@1+ (1,0) [0|0] "" Vector__XXX
 SG_ VCSEC_a265_tooManyPopulatedMessage m4 : 28|1@1+ (1,0) [0|0] "" Vector__XXX
 SG_ VCSEC_a086_VCBATT_MIA m1 : 29|1@1+ (1,0) [0|0] "" Vector__XXX
 SG_ VCSEC_a206_BLELeftAssertFailure m3 : 29|1@1+ (1,0) [0|0] "" Vector__XXX
 SG_ VCSEC_a266_TPMSSoftWarningFrontLeft m4 : 29|1@1+ (1,0) [0|0] "" Vector__XXX
 SG_ VCSEC_a087_DIREL_MIA m1 : 30|1@1+ (1,0) [0|0] "" Vector__XXX
 SG_ VCSEC_a147_protobufRXTimeout m2 : 30|1@1+ (1,0) [0|0] "" Vector__XXX
 SG_ VCSEC_a207_BLERightAssertFailure m3 : 30|1@1+ (1,0) [0|0] "" Vector__XXX
 SG_ VCSEC_a267_TPMSSoftWarningFrontRight m4 : 30|1@1+ (1,0) [0|0] "" Vector__XXX
 SG_ VCSEC_a088_DIRER_MIA m1 : 31|1@1+ (1,0) [0|0] "" Vector__XXX
 SG_ VCSEC_a148_keyWhitelistFull m2 : 31|1@1+ (1,0) [0|0] "" Vector__XXX
 SG_ VCSEC_a208_BLERearAssertFailure m3 : 31|1@1+ (1,0) [0|0] "" Vector__XXX
 SG_ VCSEC_a268_TPMSSoftWarningRearLeft m4 : 31|1@1+ (1,0) [0|0] "" Vector__XXX
 SG_ VCSEC_a029_CoreDump m0 : 32|1@1+ (1,0) [0|0] "" Vector__XXX
 SG_ VCSEC_a089_IBST_MIA m1 : 32|1@1+ (1,0) [0|0] "" Vector__XXX
 SG_ VCSEC_a149_attrsWentMissingL m2 : 32|1@1+ (1,0) [0|0] "" Vector__XXX
 SG_ VCSEC_a209_BLECenterAssertFailure m3 : 32|1@1+ (1,0) [0|0] "" Vector__XXX
 SG_ VCSEC_a269_TPMSSoftWarningRearRight m4 : 32|1@1+ (1,0) [0|0] "" Vector__XXX
 SG_ VCSEC_a030_ECULogUploadRequest m0 : 33|1@1+ (1,0) [0|0] "" Vector__XXX
 SG_ VCSEC_a090_APS_MIA m1 : 33|1@1+ (1,0) [0|0] "" Vector__XXX
 SG_ VCSEC_a150_attrsWentMissingR m2 : 33|1@1+ (1,0) [0|0] "" Vector__XXX
 SG_ VCSEC_a210_keyDeviceBatteryLow m3 : 33|1@1+ (1,0) [0|0] "" Vector__XXX
 SG_ VCSEC_a270_TPMSHardWarningFrontLeft m4 : 33|1@1+ (1,0) [0|0] "" Vector__XXX
 SG_ VCSEC_a510_watchKeyOffWrist m8 : 33|1@1+ (1,0) [0|0] "" Vector__XXX
 SG_ VCSEC_a031_UDSActive m0 : 34|1@1+ (1,0) [0|0] "" Vector__XXX
 SG_ VCSEC_a091_CMPD_MIA m1 : 34|1@1+ (1,0) [0|0] "" Vector__XXX
 SG_ VCSEC_a151_attrsWentMissingRe m2 : 34|1@1+ (1,0) [0|0] "" Vector__XXX
 SG_ VCSEC_a211_handlePullWithoutAuth m3 : 34|1@1+ (1,0) [0|0] "" Vector__XXX
 SG_ VCSEC_a271_TPMSHardWarningFrontRight m4 : 34|1@1+ (1,0) [0|0] "" Vector__XXX
 SG_ VCSEC_a511_phoneKeyStationary m8 : 34|1@1+ (1,0) [0|0] "" Vector__XXX
 SG_ VCSEC_a092_VCSEATD_MIA m1 : 35|1@1+ (1,0) [0|0] "" Vector__XXX
 SG_ VCSEC_a212_snifferRSSIMIA m3 : 35|1@1+ (1,0) [0|0] "" Vector__XXX
 SG_ VCSEC_a272_TPMSHardWarningRearLeft m4 : 35|1@1+ (1,0) [0|0] "" Vector__XXX
 SG_ VCSEC_a093_VCSEATP_MIA m1 : 36|1@1+ (1,0) [0|0] "" Vector__XXX
 SG_ VCSEC_a153_srvcCmdTimeoutC m2 : 36|1@1+ (1,0) [0|0] "" Vector__XXX
 SG_ VCSEC_a213_gattTimeoutWithExptdCount m3 : 36|1@1+ (1,0) [0|0] "" Vector__XXX
 SG_ VCSEC_a273_TPMSHardWarningRearRight m4 : 36|1@1+ (1,0) [0|0] "" Vector__XXX
 SG_ VCSEC_a453_passiveDisabled m7 : 36|1@1+ (1,0) [0|0] "" Vector__XXX
 SG_ VCSEC_a513_TPMSConnectionStatsNotReceived0 m8 : 36|1@1+ (1,0) [0|0] "" Vector__XXX
 SG_ VCSEC_a094_EPAS3P_MIA m1 : 37|1@1+ (1,0) [0|0] "" Vector__XXX
 SG_ VCSEC_a154_srvcCmdTimeoutL m2 : 37|1@1+ (1,0) [0|0] "" Vector__XXX
 SG_ VCSEC_a214_gattServFalseWaitToBoot m3 : 37|1@1+ (1,0) [0|0] "" Vector__XXX
 SG_ VCSEC_a274_handlePullWithoutAuth2 m4 : 37|1@1+ (1,0) [0|0] "" Vector__XXX
 SG_ VCSEC_a454_TPMSOverPressureWarning m7 : 37|1@1+ (1,0) [0|0] "" Vector__XXX
 SG_ VCSEC_a514_TPMSConnectionStatsNotReceived1 m8 : 37|1@1+ (1,0) [0|0] "" Vector__XXX
 SG_ VCSEC_a095_CHG_MIA m1 : 38|1@1+ (1,0) [0|0] "" Vector__XXX
 SG_ VCSEC_a155_srvcCmdTimeoutR m2 : 38|1@1+ (1,0) [0|0] "" Vector__XXX
 SG_ VCSEC_a215_TPMSUnexpectedDisconnectSensor0 m3 : 38|1@1+ (1,0) [0|0] "" Vector__XXX
 SG_ VCSEC_a455_TPMSOverPressureWarningFrontLeft m7 : 38|1@1+ (1,0) [0|0] "" Vector__XXX
 SG_ VCSEC_a515_TPMSConnectionStatsNotReceived2 m8 : 38|1@1+ (1,0) [0|0] "" Vector__XXX
 SG_ VCSEC_a096_OCS1P_MIA m1 : 39|1@1+ (1,0) [0|0] "" Vector__XXX
 SG_ VCSEC_a156_srvcCmdTimeoutRe m2 : 39|1@1+ (1,0) [0|0] "" Vector__XXX
 SG_ VCSEC_a216_TPMSUnexpectedDisconnectSensor1 m3 : 39|1@1+ (1,0) [0|0] "" Vector__XXX
 SG_ VCSEC_a456_TPMSOverPressureWarningFrontRight m7 : 39|1@1+ (1,0) [0|0] "" Vector__XXX
 SG_ VCSEC_a516_TPMSConnectionStatsNotReceived3 m8 : 39|1@1+ (1,0) [0|0] "" Vector__XXX
 SG_ VCSEC_a097_CMP_MIA m1 : 40|1@1+ (1,0) [0|0] "" Vector__XXX
 SG_ VCSEC_a217_TPMSUnexpectedDisconnectSensor2 m3 : 40|1@1+ (1,0) [0|0] "" Vector__XXX
 SG_ VCSEC_a457_TPMSOverPressureWarningRearLeft m7 : 40|1@1+ (1,0) [0|0] "" Vector__XXX
 SG_ VCSEC_a517_TPMSOutOfRangePressureReceived0 m8 : 40|1@1+ (1,0) [0|0] "" Vector__XXX
 SG_ VCSEC_a098_DIR_MIA m1 : 41|1@1+ (1,0) [0|0] "" Vector__XXX
 SG_ VCSEC_a158_hciDebugC m2 : 41|1@1+ (1,0) [0|0] "" Vector__XXX
 SG_ VCSEC_a218_TPMSUnexpectedDisconnectSensor3 m3 : 41|1@1+ (1,0) [0|0] "" Vector__XXX
 SG_ VCSEC_a458_TPMSOverPressureWarningRearRight m7 : 41|1@1+ (1,0) [0|0] "" Vector__XXX
 SG_ VCSEC_a518_TPMSOutOfRangePressureReceived1 m8 : 41|1@1+ (1,0) [0|0] "" Vector__XXX
 SG_ VCSEC_a099_PARK_MIA m1 : 42|1@1+ (1,0) [0|0] "" Vector__XXX
 SG_ VCSEC_a159_hciDebugL m2 : 42|1@1+ (1,0) [0|0] "" Vector__XXX
 SG_ VCSEC_a219_TPMSSensorPairingRemoved m3 : 42|1@1+ (1,0) [0|0] "" Vector__XXX
 SG_ VCSEC_a459_TPMSCertCheckFailedSensor0 m7 : 42|1@1+ (1,0) [0|0] "" Vector__XXX
 SG_ VCSEC_a519_TPMSOutOfRangePressureReceived2 m8 : 42|1@1+ (1,0) [0|0] "" Vector__XXX
 SG_ VCSEC_a100_CANbus_MIA m1 : 43|1@1+ (1,0) [0|0] "" Vector__XXX
 SG_ VCSEC_a220_TPMSSensorPairingNotCompleted m3 : 43|1@1+ (1,0) [0|0] "" Vector__XXX
 SG_ VCSEC_a460_TPMSCertCheckFailedSensor1 m7 : 43|1@1+ (1,0) [0|0] "" Vector__XXX
 SG_ VCSEC_a520_TPMSOutOfRangePressureReceived3 m8 : 43|1@1+ (1,0) [0|0] "" Vector__XXX
 SG_ VCSEC_a041_HighCPULoad m0 : 44|1@1+ (1,0) [0|0] "" Vector__XXX
 SG_ VCSEC_a101_PM_MIA m1 : 44|1@1+ (1,0) [0|0] "" Vector__XXX
 SG_ VCSEC_a161_hciDebugR m2 : 44|1@1+ (1,0) [0|0] "" Vector__XXX
 SG_ VCSEC_a221_TPMSSoftWarning m3 : 44|1@1+ (1,0) [0|0] "" Vector__XXX
 SG_ VCSEC_a461_TPMSCertCheckFailedSensor2 m7 : 44|1@1+ (1,0) [0|0] "" Vector__XXX
 SG_ VCSEC_a042_HighStackUsage m0 : 45|1@1+ (1,0) [0|0] "" Vector__XXX
 SG_ VCSEC_a102_PTC_MIA m1 : 45|1@1+ (1,0) [0|0] "" Vector__XXX
 SG_ VCSEC_a162_hciDebugRe m2 : 45|1@1+ (1,0) [0|0] "" Vector__XXX
 SG_ VCSEC_a222_TPMSSystemMalfunction m3 : 45|1@1+ (1,0) [0|0] "" Vector__XXX
 SG_ VCSEC_a462_TPMSCertCheckFailedSensor3 m7 : 45|1@1+ (1,0) [0|0] "" Vector__XXX
 SG_ VCSEC_a043_Task1msError m0 : 46|1@1+ (1,0) [0|0] "" Vector__XXX
 SG_ VCSEC_a103_CP_MIA m1 : 46|1@1+ (1,0) [0|0] "" Vector__XXX
 SG_ VCSEC_a223_TPMSSensorConnectionCycling0 m3 : 46|1@1+ (1,0) [0|0] "" Vector__XXX
 SG_ VCSEC_a044_Task10msError m0 : 47|1@1+ (1,0) [0|0] "" Vector__XXX
 SG_ VCSEC_a104_DAS_MIA m1 : 47|1@1+ (1,0) [0|0] "" Vector__XXX
 SG_ VCSEC_a164_attrsWentMissingC m2 : 47|1@1+ (1,0) [0|0] "" Vector__XXX
 SG_ VCSEC_a224_TPMSSensorConnectionCycling1 m3 : 47|1@1+ (1,0) [0|0] "" Vector__XXX
 SG_ VCSEC_a045_Task100msError m0 : 48|1@1+ (1,0) [0|0] "" Vector__XXX
 SG_ VCSEC_a105_TAS_MIA m1 : 48|1@1+ (1,0) [0|0] "" Vector__XXX
 SG_ VCSEC_a165_ephemeralKeyGenerated m2 : 48|1@1+ (1,0) [0|0] "" Vector__XXX
 SG_ VCSEC_a225_TPMSSensorConnectionCycling2 m3 : 48|1@1+ (1,0) [0|0] "" Vector__XXX
 SG_ VCSEC_a046_Task1000msError m0 : 49|1@1+ (1,0) [0|0] "" Vector__XXX
 SG_ VCSEC_a106_PCS_MIA m1 : 49|1@1+ (1,0) [0|0] "" Vector__XXX
 SG_ VCSEC_a166_BLECenterPowerCycled m2 : 49|1@1+ (1,0) [0|0] "" Vector__XXX
 SG_ VCSEC_a226_TPMSSensorConnectionCycling3 m3 : 49|1@1+ (1,0) [0|0] "" Vector__XXX
 SG_ VCSEC_a107_BMS_MIA m1 : 50|1@1+ (1,0) [0|0] "" Vector__XXX
 SG_ VCSEC_a167_BLECenterSoftReset m2 : 50|1@1+ (1,0) [0|0] "" Vector__XXX
 SG_ VCSEC_a227_connectionWithoutLinkEvent m3 : 50|1@1+ (1,0) [0|0] "" Vector__XXX
 SG_ VCSEC_a108_DIF_MIA m1 : 51|1@1+ (1,0) [0|0] "" Vector__XXX
 SG_ VCSEC_a168_BLELeftSoftReset m2 : 51|1@1+ (1,0) [0|0] "" Vector__XXX
 SG_ VCSEC_a228_TPMSHardWarning m3 : 51|1@1+ (1,0) [0|0] "" Vector__XXX
 SG_ VCSEC_a109_RCM_MIA m1 : 52|1@1+ (1,0) [0|0] "" Vector__XXX
 SG_ VCSEC_a169_BLERightSoftReset m2 : 52|1@1+ (1,0) [0|0] "" Vector__XXX
 SG_ VCSEC_a110_GTW_MIA m1 : 53|1@1+ (1,0) [0|0] "" Vector__XXX
 SG_ VCSEC_a170_BLERearSoftReset m2 : 53|1@1+ (1,0) [0|0] "" Vector__XXX
 SG_ VCSEC_a111_EPBR_MIA m1 : 54|1@1+ (1,0) [0|0] "" Vector__XXX
 SG_ VCSEC_a112_EPBL_MIA m1 : 55|1@1+ (1,0) [0|0] "" Vector__XXX
 SG_ VCSEC_a172_BLEUnexpectedResetC m2 : 55|1@1+ (1,0) [0|0] "" Vector__XXX
 SG_ VCSEC_a472_peerRemovedInformation m7 : 55|1@1+ (1,0) [0|0] "" Vector__XXX
 SG_ VCSEC_a113_UI_MIA m1 : 56|1@1+ (1,0) [0|0] "" Vector__XXX
 SG_ VCSEC_a173_BLEUnexpectedResetL m2 : 56|1@1+ (1,0) [0|0] "" Vector__XXX
 SG_ VCSEC_a473_handlePullWithoutAuth3 m7 : 56|1@1+ (1,0) [0|0] "" Vector__XXX
 SG_ VCSEC_a114_ESP_MIA m1 : 57|1@1+ (1,0) [0|0] "" Vector__XXX
 SG_ VCSEC_a174_BLEUnexpectedResetRi m2 : 57|1@1+ (1,0) [0|0] "" Vector__XXX
 SG_ VCSEC_a474_handlePullWithoutAuth4 m7 : 57|1@1+ (1,0) [0|0] "" Vector__XXX
 SG_ VCSEC_a115_VCSEC_MIA m1 : 58|1@1+ (1,0) [0|0] "" Vector__XXX
 SG_ VCSEC_a175_BLEUnexpectedResetRe m2 : 58|1@1+ (1,0) [0|0] "" Vector__XXX
 SG_ VCSEC_a235_presentWithoutHandlePull m3 : 58|1@1+ (1,0) [0|0] "" Vector__XXX
 SG_ VCSEC_a475_handlePullWithoutAuth5 m7 : 58|1@1+ (1,0) [0|0] "" Vector__XXX
 SG_ VCSEC_a116_VCRIGHT_MIA m1 : 59|1@1+ (1,0) [0|0] "" Vector__XXX
 SG_ VCSEC_a236_keyIdentificationMaxAttemptReached m3 : 59|1@1+ (1,0) [0|0] "" Vector__XXX
 SG_ VCSEC_a476_handlePullWithoutAuth6 m7 : 59|1@1+ (1,0) [0|0] "" Vector__XXX
 SG_ VCSEC_a057_HVP_MIA m0 : 60|1@1+ (1,0) [0|0] "" Vector__XXX
 SG_ VCSEC_a117_VCLEFT_MIA m1 : 60|1@1+ (1,0) [0|0] "" Vector__XXX
 SG_ VCSEC_a177_whitelistAddedKey m2 : 60|1@1+ (1,0) [0|0] "" Vector__XXX
 SG_ VCSEC_a237_keyNotReadyToReceiveIDRequests m3 : 60|1@1+ (1,0) [0|0] "" Vector__XXX
 SG_ VCSEC_a477_phoneStartedBonding m7 : 60|1@1+ (1,0) [0|0] "" Vector__XXX
 SG_ VCSEC_a058_inputRHighSyncDebug m0 : 61|1@1+ (1,0) [0|0] "" Vector__XXX
 SG_ VCSEC_a118_VCFRONT_MIA m1 : 61|1@1+ (1,0) [0|0] "" Vector__XXX
 SG_ VCSEC_a178_whitelistRemovedKey m2 : 61|1@1+ (1,0) [0|0] "" Vector__XXX
 SG_ VCSEC_a238_TPMSLocationsUpdated m3 : 61|1@1+ (1,0) [0|0] "" Vector__XXX
 SG_ VCSEC_a478_handlePullWithoutAuth7 m7 : 61|1@1+ (1,0) [0|0] "" Vector__XXX
 SG_ VCSEC_a059_inputResistanceHigh m0 : 62|1@1+ (1,0) [0|0] "" Vector__XXX
 SG_ VCSEC_a119_SCCM_MIA m1 : 62|1@1+ (1,0) [0|0] "" Vector__XXX
 SG_ VCSEC_a179_wlistChangedRole m2 : 62|1@1+ (1,0) [0|0] "" Vector__XXX
 SG_ VCSEC_a239_TPMSIdleConnection m3 : 62|1@1+ (1,0) [0|0] "" Vector__XXX
 SG_ VCSEC_a479_handlePullWithoutAuthNIStateDev0 m7 : 62|1@1+ (1,0) [0|0] "" Vector__XXX
 SG_ VCSEC_a060_engineeringBuild m0 : 63|1@1+ (1,0) [0|0] "" Vector__XXX
 SG_ VCSEC_a120_DI_DRIVE_MIA m1 : 63|1@1+ (1,0) [0|0] "" Vector__XXX
 SG_ VCSEC_a180_wlistRemovedPermission m2 : 63|1@1+ (1,0) [0|0] "" Vector__XXX
 SG_ VCSEC_a240_noKeysPaired m3 : 63|1@1+ (1,0) [0|0] "" Vector__XXX
 SG_ VCSEC_a300_scheduleItKeyAdded m4 : 63|1@1+ (1,0) [0|0] "" Vector__XXX
 SG_ VCSEC_a480_handlePullWithoutAuthNIStateDev1 m7 : 63|1@1+ (1,0) [0|0] "" Vector__XXX
 SG_ VCSEC_a540_dummyAlertMax m8 : 63|1@1+ (1,0) [0|0] "" Vector__XXX

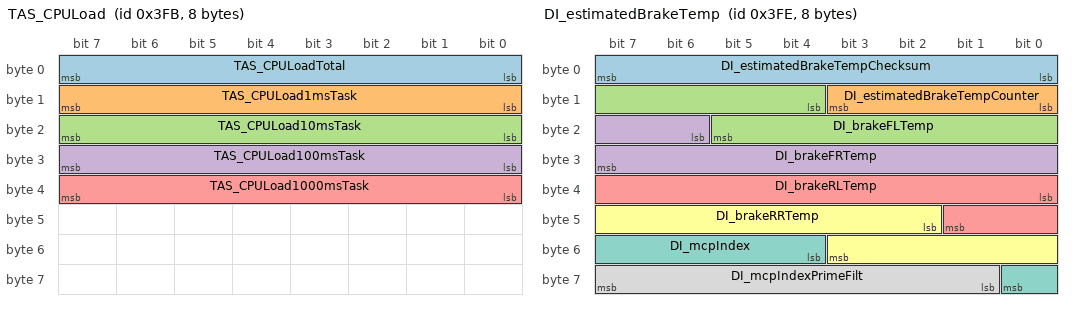
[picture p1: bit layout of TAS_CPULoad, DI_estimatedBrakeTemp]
BO_ 1019 TAS_CPULoad: 8 Vector__XXX
 SG_ TAS_CPULoadTotal : 0|8@1+ (1,0) [0|0] "" Vector__XXX
 SG_ TAS_CPULoad1msTask : 8|8@1+ (1,0) [0|0] "" Vector__XXX
 SG_ TAS_CPULoad10msTask : 16|8@1+ (1,0) [0|0] "" Vector__XXX
 SG_ TAS_CPULoad100msTask : 24|8@1+ (1,0) [0|0] "" Vector__XXX
 SG_ TAS_CPULoad1000msTask : 32|8@1+ (1,0) [0|0] "" Vector__XXX

BO_ 1021 UI_autopilotControl: 8 Vector__XXX
 SG_ UI_autopilotControlIndex M : 0|3@1+ (1,0) [0|0] "" Vector__XXX
 SG_ UI_hovEnabled m0 : 3|1@1+ (1,0) [0|0] "" Vector__XXX
 SG_ UI_donDisableAutoWiperDuration m0 : 4|3@1+ (1,0) [0|0] "" Vector__XXX
 SG_ UI_enableApproachingEmergencyVehicleDetection m2 : 5|1@1+ (1,0) [0|0] "" Vector__XXX
 SG_ UI_enableStartFsdFromParkBrakeConfirmation m2 : 6|1@1+ (1,0) [0|0] "" Vector__XXX
 SG_ UI_donDisableOnAutoWiperSpeed m0 : 7|4@1+ (1,0) [0|0] "" Vector__XXX
 SG_ UI_enableStartFsdFromPark m2 : 7|1@1+ (1,0) [0|0] "" Vector__XXX
 SG_ UI_fsdMaxSpeedOffsetPercentage m2 : 8|6@1+ (1,0) [0|0] "" Vector__XXX
 SG_ UI_selectableCameraRequest m1 : 8|4@1+ (1,0) [0|0] "" Vector__XXX
 SG_ UI_blindspotMinSpeed m0 : 11|4@1+ (1,0) [0|0] "" Vector__XXX
 SG_ UI_blindspotDistance m0 : 15|3@1+ (1,0) [0|0] "" Vector__XXX
 SG_ UI_coldStartMonarchInFactory m2 : 16|1@1+ (1,0) [0|0] "" Vector__XXX
 SG_ UI_overrideSleepWithSuspend m1 : 16|1@1+ (1,0) [0|0] "" Vector__XXX
 SG_ UI_driverMonitorConfirmation m1 : 17|1@1+ (1,0) [0|0] "" Vector__XXX
 SG_ UI_blindspotTTC m0 : 18|3@1+ (1,0) [0|0] "" Vector__XXX
 SG_ UI_parkAssistUseVision m1 : 18|1@1+ (1,0) [0|0] "" Vector__XXX
 SG_ UI_applyEceR79 m1 : 19|1@1+ (1,0) [0|0] "" Vector__XXX
 SG_ UI_enableMapStops m1 : 20|1@1+ (1,0) [0|0] "" Vector__XXX
 SG_ UI_donStopEndOfRampBuffer m0 : 21|3@1+ (1,0) [0|0] "" Vector__XXX
 SG_ UI_disableMain m1 : 23|1@1+ (1,0) [0|0] "" Vector__XXX
 SG_ UI_disableNarrow m1 : 24|1@1+ (1,0) [0|0] "" Vector__XXX
 SG_ UI_donDisableCutin m0 : 24|1@1+ (1,0) [0|0] "" Vector__XXX
 SG_ UI_disableFisheye m1 : 25|1@1+ (1,0) [0|0] "" Vector__XXX
 SG_ UI_smartSetSpeedOffset m0 : 25|6@1+ (1,-30) [0|0] "" Vector__XXX
 SG_ UI_disableLeftPillar m1 : 26|1@1+ (1,0) [0|0] "" Vector__XXX
 SG_ UI_disableRightPillar m1 : 27|1@1+ (1,0) [0|0] "" Vector__XXX
 SG_ UI_disableLeftRepeater m1 : 28|1@1+ (1,0) [0|0] "" Vector__XXX
 SG_ UI_disableRightRepeater m1 : 29|1@1+ (1,0) [0|0] "" Vector__XXX
 SG_ UI_disableBackup m1 : 30|1@1+ (1,0) [0|0] "" Vector__XXX
 SG_ UI_disableRadar m1 : 31|1@1+ (1,0) [0|0] "" Vector__XXX
 SG_ UI_smartSetSpeedOffsetType m0 : 31|1@1+ (1,0) [0|0] "" Vector__XXX
 SG_ UI_autopilotMonarchBackup m0 : 32|1@1+ (1,0) [0|0] "" Vector__XXX
 SG_ UI_noStalkConfirmAlertHaptic m1 : 32|1@1+ (1,0) [0|0] "" Vector__XXX
 SG_ UI_regulatoryLKA m1 : 33|1@1+ (1,0) [0|0] "" Vector__XXX
 SG_ UI_regulatoryLaneAssistLevel m1 : 34|1@1+ (1,0) [0|0] "" Vector__XXX
 SG_ UI_ulcSnooze m1 : 36|1@1+ (1,0) [0|0] "" Vector__XXX
 SG_ UI_fsdVisualizationEnabled m0 : 37|1@1+ (1,0) [0|0] "" Vector__XXX
 SG_ UI_noStalkConfirmAlertChime m1 : 37|1@1+ (1,0) [0|0] "" Vector__XXX
 SG_ UI_fsdStopsControlEnabled m0 : 38|1@1+ (1,0) [0|0] "" Vector__XXX
 SG_ UI_factorySummonEnable m1 : 39|1@1+ (1,0) [0|0] "" Vector__XXX
 SG_ UI_fsdContinueOnGreenWithCIPV m0 : 39|1@1+ (1,0) [0|0] "" Vector__XXX
 SG_ UI_apmv3Branch m1 : 40|3@1+ (1,0) [0|0] "" Vector__XXX
 SG_ UI_smartSetSpeed m0 : 40|1@1+ (1,0) [0|0] "" Vector__XXX
 SG_ UI_automaticSetSpeedOffset m0 : 41|1@1+ (1,0) [0|0] "" Vector__XXX
 SG_ UI_apply2021_1958_ISA m0 : 42|1@1+ (1,0) [0|0] "" Vector__XXX
 SG_ UI_apply2021_646_ELKS m0 : 43|1@1+ (1,0) [0|0] "" Vector__XXX
 SG_ UI_enableCabinCamera m1 : 43|1@1+ (1,0) [0|0] "" Vector__XXX
 SG_ UI_apply2021_1341_DDAW m0 : 44|1@1+ (1,0) [0|0] "" Vector__XXX
 SG_ UI_enableAutopilotStopWarning m1 : 44|1@1+ (1,0) [0|0] "" Vector__XXX
 SG_ UI_homelinkNearby m0 : 45|1@1+ (1,0) [0|0] "" Vector__XXX
 SG_ UI_showLaneGraph m1 : 45|1@1+ (1,0) [0|0] "" Vector__XXX
 SG_ UI_enableFullSelfDriving m0 : 46|1@1+ (1,0) [0|0] "" Vector__XXX
 SG_ UI_showTrackLabels m1 : 46|1@1+ (1,0) [0|0] "" Vector__XXX
 SG_ UI_hardCoreSummon m1 : 47|1@1+ (1,0) [0|0] "" Vector__XXX
 SG_ UI_hasFullSelfDriving m0 : 47|1@1+ (1,0) [0|0] "" Vector__XXX
 SG_ UI_autosteerActivation m0 : 48|1@1+ (1,0) [0|0] "" Vector__XXX
 SG_ UI_enableCabinCameraTelemetry m1 : 48|1@1+ (1,0) [0|0] "" Vector__XXX
 SG_ UI_autopilotDrivingProfile m0 : 49|2@1+ (1,0) [0|0] "" Vector__XXX
 SG_ UI_enableVisionSpeedControl m1 : 49|1@1+ (1,0) [0|0] "" Vector__XXX
 SG_ UI_autopilotTelemetryInChina m1 : 50|1@1+ (1,0) [0|0] "" Vector__XXX
 SG_ UI_enableTeslaAutopark m1 : 51|1@1+ (1,0) [0|0] "" Vector__XXX
 SG_ UI_fsdBetaRequest m0 : 51|1@1+ (1,0) [0|0] "" Vector__XXX
 SG_ UI_autoTurnSignalMode m1 : 52|1@1+ (1,0) [0|0] "" Vector__XXX
 SG_ UI_fullSelfDrivingSuspended m0 : 52|1@1+ (1,0) [0|0] "" Vector__XXX
 SG_ UI_disableOptionalLaneChanges m0 : 53|1@1+ (1,0) [0|0] "" Vector__XXX
 SG_ UI_enableCautionLightControl m1 : 54|1@1+ (1,0) [0|0] "" Vector__XXX
 SG_ UI_applyEceR79SmartSummonOnly m1 : 55|1@1+ (1,0) [0|0] "" Vector__XXX
 SG_ UI_autopilotMonarchEnabled m1 : 56|1@1+ (1,0) [0|0] "" Vector__XXX
 SG_ UI_autopilotEphemerisEnabled m1 : 57|1@1+ (1,0) [0|0] "" Vector__XXX
 SG_ UI_applyR152_AEBS m0 : 59|1@1+ (1,0) [0|0] "" Vector__XXX
 SG_ UI_enableCabinAudioRecording m1 : 59|1@1+ (1,0) [0|0] "" Vector__XXX
 SG_ UI_autopilotControlMux0Valid m0 : 63|1@1+ (1,0) [0|0] "" Vector__XXX
 SG_ UI_autopilotControlMux1Valid m1 : 63|1@1+ (1,0) [0|0] "" Vector__XXX
 SG_ UI_autopilotControlMux2Valid m2 : 63|1@1+ (1,0) [0|0] "" Vector__XXX

BO_ 1022 DI_estimatedBrakeTemp: 8 Vector__XXX
 SG_ DI_estimatedBrakeTempChecksum : 0|8@1+ (1,0) [0|0] "" Vector__XXX
 SG_ DI_estimatedBrakeTempCounter : 8|4@1+ (1,0) [0|0] "" Vector__XXX
 SG_ DI_brakeFLTemp : 12|10@1+ (1,-40) [0|0] "" Vector__XXX
 SG_ DI_brakeFRTemp : 22|10@1+ (1,-40) [0|0] "" Vector__XXX
 SG_ DI_brakeRLTemp : 32|10@1+ (1,-40) [0|0] "" Vector__XXX
 SG_ DI_brakeRRTemp : 42|10@1+ (1,-40) [0|0] "" Vector__XXX
 SG_ DI_mcpIndex : 52|5@1- (0.05,0.75) [0|0] "" Vector__XXX
 SG_ DI_mcpIndexPrimeFilt : 57|7@1- (0.015,0.9) [0|0] "" Vector__XXX

BO_ 1023 APS_selfTest: 8 Vector__XXX
 SG_ APS_selfTestReserved : 0|64@1+ (1,0) [0|0] "" Vector__XXX

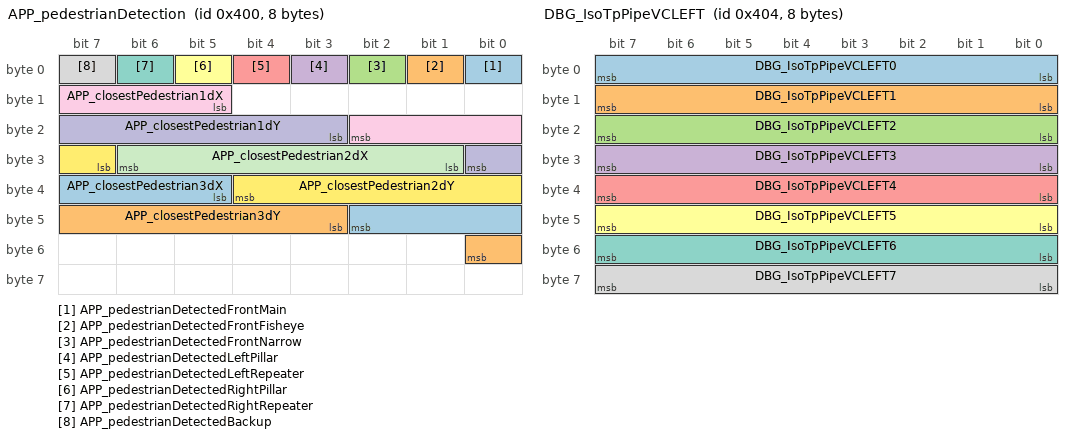
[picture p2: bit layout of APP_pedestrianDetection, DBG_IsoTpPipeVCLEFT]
BO_ 1024 APP_pedestrianDetection: 8 Vector__XXX
 SG_ APP_pedestrianDetectedFrontMain : 0|1@1+ (1,0) [0|0] "" Vector__XXX
 SG_ APP_pedestrianDetectedFrontFisheye : 1|1@1+ (1,0) [0|0] "" Vector__XXX
 SG_ APP_pedestrianDetectedFrontNarrow : 2|1@1+ (1,0) [0|0] "" Vector__XXX
 SG_ APP_pedestrianDetectedLeftPillar : 3|1@1+ (1,0) [0|0] "" Vector__XXX
 SG_ APP_pedestrianDetectedLeftRepeater : 4|1@1+ (1,0) [0|0] "" Vector__XXX
 SG_ APP_pedestrianDetectedRightPillar : 5|1@1+ (1,0) [0|0] "" Vector__XXX
 SG_ APP_pedestrianDetectedRightRepeater : 6|1@1+ (1,0) [0|0] "" Vector__XXX
 SG_ APP_pedestrianDetectedBackup : 7|1@1+ (1,0) [0|0] "" Vector__XXX
 SG_ APP_closestPedestrian1dX : 13|6@1- (0.4,0) [0|0] "" Vector__XXX
 SG_ APP_closestPedestrian1dY : 19|6@1- (0.4,0) [0|0] "" Vector__XXX
 SG_ APP_closestPedestrian2dX : 25|6@1- (0.4,0) [0|0] "" Vector__XXX
 SG_ APP_closestPedestrian2dY : 31|6@1- (0.4,0) [0|0] "" Vector__XXX
 SG_ APP_closestPedestrian3dX : 37|6@1- (0.4,0) [0|0] "" Vector__XXX
 SG_ APP_closestPedestrian3dY : 43|6@1- (0.4,0) [0|0] "" Vector__XXX

BO_ 1025 BMS_brickMeasurements: 8 Vector__XXX
 SG_ BMS_brickVoltageMultiplexer M : 0|8@1+ (1,0) [0|0] "" Vector__XXX
 SG_ BMS_brickVoltageStatus1 m0 : 8|2@1+ (1,0) [0|0] "" Vector__XXX
 SG_ BMS_brickVoltageStatus10 m3 : 8|2@1+ (1,0) [0|0] "" Vector__XXX
 SG_ BMS_brickVoltageStatus100 m33 : 8|2@1+ (1,0) [0|0] "" Vector__XXX
 SG_ BMS_brickVoltageStatus103 m34 : 8|2@1+ (1,0) [0|0] "" Vector__XXX
 SG_ BMS_brickVoltageStatus106 m35 : 8|2@1+ (1,0) [0|0] "" Vector__XXX
 SG_ BMS_brickVoltageStatus13 m4 : 8|2@1+ (1,0) [0|0] "" Vector__XXX
 SG_ BMS_brickVoltageStatus16 m5 : 8|2@1+ (1,0) [0|0] "" Vector__XXX
 SG_ BMS_brickVoltageStatus19 m6 : 8|2@1+ (1,0) [0|0] "" Vector__XXX
 SG_ BMS_brickVoltageStatus22 m7 : 8|2@1+ (1,0) [0|0] "" Vector__XXX
 SG_ BMS_brickVoltageStatus25 m8 : 8|2@1+ (1,0) [0|0] "" Vector__XXX
 SG_ BMS_brickVoltageStatus28 m9 : 8|2@1+ (1,0) [0|0] "" Vector__XXX
 SG_ BMS_brickVoltageStatus31 m10 : 8|2@1+ (1,0) [0|0] "" Vector__XXX
 SG_ BMS_brickVoltageStatus34 m11 : 8|2@1+ (1,0) [0|0] "" Vector__XXX
 SG_ BMS_brickVoltageStatus37 m12 : 8|2@1+ (1,0) [0|0] "" Vector__XXX
 SG_ BMS_brickVoltageStatus4 m1 : 8|2@1+ (1,0) [0|0] "" Vector__XXX
 SG_ BMS_brickVoltageStatus40 m13 : 8|2@1+ (1,0) [0|0] "" Vector__XXX
 SG_ BMS_brickVoltageStatus43 m14 : 8|2@1+ (1,0) [0|0] "" Vector__XXX
 SG_ BMS_brickVoltageStatus46 m15 : 8|2@1+ (1,0) [0|0] "" Vector__XXX
 SG_ BMS_brickVoltageStatus49 m16 : 8|2@1+ (1,0) [0|0] "" Vector__XXX
 SG_ BMS_brickVoltageStatus52 m17 : 8|2@1+ (1,0) [0|0] "" Vector__XXX
 SG_ BMS_brickVoltageStatus55 m18 : 8|2@1+ (1,0) [0|0] "" Vector__XXX
 SG_ BMS_brickVoltageStatus58 m19 : 8|2@1+ (1,0) [0|0] "" Vector__XXX
 SG_ BMS_brickVoltageStatus61 m20 : 8|2@1+ (1,0) [0|0] "" Vector__XXX
 SG_ BMS_brickVoltageStatus64 m21 : 8|2@1+ (1,0) [0|0] "" Vector__XXX
 SG_ BMS_brickVoltageStatus67 m22 : 8|2@1+ (1,0) [0|0] "" Vector__XXX
 SG_ BMS_brickVoltageStatus7 m2 : 8|2@1+ (1,0) [0|0] "" Vector__XXX
 SG_ BMS_brickVoltageStatus70 m23 : 8|2@1+ (1,0) [0|0] "" Vector__XXX
 SG_ BMS_brickVoltageStatus73 m24 : 8|2@1+ (1,0) [0|0] "" Vector__XXX
 SG_ BMS_brickVoltageStatus76 m25 : 8|2@1+ (1,0) [0|0] "" Vector__XXX
 SG_ BMS_brickVoltageStatus79 m26 : 8|2@1+ (1,0) [0|0] "" Vector__XXX
 SG_ BMS_brickVoltageStatus82 m27 : 8|2@1+ (1,0) [0|0] "" Vector__XXX
 SG_ BMS_brickVoltageStatus85 m28 : 8|2@1+ (1,0) [0|0] "" Vector__XXX
 SG_ BMS_brickVoltageStatus88 m29 : 8|2@1+ (1,0) [0|0] "" Vector__XXX
 SG_ BMS_brickVoltageStatus91 m30 : 8|2@1+ (1,0) [0|0] "" Vector__XXX
 SG_ BMS_brickVoltageStatus94 m31 : 8|2@1+ (1,0) [0|0] "" Vector__XXX
 SG_ BMS_brickVoltageStatus97 m32 : 8|2@1+ (1,0) [0|0] "" Vector__XXX
 SG_ BMS_brickVoltageStatus101 m33 : 10|2@1+ (1,0) [0|0] "" Vector__XXX
 SG_ BMS_brickVoltageStatus104 m34 : 10|2@1+ (1,0) [0|0] "" Vector__XXX
 SG_ BMS_brickVoltageStatus107 m35 : 10|2@1+ (1,0) [0|0] "" Vector__XXX
 SG_ BMS_brickVoltageStatus11 m3 : 10|2@1+ (1,0) [0|0] "" Vector__XXX
 SG_ BMS_brickVoltageStatus14 m4 : 10|2@1+ (1,0) [0|0] "" Vector__XXX
 SG_ BMS_brickVoltageStatus17 m5 : 10|2@1+ (1,0) [0|0] "" Vector__XXX
 SG_ BMS_brickVoltageStatus2 m0 : 10|2@1+ (1,0) [0|0] "" Vector__XXX
 SG_ BMS_brickVoltageStatus20 m6 : 10|2@1+ (1,0) [0|0] "" Vector__XXX
 SG_ BMS_brickVoltageStatus23 m7 : 10|2@1+ (1,0) [0|0] "" Vector__XXX
 SG_ BMS_brickVoltageStatus26 m8 : 10|2@1+ (1,0) [0|0] "" Vector__XXX
 SG_ BMS_brickVoltageStatus29 m9 : 10|2@1+ (1,0) [0|0] "" Vector__XXX
 SG_ BMS_brickVoltageStatus32 m10 : 10|2@1+ (1,0) [0|0] "" Vector__XXX
 SG_ BMS_brickVoltageStatus35 m11 : 10|2@1+ (1,0) [0|0] "" Vector__XXX
 SG_ BMS_brickVoltageStatus38 m12 : 10|2@1+ (1,0) [0|0] "" Vector__XXX
 SG_ BMS_brickVoltageStatus41 m13 : 10|2@1+ (1,0) [0|0] "" Vector__XXX
 SG_ BMS_brickVoltageStatus44 m14 : 10|2@1+ (1,0) [0|0] "" Vector__XXX
 SG_ BMS_brickVoltageStatus47 m15 : 10|2@1+ (1,0) [0|0] "" Vector__XXX
 SG_ BMS_brickVoltageStatus5 m1 : 10|2@1+ (1,0) [0|0] "" Vector__XXX
 SG_ BMS_brickVoltageStatus50 m16 : 10|2@1+ (1,0) [0|0] "" Vector__XXX
 SG_ BMS_brickVoltageStatus53 m17 : 10|2@1+ (1,0) [0|0] "" Vector__XXX
 SG_ BMS_brickVoltageStatus56 m18 : 10|2@1+ (1,0) [0|0] "" Vector__XXX
 SG_ BMS_brickVoltageStatus59 m19 : 10|2@1+ (1,0) [0|0] "" Vector__XXX
 SG_ BMS_brickVoltageStatus62 m20 : 10|2@1+ (1,0) [0|0] "" Vector__XXX
 SG_ BMS_brickVoltageStatus65 m21 : 10|2@1+ (1,0) [0|0] "" Vector__XXX
 SG_ BMS_brickVoltageStatus68 m22 : 10|2@1+ (1,0) [0|0] "" Vector__XXX
 SG_ BMS_brickVoltageStatus71 m23 : 10|2@1+ (1,0) [0|0] "" Vector__XXX
 SG_ BMS_brickVoltageStatus74 m24 : 10|2@1+ (1,0) [0|0] "" Vector__XXX
 SG_ BMS_brickVoltageStatus77 m25 : 10|2@1+ (1,0) [0|0] "" Vector__XXX
 SG_ BMS_brickVoltageStatus8 m2 : 10|2@1+ (1,0) [0|0] "" Vector__XXX
 SG_ BMS_brickVoltageStatus80 m26 : 10|2@1+ (1,0) [0|0] "" Vector__XXX
 SG_ BMS_brickVoltageStatus83 m27 : 10|2@1+ (1,0) [0|0] "" Vector__XXX
 SG_ BMS_brickVoltageStatus86 m28 : 10|2@1+ (1,0) [0|0] "" Vector__XXX
 SG_ BMS_brickVoltageStatus89 m29 : 10|2@1+ (1,0) [0|0] "" Vector__XXX
 SG_ BMS_brickVoltageStatus92 m30 : 10|2@1+ (1,0) [0|0] "" Vector__XXX
 SG_ BMS_brickVoltageStatus95 m31 : 10|2@1+ (1,0) [0|0] "" Vector__XXX
 SG_ BMS_brickVoltageStatus98 m32 : 10|2@1+ (1,0) [0|0] "" Vector__XXX
 SG_ BMS_brickVoltageStatus102 m33 : 12|2@1+ (1,0) [0|0] "" Vector__XXX
 SG_ BMS_brickVoltageStatus105 m34 : 12|2@1+ (1,0) [0|0] "" Vector__XXX
 SG_ BMS_brickVoltageStatus108 m35 : 12|2@1+ (1,0) [0|0] "" Vector__XXX
 SG_ BMS_brickVoltageStatus12 m3 : 12|2@1+ (1,0) [0|0] "" Vector__XXX
 SG_ BMS_brickVoltageStatus15 m4 : 12|2@1+ (1,0) [0|0] "" Vector__XXX
 SG_ BMS_brickVoltageStatus18 m5 : 12|2@1+ (1,0) [0|0] "" Vector__XXX
 SG_ BMS_brickVoltageStatus21 m6 : 12|2@1+ (1,0) [0|0] "" Vector__XXX
 SG_ BMS_brickVoltageStatus24 m7 : 12|2@1+ (1,0) [0|0] "" Vector__XXX
 SG_ BMS_brickVoltageStatus27 m8 : 12|2@1+ (1,0) [0|0] "" Vector__XXX
 SG_ BMS_brickVoltageStatus3 m0 : 12|2@1+ (1,0) [0|0] "" Vector__XXX
 SG_ BMS_brickVoltageStatus30 m9 : 12|2@1+ (1,0) [0|0] "" Vector__XXX
 SG_ BMS_brickVoltageStatus33 m10 : 12|2@1+ (1,0) [0|0] "" Vector__XXX
 SG_ BMS_brickVoltageStatus36 m11 : 12|2@1+ (1,0) [0|0] "" Vector__XXX
 SG_ BMS_brickVoltageStatus39 m12 : 12|2@1+ (1,0) [0|0] "" Vector__XXX
 SG_ BMS_brickVoltageStatus42 m13 : 12|2@1+ (1,0) [0|0] "" Vector__XXX
 SG_ BMS_brickVoltageStatus45 m14 : 12|2@1+ (1,0) [0|0] "" Vector__XXX
 SG_ BMS_brickVoltageStatus48 m15 : 12|2@1+ (1,0) [0|0] "" Vector__XXX
 SG_ BMS_brickVoltageStatus51 m16 : 12|2@1+ (1,0) [0|0] "" Vector__XXX
 SG_ BMS_brickVoltageStatus54 m17 : 12|2@1+ (1,0) [0|0] "" Vector__XXX
 SG_ BMS_brickVoltageStatus57 m18 : 12|2@1+ (1,0) [0|0] "" Vector__XXX
 SG_ BMS_brickVoltageStatus6 m1 : 12|2@1+ (1,0) [0|0] "" Vector__XXX
 SG_ BMS_brickVoltageStatus60 m19 : 12|2@1+ (1,0) [0|0] "" Vector__XXX
 SG_ BMS_brickVoltageStatus63 m20 : 12|2@1+ (1,0) [0|0] "" Vector__XXX
 SG_ BMS_brickVoltageStatus66 m21 : 12|2@1+ (1,0) [0|0] "" Vector__XXX
 SG_ BMS_brickVoltageStatus69 m22 : 12|2@1+ (1,0) [0|0] "" Vector__XXX
 SG_ BMS_brickVoltageStatus72 m23 : 12|2@1+ (1,0) [0|0] "" Vector__XXX
 SG_ BMS_brickVoltageStatus75 m24 : 12|2@1+ (1,0) [0|0] "" Vector__XXX
 SG_ BMS_brickVoltageStatus78 m25 : 12|2@1+ (1,0) [0|0] "" Vector__XXX
 SG_ BMS_brickVoltageStatus81 m26 : 12|2@1+ (1,0) [0|0] "" Vector__XXX
 SG_ BMS_brickVoltageStatus84 m27 : 12|2@1+ (1,0) [0|0] "" Vector__XXX
 SG_ BMS_brickVoltageStatus87 m28 : 12|2@1+ (1,0) [0|0] "" Vector__XXX
 SG_ BMS_brickVoltageStatus9 m2 : 12|2@1+ (1,0) [0|0] "" Vector__XXX
 SG_ BMS_brickVoltageStatus90 m29 : 12|2@1+ (1,0) [0|0] "" Vector__XXX
 SG_ BMS_brickVoltageStatus93 m30 : 12|2@1+ (1,0) [0|0] "" Vector__XXX
 SG_ BMS_brickVoltageStatus96 m31 : 12|2@1+ (1,0) [0|0] "" Vector__XXX
 SG_ BMS_brickVoltageStatus99 m32 : 12|2@1+ (1,0) [0|0] "" Vector__XXX
 SG_ BMS_brickVoltageCounter : 14|2@1+ (1,0) [0|0] "" Vector__XXX
 SG_ BMS_brickVoltage1 m0 : 16|16@1+ (0.0001,0) [0|0] "" Vector__XXX
 SG_ BMS_brickVoltage10 m3 : 16|16@1+ (0.0001,0) [0|0] "" Vector__XXX
 SG_ BMS_brickVoltage100 m33 : 16|16@1+ (0.0001,0) [0|0] "" Vector__XXX
 SG_ BMS_brickVoltage103 m34 : 16|16@1+ (0.0001,0) [0|0] "" Vector__XXX
 SG_ BMS_brickVoltage106 m35 : 16|16@1+ (0.0001,0) [0|0] "" Vector__XXX
 SG_ BMS_brickVoltage13 m4 : 16|16@1+ (0.0001,0) [0|0] "" Vector__XXX
 SG_ BMS_brickVoltage16 m5 : 16|16@1+ (0.0001,0) [0|0] "" Vector__XXX
 SG_ BMS_brickVoltage19 m6 : 16|16@1+ (0.0001,0) [0|0] "" Vector__XXX
 SG_ BMS_brickVoltage22 m7 : 16|16@1+ (0.0001,0) [0|0] "" Vector__XXX
 SG_ BMS_brickVoltage25 m8 : 16|16@1+ (0.0001,0) [0|0] "" Vector__XXX
 SG_ BMS_brickVoltage28 m9 : 16|16@1+ (0.0001,0) [0|0] "" Vector__XXX
 SG_ BMS_brickVoltage31 m10 : 16|16@1+ (0.0001,0) [0|0] "" Vector__XXX
 SG_ BMS_brickVoltage34 m11 : 16|16@1+ (0.0001,0) [0|0] "" Vector__XXX
 SG_ BMS_brickVoltage37 m12 : 16|16@1+ (0.0001,0) [0|0] "" Vector__XXX
 SG_ BMS_brickVoltage4 m1 : 16|16@1+ (0.0001,0) [0|0] "" Vector__XXX
 SG_ BMS_brickVoltage40 m13 : 16|16@1+ (0.0001,0) [0|0] "" Vector__XXX
 SG_ BMS_brickVoltage43 m14 : 16|16@1+ (0.0001,0) [0|0] "" Vector__XXX
 SG_ BMS_brickVoltage46 m15 : 16|16@1+ (0.0001,0) [0|0] "" Vector__XXX
 SG_ BMS_brickVoltage49 m16 : 16|16@1+ (0.0001,0) [0|0] "" Vector__XXX
 SG_ BMS_brickVoltage52 m17 : 16|16@1+ (0.0001,0) [0|0] "" Vector__XXX
 SG_ BMS_brickVoltage55 m18 : 16|16@1+ (0.0001,0) [0|0] "" Vector__XXX
 SG_ BMS_brickVoltage58 m19 : 16|16@1+ (0.0001,0) [0|0] "" Vector__XXX
 SG_ BMS_brickVoltage61 m20 : 16|16@1+ (0.0001,0) [0|0] "" Vector__XXX
 SG_ BMS_brickVoltage64 m21 : 16|16@1+ (0.0001,0) [0|0] "" Vector__XXX
 SG_ BMS_brickVoltage67 m22 : 16|16@1+ (0.0001,0) [0|0] "" Vector__XXX
 SG_ BMS_brickVoltage7 m2 : 16|16@1+ (0.0001,0) [0|0] "" Vector__XXX
 SG_ BMS_brickVoltage70 m23 : 16|16@1+ (0.0001,0) [0|0] "" Vector__XXX
 SG_ BMS_brickVoltage73 m24 : 16|16@1+ (0.0001,0) [0|0] "" Vector__XXX
 SG_ BMS_brickVoltage76 m25 : 16|16@1+ (0.0001,0) [0|0] "" Vector__XXX
 SG_ BMS_brickVoltage79 m26 : 16|16@1+ (0.0001,0) [0|0] "" Vector__XXX
 SG_ BMS_brickVoltage82 m27 : 16|16@1+ (0.0001,0) [0|0] "" Vector__XXX
 SG_ BMS_brickVoltage85 m28 : 16|16@1+ (0.0001,0) [0|0] "" Vector__XXX
 SG_ BMS_brickVoltage88 m29 : 16|16@1+ (0.0001,0) [0|0] "" Vector__XXX
 SG_ BMS_brickVoltage91 m30 : 16|16@1+ (0.0001,0) [0|0] "" Vector__XXX
 SG_ BMS_brickVoltage94 m31 : 16|16@1+ (0.0001,0) [0|0] "" Vector__XXX
 SG_ BMS_brickVoltage97 m32 : 16|16@1+ (0.0001,0) [0|0] "" Vector__XXX
 SG_ BMS_brickVoltage101 m33 : 32|16@1+ (0.0001,0) [0|0] "" Vector__XXX
 SG_ BMS_brickVoltage104 m34 : 32|16@1+ (0.0001,0) [0|0] "" Vector__XXX
 SG_ BMS_brickVoltage107 m35 : 32|16@1+ (0.0001,0) [0|0] "" Vector__XXX
 SG_ BMS_brickVoltage11 m3 : 32|16@1+ (0.0001,0) [0|0] "" Vector__XXX
 SG_ BMS_brickVoltage14 m4 : 32|16@1+ (0.0001,0) [0|0] "" Vector__XXX
 SG_ BMS_brickVoltage17 m5 : 32|16@1+ (0.0001,0) [0|0] "" Vector__XXX
 SG_ BMS_brickVoltage2 m0 : 32|16@1+ (0.0001,0) [0|0] "" Vector__XXX
 SG_ BMS_brickVoltage20 m6 : 32|16@1+ (0.0001,0) [0|0] "" Vector__XXX
 SG_ BMS_brickVoltage23 m7 : 32|16@1+ (0.0001,0) [0|0] "" Vector__XXX
 SG_ BMS_brickVoltage26 m8 : 32|16@1+ (0.0001,0) [0|0] "" Vector__XXX
 SG_ BMS_brickVoltage29 m9 : 32|16@1+ (0.0001,0) [0|0] "" Vector__XXX
 SG_ BMS_brickVoltage32 m10 : 32|16@1+ (0.0001,0) [0|0] "" Vector__XXX
 SG_ BMS_brickVoltage35 m11 : 32|16@1+ (0.0001,0) [0|0] "" Vector__XXX
 SG_ BMS_brickVoltage38 m12 : 32|16@1+ (0.0001,0) [0|0] "" Vector__XXX
 SG_ BMS_brickVoltage41 m13 : 32|16@1+ (0.0001,0) [0|0] "" Vector__XXX
 SG_ BMS_brickVoltage44 m14 : 32|16@1+ (0.0001,0) [0|0] "" Vector__XXX
 SG_ BMS_brickVoltage47 m15 : 32|16@1+ (0.0001,0) [0|0] "" Vector__XXX
 SG_ BMS_brickVoltage5 m1 : 32|16@1+ (0.0001,0) [0|0] "" Vector__XXX
 SG_ BMS_brickVoltage50 m16 : 32|16@1+ (0.0001,0) [0|0] "" Vector__XXX
 SG_ BMS_brickVoltage53 m17 : 32|16@1+ (0.0001,0) [0|0] "" Vector__XXX
 SG_ BMS_brickVoltage56 m18 : 32|16@1+ (0.0001,0) [0|0] "" Vector__XXX
 SG_ BMS_brickVoltage59 m19 : 32|16@1+ (0.0001,0) [0|0] "" Vector__XXX
 SG_ BMS_brickVoltage62 m20 : 32|16@1+ (0.0001,0) [0|0] "" Vector__XXX
 SG_ BMS_brickVoltage65 m21 : 32|16@1+ (0.0001,0) [0|0] "" Vector__XXX
 SG_ BMS_brickVoltage68 m22 : 32|16@1+ (0.0001,0) [0|0] "" Vector__XXX
 SG_ BMS_brickVoltage71 m23 : 32|16@1+ (0.0001,0) [0|0] "" Vector__XXX
 SG_ BMS_brickVoltage74 m24 : 32|16@1+ (0.0001,0) [0|0] "" Vector__XXX
 SG_ BMS_brickVoltage77 m25 : 32|16@1+ (0.0001,0) [0|0] "" Vector__XXX
 SG_ BMS_brickVoltage8 m2 : 32|16@1+ (0.0001,0) [0|0] "" Vector__XXX
 SG_ BMS_brickVoltage80 m26 : 32|16@1+ (0.0001,0) [0|0] "" Vector__XXX
 SG_ BMS_brickVoltage83 m27 : 32|16@1+ (0.0001,0) [0|0] "" Vector__XXX
 SG_ BMS_brickVoltage86 m28 : 32|16@1+ (0.0001,0) [0|0] "" Vector__XXX
 SG_ BMS_brickVoltage89 m29 : 32|16@1+ (0.0001,0) [0|0] "" Vector__XXX
 SG_ BMS_brickVoltage92 m30 : 32|16@1+ (0.0001,0) [0|0] "" Vector__XXX
 SG_ BMS_brickVoltage95 m31 : 32|16@1+ (0.0001,0) [0|0] "" Vector__XXX
 SG_ BMS_brickVoltage98 m32 : 32|16@1+ (0.0001,0) [0|0] "" Vector__XXX
 SG_ BMS_brickVoltage102 m33 : 48|16@1+ (0.0001,0) [0|0] "" Vector__XXX
 SG_ BMS_brickVoltage105 m34 : 48|16@1+ (0.0001,0) [0|0] "" Vector__XXX
 SG_ BMS_brickVoltage108 m35 : 48|16@1+ (0.0001,0) [0|0] "" Vector__XXX
 SG_ BMS_brickVoltage12 m3 : 48|16@1+ (0.0001,0) [0|0] "" Vector__XXX
 SG_ BMS_brickVoltage15 m4 : 48|16@1+ (0.0001,0) [0|0] "" Vector__XXX
 SG_ BMS_brickVoltage18 m5 : 48|16@1+ (0.0001,0) [0|0] "" Vector__XXX
 SG_ BMS_brickVoltage21 m6 : 48|16@1+ (0.0001,0) [0|0] "" Vector__XXX
 SG_ BMS_brickVoltage24 m7 : 48|16@1+ (0.0001,0) [0|0] "" Vector__XXX
 SG_ BMS_brickVoltage27 m8 : 48|16@1+ (0.0001,0) [0|0] "" Vector__XXX
 SG_ BMS_brickVoltage3 m0 : 48|16@1+ (0.0001,0) [0|0] "" Vector__XXX
 SG_ BMS_brickVoltage30 m9 : 48|16@1+ (0.0001,0) [0|0] "" Vector__XXX
 SG_ BMS_brickVoltage33 m10 : 48|16@1+ (0.0001,0) [0|0] "" Vector__XXX
 SG_ BMS_brickVoltage36 m11 : 48|16@1+ (0.0001,0) [0|0] "" Vector__XXX
 SG_ BMS_brickVoltage39 m12 : 48|16@1+ (0.0001,0) [0|0] "" Vector__XXX
 SG_ BMS_brickVoltage42 m13 : 48|16@1+ (0.0001,0) [0|0] "" Vector__XXX
 SG_ BMS_brickVoltage45 m14 : 48|16@1+ (0.0001,0) [0|0] "" Vector__XXX
 SG_ BMS_brickVoltage48 m15 : 48|16@1+ (0.0001,0) [0|0] "" Vector__XXX
 SG_ BMS_brickVoltage51 m16 : 48|16@1+ (0.0001,0) [0|0] "" Vector__XXX
 SG_ BMS_brickVoltage54 m17 : 48|16@1+ (0.0001,0) [0|0] "" Vector__XXX
 SG_ BMS_brickVoltage57 m18 : 48|16@1+ (0.0001,0) [0|0] "" Vector__XXX
 SG_ BMS_brickVoltage6 m1 : 48|16@1+ (0.0001,0) [0|0] "" Vector__XXX
 SG_ BMS_brickVoltage60 m19 : 48|16@1+ (0.0001,0) [0|0] "" Vector__XXX
 SG_ BMS_brickVoltage63 m20 : 48|16@1+ (0.0001,0) [0|0] "" Vector__XXX
 SG_ BMS_brickVoltage66 m21 : 48|16@1+ (0.0001,0) [0|0] "" Vector__XXX
 SG_ BMS_brickVoltage69 m22 : 48|16@1+ (0.0001,0) [0|0] "" Vector__XXX
 SG_ BMS_brickVoltage72 m23 : 48|16@1+ (0.0001,0) [0|0] "" Vector__XXX
 SG_ BMS_brickVoltage75 m24 : 48|16@1+ (0.0001,0) [0|0] "" Vector__XXX
 SG_ BMS_brickVoltage78 m25 : 48|16@1+ (0.0001,0) [0|0] "" Vector__XXX
 SG_ BMS_brickVoltage81 m26 : 48|16@1+ (0.0001,0) [0|0] "" Vector__XXX
 SG_ BMS_brickVoltage84 m27 : 48|16@1+ (0.0001,0) [0|0] "" Vector__XXX
 SG_ BMS_brickVoltage87 m28 : 48|16@1+ (0.0001,0) [0|0] "" Vector__XXX
 SG_ BMS_brickVoltage9 m2 : 48|16@1+ (0.0001,0) [0|0] "" Vector__XXX
 SG_ BMS_brickVoltage90 m29 : 48|16@1+ (0.0001,0) [0|0] "" Vector__XXX
 SG_ BMS_brickVoltage93 m30 : 48|16@1+ (0.0001,0) [0|0] "" Vector__XXX
 SG_ BMS_brickVoltage96 m31 : 48|16@1+ (0.0001,0) [0|0] "" Vector__XXX
 SG_ BMS_brickVoltage99 m32 : 48|16@1+ (0.0001,0) [0|0] "" Vector__XXX

BO_ 1027 VCFRONT1_eFuseDebugStatus: 8 Vector__XXX
 SG_ VCFRONT1_eFuseDebugStatusIndex M : 0|3@1+ (1,0) [0|0] "" Vector__XXX
 SG_ VCFRONT1_EPAS2EFuseState m0 : 3|3@1+ (1,0) [0|0] "" Vector__XXX
 SG_ VCFRONT1_autopilot2EFuseState m3 : 3|3@1+ (1,0) [0|0] "" Vector__XXX
 SG_ VCFRONT1_brakeMotorECU2EFuseState m4 : 3|3@1+ (1,0) [0|0] "" Vector__XXX
 SG_ VCFRONT1_bridgeEFuseState m5 : 3|3@1+ (1,0) [0|0] "" Vector__XXX
 SG_ VCFRONT1_pcsEFuseState m2 : 3|3@1+ (1,0) [0|0] "" Vector__XXX
 SG_ VCFRONT1_rightControllerEFuseState m1 : 3|3@1+ (1,0) [0|0] "" Vector__XXX
 SG_ VCFRONT1_EPAS2EFuseCurrent m0 : 8|12@1+ (0.05,0) [0|0] "" Vector__XXX
 SG_ VCFRONT1_autopilot2EFuseCurrent m3 : 8|12@1+ (0.05,0) [0|0] "" Vector__XXX
 SG_ VCFRONT1_brakeMotorECU2EFuseCurrent m4 : 8|12@1+ (0.05,0) [0|0] "" Vector__XXX
 SG_ VCFRONT1_bridgeEFuseCurrent m5 : 8|12@1+ (0.05,0) [0|0] "" Vector__XXX
 SG_ VCFRONT1_pcsEFuseCurrent m2 : 8|12@1+ (0.05,0) [0|0] "" Vector__XXX
 SG_ VCFRONT1_rightControllerEFuseCurrent m1 : 8|12@1+ (0.05,0) [0|0] "" Vector__XXX
 SG_ VCFRONT1_EPAS2EFuseOutput m0 : 20|1@1+ (1,0) [0|0] "" Vector__XXX
 SG_ VCFRONT1_autopilot2EFuseOutput m3 : 20|1@1+ (1,0) [0|0] "" Vector__XXX
 SG_ VCFRONT1_brakeMotorECU2EFuseOutput m4 : 20|1@1+ (1,0) [0|0] "" Vector__XXX
 SG_ VCFRONT1_bridgeEFuseOutput m5 : 20|1@1+ (1,0) [0|0] "" Vector__XXX
 SG_ VCFRONT1_pcsEFuseOutput m2 : 20|1@1+ (1,0) [0|0] "" Vector__XXX
 SG_ VCFRONT1_rightControllerEFuseOutput m1 : 20|1@1+ (1,0) [0|0] "" Vector__XXX
 SG_ VCFRONT1_EPAS2EFuseOutputDesired m0 : 21|1@1+ (1,0) [0|0] "" Vector__XXX
 SG_ VCFRONT1_autopilot2EFuseOutputDesired m3 : 21|1@1+ (1,0) [0|0] "" Vector__XXX
 SG_ VCFRONT1_brakeMotorECU2EFuseOutputDesired m4 : 21|1@1+ (1,0) [0|0] "" Vector__XXX
 SG_ VCFRONT1_bridgeEFuseOutputDesired m5 : 21|1@1+ (1,0) [0|0] "" Vector__XXX
 SG_ VCFRONT1_pcsEFuseOutputDesired m2 : 21|1@1+ (1,0) [0|0] "" Vector__XXX
 SG_ VCFRONT1_rightControllerEFuseOutputDesired m1 : 21|1@1+ (1,0) [0|0] "" Vector__XXX
 SG_ VCFRONT1_EPAS2EFuseBypass m0 : 22|1@1+ (1,0) [0|0] "" Vector__XXX
 SG_ VCFRONT1_autopilot2EFuseBypass m3 : 22|1@1+ (1,0) [0|0] "" Vector__XXX
 SG_ VCFRONT1_brakeMotorECU2EFuseBypass m4 : 22|1@1+ (1,0) [0|0] "" Vector__XXX
 SG_ VCFRONT1_bridgeEFuseBypass m5 : 22|1@1+ (1,0) [0|0] "" Vector__XXX
 SG_ VCFRONT1_pcsEFuseBypass m2 : 22|1@1+ (1,0) [0|0] "" Vector__XXX
 SG_ VCFRONT1_rightControllerEFuseBypass m1 : 22|1@1+ (1,0) [0|0] "" Vector__XXX
 SG_ VCFRONT1_EPAS2EFuseBypassDesired m0 : 23|1@1+ (1,0) [0|0] "" Vector__XXX
 SG_ VCFRONT1_autopilot2EFuseBypassDesired m3 : 23|1@1+ (1,0) [0|0] "" Vector__XXX
 SG_ VCFRONT1_brakeMotorECU2EFuseBypassDesired m4 : 23|1@1+ (1,0) [0|0] "" Vector__XXX
 SG_ VCFRONT1_bridgeEFuseBypassDesired m5 : 23|1@1+ (1,0) [0|0] "" Vector__XXX
 SG_ VCFRONT1_pcsEFuseBypassDesired m2 : 23|1@1+ (1,0) [0|0] "" Vector__XXX
 SG_ VCFRONT1_rightControllerEFuseBypassDesired m1 : 23|1@1+ (1,0) [0|0] "" Vector__XXX
 SG_ VCFRONT1_EPAS2EFuseVoltage m0 : 24|8@1+ (0.07,0) [0|0] "" Vector__XXX
 SG_ VCFRONT1_autopilot2EFuseVoltage m3 : 24|8@1+ (0.07,0) [0|0] "" Vector__XXX
 SG_ VCFRONT1_brakeMotorECU2EFuseVoltage m4 : 24|8@1+ (0.07,0) [0|0] "" Vector__XXX
 SG_ VCFRONT1_bridgeEFuseVoltage m5 : 24|8@1+ (0.07,0) [0|0] "" Vector__XXX
 SG_ VCFRONT1_pcsEFuseVoltage m2 : 24|8@1+ (0.07,0) [0|0] "" Vector__XXX
 SG_ VCFRONT1_rightControllerEFuseVoltage m1 : 24|8@1+ (0.07,0) [0|0] "" Vector__XXX
 SG_ VCFRONT1_EPAS2EFuseTemperature m0 : 32|8@1+ (1,-40) [0|0] "" Vector__XXX
 SG_ VCFRONT1_autopilot2EFuseTemperature m3 : 32|8@1+ (1,-40) [0|0] "" Vector__XXX
 SG_ VCFRONT1_brakeMotorECU2EFuseTemperature m4 : 32|8@1+ (1,-40) [0|0] "" Vector__XXX
 SG_ VCFRONT1_bridgeEFuseTemperature m5 : 32|8@1+ (1,-40) [0|0] "" Vector__XXX
 SG_ VCFRONT1_pcsEFuseTemperature m2 : 32|8@1+ (1,-40) [0|0] "" Vector__XXX
 SG_ VCFRONT1_rightControllerEFuseTemperature m1 : 32|8@1+ (1,-40) [0|0] "" Vector__XXX
 SG_ VCFRONT1_EPAS2EFuseManagerState m0 : 40|4@1+ (1,0) [0|0] "" Vector__XXX
 SG_ VCFRONT1_autopilot2EFuseManagerState m3 : 40|4@1+ (1,0) [0|0] "" Vector__XXX
 SG_ VCFRONT1_brakeMotorECU2EFuseManagerState m4 : 40|4@1+ (1,0) [0|0] "" Vector__XXX
 SG_ VCFRONT1_bridgeEFuseManagerState m5 : 40|4@1+ (1,0) [0|0] "" Vector__XXX
 SG_ VCFRONT1_pcsEFuseManagerState m2 : 40|4@1+ (1,0) [0|0] "" Vector__XXX
 SG_ VCFRONT1_rightControllerEFuseManagerState m1 : 40|4@1+ (1,0) [0|0] "" Vector__XXX
 SG_ VCFRONT1_EPAS2EFuseHardShortThreshold m0 : 44|4@1+ (1,0) [0|0] "" Vector__XXX
 SG_ VCFRONT1_autopilot2EFuseHardShortThreshold m3 : 44|4@1+ (1,0) [0|0] "" Vector__XXX
 SG_ VCFRONT1_brakeMotorECU2EFuseHardShortThreshold m4 : 44|4@1+ (1,0) [0|0] "" Vector__XXX
 SG_ VCFRONT1_bridgeEFuseHardShortThreshold m5 : 44|4@1+ (1,0) [0|0] "" Vector__XXX
 SG_ VCFRONT1_pcsEFuseHardShortThreshold m2 : 44|4@1+ (1,0) [0|0] "" Vector__XXX
 SG_ VCFRONT1_rightControllerEFuseHardShortThreshold m1 : 44|4@1+ (1,0) [0|0] "" Vector__XXX
 SG_ VCFRONT1_EPAS2EFuseOCThreshold m0 : 48|5@1+ (1,0) [0|0] "" Vector__XXX
 SG_ VCFRONT1_autopilot2EFuseOCThreshold m3 : 48|5@1+ (1,0) [0|0] "" Vector__XXX
 SG_ VCFRONT1_brakeMotorECU2EFuseOCThreshold m4 : 48|5@1+ (1,0) [0|0] "" Vector__XXX
 SG_ VCFRONT1_bridgeEFuseOCThreshold m5 : 48|5@1+ (1,0) [0|0] "" Vector__XXX
 SG_ VCFRONT1_pcsEFuseOCThreshold m2 : 48|5@1+ (1,0) [0|0] "" Vector__XXX
 SG_ VCFRONT1_rightControllerEFuseOCThreshold m1 : 48|5@1+ (1,0) [0|0] "" Vector__XXX

BO_ 1028 DBG_IsoTpPipeVCLEFT: 8 Vector__XXX
 SG_ DBG_IsoTpPipeVCLEFT0 : 0|8@1+ (1,0) [0|0] "" Vector__XXX
 SG_ DBG_IsoTpPipeVCLEFT1 : 8|8@1+ (1,0) [0|0] "" Vector__XXX
 SG_ DBG_IsoTpPipeVCLEFT2 : 16|8@1+ (1,0) [0|0] "" Vector__XXX
 SG_ DBG_IsoTpPipeVCLEFT3 : 24|8@1+ (1,0) [0|0] "" Vector__XXX
 SG_ DBG_IsoTpPipeVCLEFT4 : 32|8@1+ (1,0) [0|0] "" Vector__XXX
 SG_ DBG_IsoTpPipeVCLEFT5 : 40|8@1+ (1,0) [0|0] "" Vector__XXX
 SG_ DBG_IsoTpPipeVCLEFT6 : 48|8@1+ (1,0) [0|0] "" Vector__XXX
 SG_ DBG_IsoTpPipeVCLEFT7 : 56|8@1+ (1,0) [0|0] "" Vector__XXX

BO_ 1029 GTW_vin: 8 Vector__XXX
 SG_ GTW_vinIndex M : 7|8@0+ (1,0) [0|0] "" Vector__XXX
 SG_ GTW_vinLow m18 : 15|56@0+ (1,0) [0|0] "" Vector__XXX
 SG_ GTW_vinMid m17 : 15|56@0+ (1,0) [0|0] "" Vector__XXX
 SG_ GTW_vinHigh m16 : 47|24@0+ (1,0) [0|0] "" Vector__XXX

BO_ 1030 VCBATT1_eFuseDebugStatus: 8 Vector__XXX
 SG_ VCBATT1_eFuseDebugStatusIndex M : 0|3@1+ (1,0) [0|0] "" Vector__XXX
 SG_ VCBATT1_EPAS1EFuseState m1 : 3|3@1+ (1,0) [0|0] "" Vector__XXX
 SG_ VCBATT1_autopilot1EFuseState m3 : 3|3@1+ (1,0) [0|0] "" Vector__XXX
 SG_ VCBATT1_brakeMotorECU1EFuseState m5 : 3|3@1+ (1,0) [0|0] "" Vector__XXX
 SG_ VCBATT1_bridgeEFuseState m2 : 3|3@1+ (1,0) [0|0] "" Vector__XXX
 SG_ VCBATT1_leftControllerEFuseState m0 : 3|3@1+ (1,0) [0|0] "" Vector__XXX
 SG_ VCBATT1_loadshedEFuseState m4 : 3|3@1+ (1,0) [0|0] "" Vector__XXX
 SG_ VCBATT1_sleepBypassState m7 : 3|1@1+ (1,0) [0|0] "" Vector__XXX
 SG_ VCBATT1_sleepBypassFault m7 : 4|1@1+ (1,0) [0|0] "" Vector__XXX
 SG_ VCBATT1_EPAS1EFuseCurrent m1 : 8|12@1+ (0.05,0) [0|0] "" Vector__XXX
 SG_ VCBATT1_autopilot1EFuseCurrent m3 : 8|12@1+ (0.05,0) [0|0] "" Vector__XXX
 SG_ VCBATT1_brakeMotorECU1EFuseCurrent m5 : 8|12@1+ (0.05,0) [0|0] "" Vector__XXX
 SG_ VCBATT1_bridgeEFuseCurrent m2 : 8|12@1+ (0.05,0) [0|0] "" Vector__XXX
 SG_ VCBATT1_leftControllerEFuseCurrent m0 : 8|12@1+ (0.05,0) [0|0] "" Vector__XXX
 SG_ VCBATT1_loadshedEFuseCurrent m4 : 8|12@1+ (0.05,0) [0|0] "" Vector__XXX
 SG_ VCBATT1_mcuLogicCurrent m6 : 8|8@1+ (0.5,0) [0|0] "" Vector__XXX
 SG_ VCBATT1_sleepBypassCurrent m7 : 8|16@1+ (0.1,0) [0|0] "" Vector__XXX
 SG_ VCBATT1_mcuLogicVoltage m6 : 16|8@1+ (0.1,0) [0|0] "" Vector__XXX
 SG_ VCBATT1_EPAS1EFuseOutput m1 : 20|1@1+ (1,0) [0|0] "" Vector__XXX
 SG_ VCBATT1_autopilot1EFuseOutput m3 : 20|1@1+ (1,0) [0|0] "" Vector__XXX
 SG_ VCBATT1_brakeMotorECU1EFuseOutput m5 : 20|1@1+ (1,0) [0|0] "" Vector__XXX
 SG_ VCBATT1_bridgeEFuseOutput m2 : 20|1@1+ (1,0) [0|0] "" Vector__XXX
 SG_ VCBATT1_leftControllerEFuseOutput m0 : 20|1@1+ (1,0) [0|0] "" Vector__XXX
 SG_ VCBATT1_loadshedEFuseOutput m4 : 20|1@1+ (1,0) [0|0] "" Vector__XXX
 SG_ VCBATT1_EPAS1EFuseOutputDesired m1 : 21|1@1+ (1,0) [0|0] "" Vector__XXX
 SG_ VCBATT1_autopilot1EFuseOutputDesired m3 : 21|1@1+ (1,0) [0|0] "" Vector__XXX
 SG_ VCBATT1_brakeMotorECU1EFuseOutputDesired m5 : 21|1@1+ (1,0) [0|0] "" Vector__XXX
 SG_ VCBATT1_bridgeEFuseOutputDesired m2 : 21|1@1+ (1,0) [0|0] "" Vector__XXX
 SG_ VCBATT1_leftControllerEFuseOutputDesired m0 : 21|1@1+ (1,0) [0|0] "" Vector__XXX
 SG_ VCBATT1_loadshedEFuseOutputDesired m4 : 21|1@1+ (1,0) [0|0] "" Vector__XXX
 SG_ VCBATT1_EPAS1EFuseBypass m1 : 22|1@1+ (1,0) [0|0] "" Vector__XXX
 SG_ VCBATT1_autopilot1EFuseBypass m3 : 22|1@1+ (1,0) [0|0] "" Vector__XXX
 SG_ VCBATT1_brakeMotorECU1EFuseBypass m5 : 22|1@1+ (1,0) [0|0] "" Vector__XXX
 SG_ VCBATT1_bridgeEFuseBypass m2 : 22|1@1+ (1,0) [0|0] "" Vector__XXX
 SG_ VCBATT1_leftControllerEFuseBypass m0 : 22|1@1+ (1,0) [0|0] "" Vector__XXX
 SG_ VCBATT1_loadshedEFuseBypass m4 : 22|1@1+ (1,0) [0|0] "" Vector__XXX
 SG_ VCBATT1_EPAS1EFuseBypassDesired m1 : 23|1@1+ (1,0) [0|0] "" Vector__XXX
 SG_ VCBATT1_autopilot1EFuseBypassDesired m3 : 23|1@1+ (1,0) [0|0] "" Vector__XXX
 SG_ VCBATT1_brakeMotorECU1EFuseBypassDesired m5 : 23|1@1+ (1,0) [0|0] "" Vector__XXX
 SG_ VCBATT1_bridgeEFuseBypassDesired m2 : 23|1@1+ (1,0) [0|0] "" Vector__XXX
 SG_ VCBATT1_leftControllerEFuseBypassDesired m0 : 23|1@1+ (1,0) [0|0] "" Vector__XXX
 SG_ VCBATT1_loadshedEFuseBypassDesired m4 : 23|1@1+ (1,0) [0|0] "" Vector__XXX
 SG_ VCBATT1_EPAS1EFuseVoltage m1 : 24|8@1+ (0.07,0) [0|0] "" Vector__XXX
 SG_ VCBATT1_autopilot1EFuseVoltage m3 : 24|8@1+ (0.07,0) [0|0] "" Vector__XXX
 SG_ VCBATT1_brakeMotorECU1EFuseVoltage m5 : 24|8@1+ (0.07,0) [0|0] "" Vector__XXX
 SG_ VCBATT1_bridgeEFuseVoltage m2 : 24|8@1+ (0.07,0) [0|0] "" Vector__XXX
 SG_ VCBATT1_leftControllerEFuseVoltage m0 : 24|8@1+ (0.07,0) [0|0] "" Vector__XXX
 SG_ VCBATT1_loadshedEFuseVoltage m4 : 24|8@1+ (0.07,0) [0|0] "" Vector__XXX
 SG_ VCBATT1_sleepBypassVoltage m7 : 24|16@1+ (0.1,0) [0|0] "" Vector__XXX
 SG_ VCBATT1_EPAS1EFuseTemperature m1 : 32|8@1+ (1,-40) [0|0] "" Vector__XXX
 SG_ VCBATT1_autopilot1EFuseTemperature m3 : 32|8@1+ (1,-40) [0|0] "" Vector__XXX
 SG_ VCBATT1_brakeMotorECU1EFuseTemperature m5 : 32|8@1+ (1,-40) [0|0] "" Vector__XXX
 SG_ VCBATT1_bridgeEFuseTemperature m2 : 32|8@1+ (1,-40) [0|0] "" Vector__XXX
 SG_ VCBATT1_leftControllerEFuseTemperature m0 : 32|8@1+ (1,-40) [0|0] "" Vector__XXX
 SG_ VCBATT1_loadshedEFuseTemperature m4 : 32|8@1+ (1,-40) [0|0] "" Vector__XXX
 SG_ VCBATT1_EPAS1EFuseManagerState m1 : 40|4@1+ (1,0) [0|0] "" Vector__XXX
 SG_ VCBATT1_autopilot1EFuseManagerState m3 : 40|4@1+ (1,0) [0|0] "" Vector__XXX
 SG_ VCBATT1_brakeMotorECU1EFuseManagerState m5 : 40|4@1+ (1,0) [0|0] "" Vector__XXX
 SG_ VCBATT1_bridgeEFuseManagerState m2 : 40|4@1+ (1,0) [0|0] "" Vector__XXX
 SG_ VCBATT1_leftControllerEFuseManagerState m0 : 40|4@1+ (1,0) [0|0] "" Vector__XXX
 SG_ VCBATT1_loadshedEFuseManagerState m4 : 40|4@1+ (1,0) [0|0] "" Vector__XXX
 SG_ VCBATT1_EPAS1EFuseHardShortThreshold m1 : 44|4@1+ (1,0) [0|0] "" Vector__XXX
 SG_ VCBATT1_autopilot1EFuseHardShortThreshold m3 : 44|4@1+ (1,0) [0|0] "" Vector__XXX
 SG_ VCBATT1_brakeMotorECU1EFuseHardShortThreshold m5 : 44|4@1+ (1,0) [0|0] "" Vector__XXX
 SG_ VCBATT1_bridgeEFuseHardShortThreshold m2 : 44|4@1+ (1,0) [0|0] "" Vector__XXX
 SG_ VCBATT1_leftControllerEFuseHardShortThreshold m0 : 44|4@1+ (1,0) [0|0] "" Vector__XXX
 SG_ VCBATT1_loadshedEFuseHardShortThreshold m4 : 44|4@1+ (1,0) [0|0] "" Vector__XXX
 SG_ VCBATT1_EPAS1EFuseOCThreshold m1 : 48|5@1+ (1,0) [0|0] "" Vector__XXX
 SG_ VCBATT1_autopilot1EFuseOCThreshold m3 : 48|5@1+ (1,0) [0|0] "" Vector__XXX
 SG_ VCBATT1_brakeMotorECU1EFuseOCThreshold m5 : 48|5@1+ (1,0) [0|0] "" Vector__XXX
 SG_ VCBATT1_bridgeEFuseOCThreshold m2 : 48|5@1+ (1,0) [0|0] "" Vector__XXX
 SG_ VCBATT1_leftControllerEFuseOCThreshold m0 : 48|5@1+ (1,0) [0|0] "" Vector__XXX
 SG_ VCBATT1_loadshedEFuseOCThreshold m4 : 48|5@1+ (1,0) [0|0] "" Vector__XXX

BO_ 1031 DAS_bodyControls2: 8 Vector__XXX
 SG_ DAS_bodyControls2Checksum : 0|8@1+ (1,0) [0|0] "" Vector__XXX
 SG_ DAS_bodyControls2Counter : 8|4@1+ (1,0) [0|0] "" Vector__XXX
 SG_ DAS_narrowWiperWashRequest : 12|1@1+ (1,0) [0|0] "" Vector__XXX
 SG_ DAS_narrowWipeRequest : 13|1@1+ (1,0) [0|0] "" Vector__XXX
 SG_ DAS_fluidCleanFasciaCmd : 14|1@1+ (1,0) [0|0] "" Vector__XXX
 SG_ DAS_fluidCleanLeftRepeaterCmd : 15|1@1+ (1,0) [0|0] "" Vector__XXX
 SG_ DAS_fluidCleanRightRepeaterCmd : 16|1@1+ (1,0) [0|0] "" Vector__XXX
 SG_ DAS_fluidCleanPillarBackupCmd : 17|1@1+ (1,0) [0|0] "" Vector__XXX
 SG_ DAS_airCleanRepeaterCmd : 18|1@1+ (1,0) [0|0] "" Vector__XXX
 SG_ DAS_airCleanPillarBackupCmd : 19|1@1+ (1,0) [0|0] "" Vector__XXX
 SG_ DAS_airTankDischargeCmd : 20|1@1+ (1,0) [0|0] "" Vector__XXX
 SG_ DAS_parkingLightDimRequest : 21|1@1+ (1,0) [0|0] "" Vector__XXX
 SG_ DAS_hornRequest : 22|2@1+ (1,0) [0|0] "" Vector__XXX
 SG_ DAS_trunkRequest : 24|2@1+ (1,0) [0|0] "" Vector__XXX
 SG_ DAS_windowRequest : 26|3@1+ (1,0) [0|0] "" Vector__XXX
 SG_ DAS_windowRequestActiveFL : 29|1@1+ (1,0) [0|0] "" Vector__XXX
 SG_ DAS_windowRequestActiveFR : 30|1@1+ (1,0) [0|0] "" Vector__XXX
 SG_ DAS_windowRequestActiveRL : 31|1@1+ (1,0) [0|0] "" Vector__XXX
 SG_ DAS_windowRequestActiveRR : 32|1@1+ (1,0) [0|0] "" Vector__XXX
 SG_ DAS_frunkRequest : 33|2@1+ (1,0) [0|0] "" Vector__XXX
 SG_ DAS_doorLockRequestFL : 35|2@1+ (1,0) [0|0] "" Vector__XXX
 SG_ DAS_doorLockRequestFR : 37|2@1+ (1,0) [0|0] "" Vector__XXX
 SG_ DAS_doorLockRequestRL : 39|2@1+ (1,0) [0|0] "" Vector__XXX
 SG_ DAS_doorLockRequestRR : 41|2@1+ (1,0) [0|0] "" Vector__XXX
 SG_ DAS_rearTrunkLockRequest : 43|2@1+ (1,0) [0|0] "" Vector__XXX
 SG_ DAS_lightingAnimationRequest : 45|3@1+ (1,0) [0|0] "" Vector__XXX

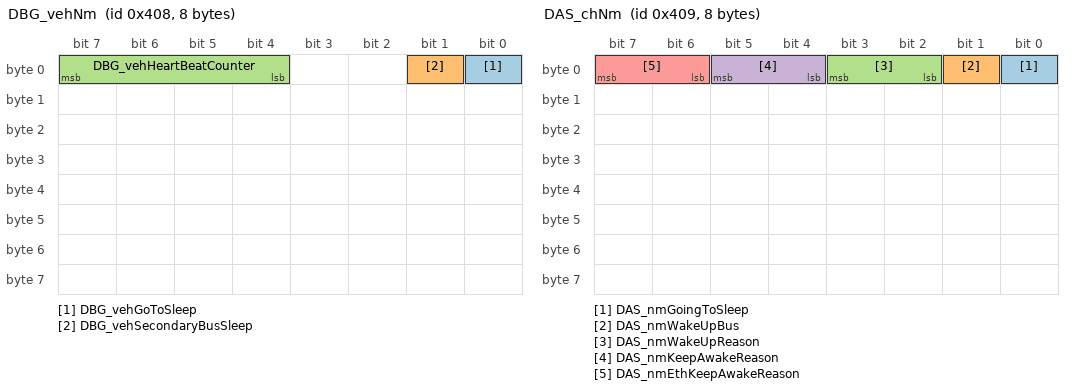
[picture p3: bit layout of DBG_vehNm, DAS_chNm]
BO_ 1032 DBG_vehNm: 8 Vector__XXX
 SG_ DBG_vehGoToSleep : 0|1@1+ (1,0) [0|0] "" Vector__XXX
 SG_ DBG_vehSecondaryBusSleep : 1|1@1+ (1,0) [0|0] "" Vector__XXX
 SG_ DBG_vehHeartBeatCounter : 4|4@1+ (1,0) [0|0] "" Vector__XXX

BO_ 1033 DAS_chNm: 8 Vector__XXX
 SG_ DAS_nmGoingToSleep : 0|1@1+ (1,0) [0|0] "" Vector__XXX
 SG_ DAS_nmWakeUpBus : 1|1@1+ (1,0) [0|0] "" Vector__XXX
 SG_ DAS_nmWakeUpReason : 2|2@1+ (1,0) [0|0] "" Vector__XXX
 SG_ DAS_nmKeepAwakeReason : 4|2@1+ (1,0) [0|0] "" Vector__XXX
 SG_ DAS_nmEthKeepAwakeReason : 6|2@1+ (1,0) [0|0] "" Vector__XXX

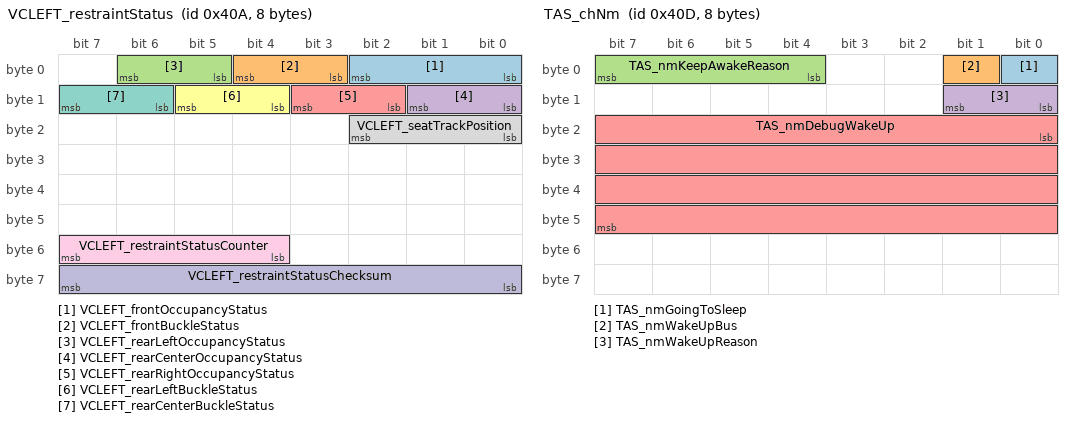
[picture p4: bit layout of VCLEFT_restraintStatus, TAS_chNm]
BO_ 1034 VCLEFT_restraintStatus: 8 Vector__XXX
 SG_ VCLEFT_frontOccupancyStatus : 0|3@1+ (1,0) [0|0] "" Vector__XXX
 SG_ VCLEFT_frontBuckleStatus : 3|2@1+ (1,0) [0|0] "" Vector__XXX
 SG_ VCLEFT_rearLeftOccupancyStatus : 5|2@1+ (1,0) [0|0] "" Vector__XXX
 SG_ VCLEFT_rearCenterOccupancyStatus : 8|2@1+ (1,0) [0|0] "" Vector__XXX
 SG_ VCLEFT_rearRightOccupancyStatus : 10|2@1+ (1,0) [0|0] "" Vector__XXX
 SG_ VCLEFT_rearLeftBuckleStatus : 12|2@1+ (1,0) [0|0] "" Vector__XXX
 SG_ VCLEFT_rearCenterBuckleStatus : 14|2@1+ (1,0) [0|0] "" Vector__XXX
 SG_ VCLEFT_seatTrackPosition : 16|3@1+ (1,0) [0|0] "" Vector__XXX
 SG_ VCLEFT_restraintStatusCounter : 52|4@1+ (1,0) [0|0] "" Vector__XXX
 SG_ VCLEFT_restraintStatusChecksum : 56|8@1+ (1,0) [0|0] "" Vector__XXX

BO_ 1037 TAS_chNm: 8 Vector__XXX
 SG_ TAS_nmGoingToSleep : 0|1@1+ (1,0) [0|0] "" Vector__XXX
 SG_ TAS_nmWakeUpBus : 1|1@1+ (1,0) [0|0] "" Vector__XXX
 SG_ TAS_nmKeepAwakeReason : 4|4@1+ (1,0) [0|0] "" Vector__XXX
 SG_ TAS_nmWakeUpReason : 8|2@1+ (1,0) [0|0] "" Vector__XXX
 SG_ TAS_nmDebugWakeUp : 16|32@1+ (1,0) [0|0] "" Vector__XXX

BO_ 1039 PCS2_v2xInfo2: 8 Vector__XXX
 SG_ PCS2_v2xUserPower : 0|10@1- (0.05,0) [0|0] "" Vector__XXX
 SG_ PCS2_v2xMaxChargePowerAvailable : 16|8@1+ (0.1,0) [0|0] "" Vector__XXX

BO_ 1042 BMS_xcpResponse: 8 Vector__XXX
 SG_ BMS_xcpResponse : 0|64@1+ (1,0) [0|0] "" Vector__XXX

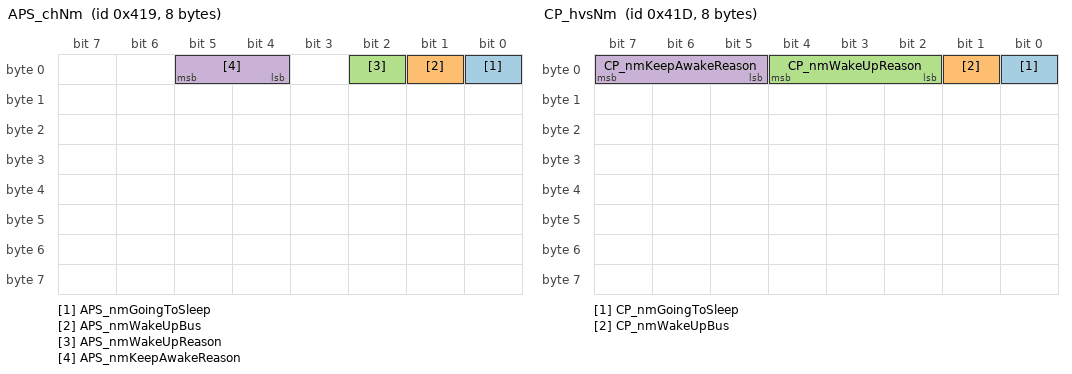
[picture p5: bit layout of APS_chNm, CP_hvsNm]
BO_ 1049 APS_chNm: 8 Vector__XXX
 SG_ APS_nmGoingToSleep : 0|1@1+ (1,0) [0|0] "" Vector__XXX
 SG_ APS_nmWakeUpBus : 1|1@1+ (1,0) [0|0] "" Vector__XXX
 SG_ APS_nmWakeUpReason : 2|1@1+ (1,0) [0|0] "" Vector__XXX
 SG_ APS_nmKeepAwakeReason : 4|2@1+ (1,0) [0|0] "" Vector__XXX

BO_ 1053 CP_hvsNm: 8 Vector__XXX
 SG_ CP_nmGoingToSleep : 0|1@1+ (1,0) [0|0] "" Vector__XXX
 SG_ CP_nmWakeUpBus : 1|1@1+ (1,0) [0|0] "" Vector__XXX
 SG_ CP_nmWakeUpReason : 2|3@1+ (1,0) [0|0] "" Vector__XXX
 SG_ CP_nmKeepAwakeReason : 5|3@1+ (1,0) [0|0] "" Vector__XXX

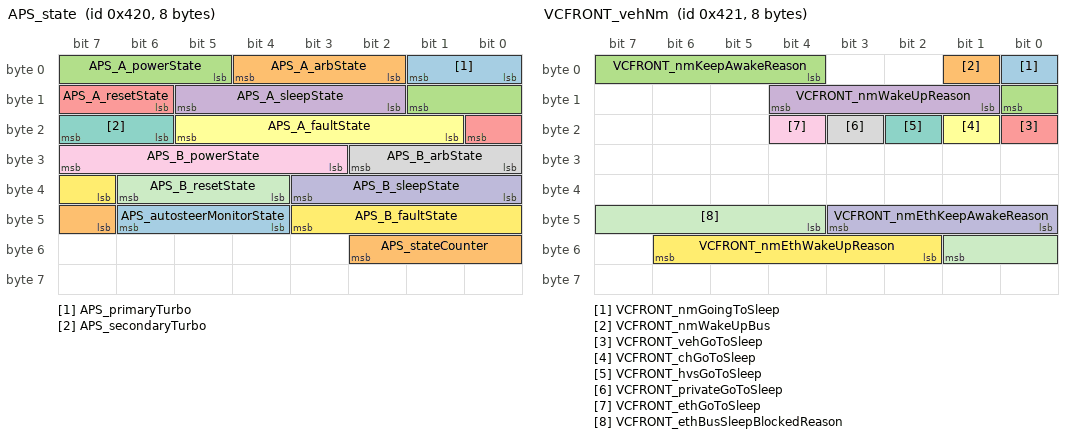
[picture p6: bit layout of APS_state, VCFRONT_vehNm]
BO_ 1056 APS_state: 8 Vector__XXX
 SG_ APS_primaryTurbo : 0|2@1+ (1,0) [0|0] "" Vector__XXX
 SG_ APS_A_arbState : 2|3@1+ (1,0) [0|0] "" Vector__XXX
 SG_ APS_A_powerState : 5|5@1+ (1,0) [0|0] "" Vector__XXX
 SG_ APS_A_sleepState : 10|4@1+ (1,0) [0|0] "" Vector__XXX
 SG_ APS_A_resetState : 14|3@1+ (1,0) [0|0] "" Vector__XXX
 SG_ APS_A_faultState : 17|5@1+ (1,0) [0|0] "" Vector__XXX
 SG_ APS_secondaryTurbo : 22|2@1+ (1,0) [0|0] "" Vector__XXX
 SG_ APS_B_arbState : 24|3@1+ (1,0) [0|0] "" Vector__XXX
 SG_ APS_B_powerState : 27|5@1+ (1,0) [0|0] "" Vector__XXX
 SG_ APS_B_sleepState : 32|4@1+ (1,0) [0|0] "" Vector__XXX
 SG_ APS_B_resetState : 36|3@1+ (1,0) [0|0] "" Vector__XXX
 SG_ APS_B_faultState : 39|5@1+ (1,0) [0|0] "" Vector__XXX
 SG_ APS_autosteerMonitorState : 44|3@1+ (1,0) [0|0] "" Vector__XXX
 SG_ APS_stateCounter : 47|4@1+ (1,0) [0|0] "" Vector__XXX

BO_ 1057 VCFRONT_vehNm: 8 Vector__XXX
 SG_ VCFRONT_nmGoingToSleep : 0|1@1+ (1,0) [0|0] "" Vector__XXX
 SG_ VCFRONT_nmWakeUpBus : 1|1@1+ (1,0) [0|0] "" Vector__XXX
 SG_ VCFRONT_nmKeepAwakeReason : 4|5@1+ (1,0) [0|0] "" Vector__XXX
 SG_ VCFRONT_nmWakeUpReason : 9|4@1+ (1,0) [0|0] "" Vector__XXX
 SG_ VCFRONT_vehGoToSleep : 16|1@1+ (1,0) [0|0] "" Vector__XXX
 SG_ VCFRONT_chGoToSleep : 17|1@1+ (1,0) [0|0] "" Vector__XXX
 SG_ VCFRONT_hvsGoToSleep : 18|1@1+ (1,0) [0|0] "" Vector__XXX
 SG_ VCFRONT_privateGoToSleep : 19|1@1+ (1,0) [0|0] "" Vector__XXX
 SG_ VCFRONT_ethGoToSleep : 20|1@1+ (1,0) [0|0] "" Vector__XXX
 SG_ VCFRONT_nmEthKeepAwakeReason : 40|4@1+ (1,0) [0|0] "" Vector__XXX
 SG_ VCFRONT_ethBusSleepBlockedReason : 44|6@1+ (1,0) [0|0] "" Vector__XXX
 SG_ VCFRONT_nmEthWakeUpReason : 50|5@1+ (1,0) [0|0] "" Vector__XXX

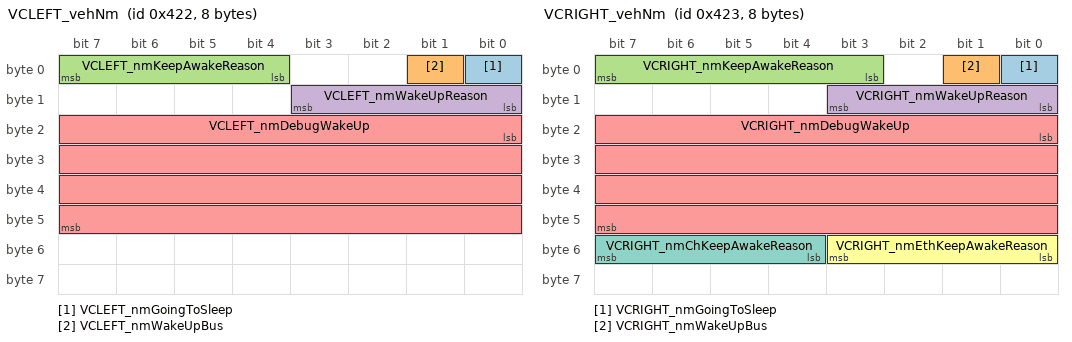
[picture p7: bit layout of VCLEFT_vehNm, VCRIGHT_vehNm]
BO_ 1058 VCLEFT_vehNm: 8 Vector__XXX
 SG_ VCLEFT_nmGoingToSleep : 0|1@1+ (1,0) [0|0] "" Vector__XXX
 SG_ VCLEFT_nmWakeUpBus : 1|1@1+ (1,0) [0|0] "" Vector__XXX
 SG_ VCLEFT_nmKeepAwakeReason : 4|4@1+ (1,0) [0|0] "" Vector__XXX
 SG_ VCLEFT_nmWakeUpReason : 8|4@1+ (1,0) [0|0] "" Vector__XXX
 SG_ VCLEFT_nmDebugWakeUp : 16|32@1+ (1,0) [0|0] "" Vector__XXX

BO_ 1059 VCRIGHT_vehNm: 8 Vector__XXX
 SG_ VCRIGHT_nmGoingToSleep : 0|1@1+ (1,0) [0|0] "" Vector__XXX
 SG_ VCRIGHT_nmWakeUpBus : 1|1@1+ (1,0) [0|0] "" Vector__XXX
 SG_ VCRIGHT_nmKeepAwakeReason : 3|5@1+ (1,0) [0|0] "" Vector__XXX
 SG_ VCRIGHT_nmWakeUpReason : 8|4@1+ (1,0) [0|0] "" Vector__XXX
 SG_ VCRIGHT_nmDebugWakeUp : 16|32@1+ (1,0) [0|0] "" Vector__XXX
 SG_ VCRIGHT_nmEthKeepAwakeReason : 48|4@1+ (1,0) [0|0] "" Vector__XXX
 SG_ VCRIGHT_nmChKeepAwakeReason : 52|4@1+ (1,0) [0|0] "" Vector__XXX
